VERSION ""

NS_ :

BS_:

BU_: PowertrainControlModule AtmosphericSensor SafetyRestraintSystem2 Aftertreatment_2_GasOutlet Aftertreatment_2_GasIntake DieselParticulateFilterControl Turbocharger SafetyRestraintSystem1 CabDisplay2 Aftertreatment_1_GasOutlet Aftertreatment_1_GasIntake OnBoardDataLogger OffBoardDiagnosticTool2 OffBoardDiagnosticTool1 FileServer ParkingBrakeController SeatController2 FanDriveController SteeringColumnUnit CommunicationUnitRadio CommunicationUnitSatellite CommunicationUnitCellular PropulsionBatteryCharger ChassisController2 ChassisController1 EngineValveControl AuxiliaryHeater2 AuxiliaryHeater1 ClutchUnit RampControl InformationSystem1 SuspensionSystemController2 OilSensor VehicleDynamicStability ExhaustEmissionController TransmissionDisplay2 TransmissionDisplay1 ClimateControl2 WaterPumpController RearAxleSteeringController LightingOperatorControl SeatController1 IgnitionController2 IgnitionController1 TirePressureController CabController2 CabController1 PneumaticSystemController SuspensionSystemController1 HydraulicPumpController EnduranceBrakingSystem RetarderExhaustEngine2 OnBoardDiagnosticUnit HeadwayController RetarderExhaustEngine1 CabDisplay1 ManagementComputer VirtualTerminal OffVehicleGateway PowerTakeOffFront HitchControl AuxiliaryValveControl BodyController TractorTrailerBridge1 StarterSystem ElectricalSystem VehicleSecurity VehicleNavigation AerodynamicControl ElectricalChargingSystem ClimateControl1 TripRecorder InstrumentCluster SuspensionDriveAxle2 SuspensionDriveAxle1 SuspensionSteerAxle SteeringController FuelSystem CruiseControl RetarderDriveline RetarderEngine BrakesDriveAxle2 BrakesDriveAxle1 BrakesSystemController BrakesSteerAxle AxleDrive2 AxleDrive1 AxleSteering PowerTakeOff ShiftConsoleSecondary ShiftConsolePrimary Transmission2 Transmission1 Engine2 Engine1

BO_ 2566847230 B: 8 Vector__XXX
 SG_ ParkingBrakeRedWarningSignal : 26|2@1+ (1,0) [0|3] "" Vector__XXX
 SG_ ParkBrakeReleaseInhibitStatus : 28|2@1+ (1,0) [0|3] "" Vector__XXX
 SG_ ParkingBrakeActuator : 24|2@1+ (1,0) [0|3] "" Vector__XXX
 SG_ BrakeSecondPress : 16|8@1+ (4,0) [0|1000] "kPa" Vector__XXX
 SG_ BrakePrimaryPress : 8|8@1+ (4,0) [0|1000] "kPa" Vector__XXX
 SG_ BrakeAppPress : 0|8@1+ (4,0) [0|1000] "kPa" Vector__XXX

BO_ 2566848254 AWPP: 8 Vector__XXX
 SG_ AuxPumpPress : 0|8@1+ (16,0) [0|4000] "kPa" Vector__XXX

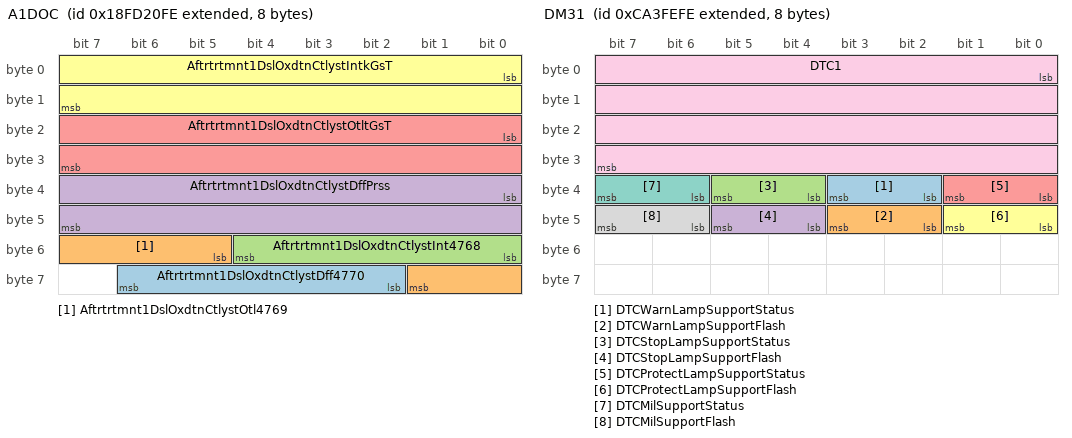
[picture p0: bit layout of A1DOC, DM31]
BO_ 2566725886 A1DOC: 8 Vector__XXX
 SG_ Aftrtrtmnt1DslOxdtnCtlystDff4770 : 58|5@1+ (1,0) [0|31] "" Vector__XXX
 SG_ Aftrtrtmnt1DslOxdtnCtlystOtl4769 : 53|5@1+ (1,0) [0|31] "" Vector__XXX
 SG_ Aftrtrtmnt1DslOxdtnCtlystInt4768 : 48|5@1+ (1,0) [0|31] "" Vector__XXX
 SG_ Aftrtrtmnt1DslOxdtnCtlystDffPrss : 32|16@1+ (0.1,0) [0|6425.5] "kPa" Vector__XXX
 SG_ Aftrtrtmnt1DslOxdtnCtlystOtltGsT : 16|16@1+ (0.03125,-273) [-273|1734.96875] "°C" Vector__XXX
 SG_ Aftrtrtmnt1DslOxdtnCtlystIntkGsT : 0|16@1+ (0.03125,-273) [-273|1734.96875] "°C" Vector__XXX

BO_ 2359557886 DM31: 8 Vector__XXX
 SG_ DTCWarnLampSupportStatus : 34|2@1+ (1,0) [0|3] "" Vector__XXX
 SG_ DTCWarnLampSupportFlash : 42|2@1+ (1,0) [0|3] "" Vector__XXX
 SG_ DTCStopLampSupportStatus : 36|2@1+ (1,0) [0|3] "" Vector__XXX
 SG_ DTCStopLampSupportFlash : 44|2@1+ (1,0) [0|3] "" Vector__XXX
 SG_ DTCProtectLampSupportStatus : 32|2@1+ (1,0) [0|3] "" Vector__XXX
 SG_ DTCProtectLampSupportFlash : 40|2@1+ (1,0) [0|3] "" Vector__XXX
 SG_ DTCMilSupportStatus : 38|2@1+ (1,0) [0|3] "" Vector__XXX
 SG_ DTCMilSupportFlash : 46|2@1+ (1,0) [0|3] "" Vector__XXX
 SG_ DTC1 : 0|32@1+ (1,0) [0|4294967295] "" Vector__XXX

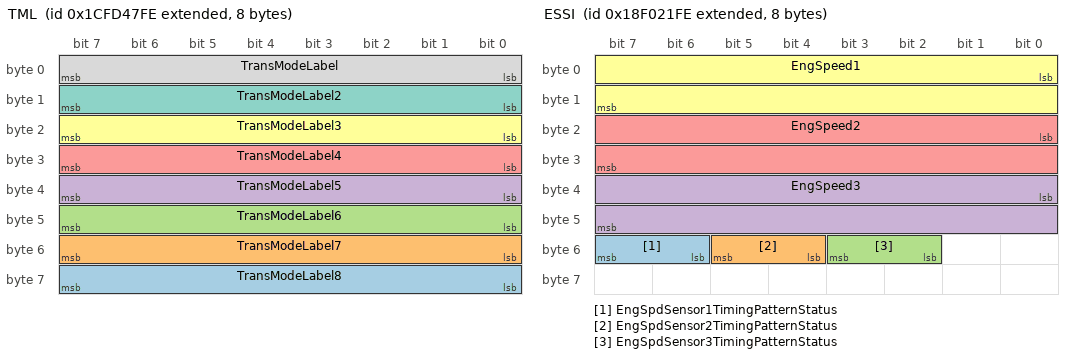
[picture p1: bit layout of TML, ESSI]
BO_ 2633844734 TML: 8 Vector__XXX
 SG_ TransModeLabel8 : 56|8@1+ (1,0) [0|255] "per byte" Vector__XXX
 SG_ TransModeLabel7 : 48|8@1+ (1,0) [0|255] "per byte" Vector__XXX
 SG_ TransModeLabel6 : 40|8@1+ (1,0) [0|255] "per byte" Vector__XXX
 SG_ TransModeLabel5 : 32|8@1+ (1,0) [0|255] "per byte" Vector__XXX
 SG_ TransModeLabel4 : 24|8@1+ (1,0) [0|255] "per byte" Vector__XXX
 SG_ TransModeLabel3 : 16|8@1+ (1,0) [0|255] "per byte" Vector__XXX
 SG_ TransModeLabel2 : 8|8@1+ (1,0) [0|255] "per byte" Vector__XXX
 SG_ TransModeLabel : 0|8@1+ (1,0) [0|255] "" Vector__XXX

BO_ 2560360190 PMI: 8 Vector__XXX
 SG_ DataDictionaryMethod : 11|21@1+ (1,0) [0|2097151] "" Vector__XXX
 SG_ DataDictionaryManufacturerCode : 0|11@1+ (1,0) [0|2047] "" Vector__XXX

BO_ 2566736126 O2FT2: 8 Vector__XXX
 SG_ EngExhstGsOxygnSnsrClsdLpOprtnBn : 32|4@1+ (1,0) [0|15] "" Vector__XXX
 SG_ ShorttermFuelTrimBank2 : 16|16@1+ (0.1,-100) [-100|100] "%" Vector__XXX
 SG_ LongtermFuelTrimBank2 : 0|16@1+ (0.1,-100) [-100|100] "%" Vector__XXX

BO_ 2566736382 O2FT1: 8 Vector__XXX
 SG_ EngExhstGsOxygnSnsrClsdLpOprtnBn : 32|4@1+ (1,0) [0|15] "" Vector__XXX
 SG_ ShorttermFuelTrimBank1 : 16|16@1+ (0.1,-100) [-100|100] "%" Vector__XXX
 SG_ LongtermFuelTrimBank1 : 0|16@1+ (0.1,-100) [-100|100] "%" Vector__XXX

BO_ 2565874174 ESSI: 8 Vector__XXX
 SG_ EngSpdSensor1TimingPatternStatus : 54|2@1+ (1,0) [0|3] "" Vector__XXX
 SG_ EngSpdSensor2TimingPatternStatus : 52|2@1+ (1,0) [0|3] "" Vector__XXX
 SG_ EngSpdSensor3TimingPatternStatus : 50|2@1+ (1,0) [0|3] "" Vector__XXX
 SG_ EngSpeed3 : 32|16@1+ (0.5,0) [0|32127.5] "rpm" Vector__XXX
 SG_ EngSpeed2 : 16|16@1+ (0.5,0) [0|32127.5] "rpm" Vector__XXX
 SG_ EngSpeed1 : 0|16@1+ (0.5,0) [0|32127.5] "rpm" Vector__XXX

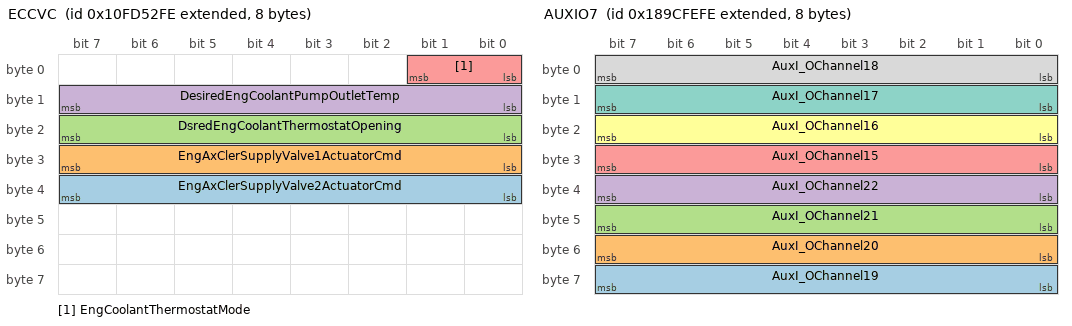
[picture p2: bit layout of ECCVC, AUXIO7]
BO_ 2432520958 ECCVC: 8 Vector__XXX
 SG_ EngAxClerSupplyValve2ActuatorCmd : 32|8@1+ (0.4,0) [0|100] "%" Vector__XXX
 SG_ EngAxClerSupplyValve1ActuatorCmd : 24|8@1+ (0.4,0) [0|100] "%" Vector__XXX
 SG_ DsredEngCoolantThermostatOpening : 16|8@1+ (0.4,0) [0|100] "%" Vector__XXX
 SG_ DesiredEngCoolantPumpOutletTemp : 8|8@1+ (1,-40) [-40|210] "°C" Vector__XXX
 SG_ EngCoolantThermostatMode : 0|2@1+ (1,0) [0|3] "" Vector__XXX

BO_ 2560425726 AUXIO7: 8 Vector__XXX
 SG_ AuxI_OChannel19 : 56|8@1+ (1,0) [0|250] "" Vector__XXX
 SG_ AuxI_OChannel20 : 48|8@1+ (1,0) [0|250] "" Vector__XXX
 SG_ AuxI_OChannel21 : 40|8@1+ (1,0) [0|250] "" Vector__XXX
 SG_ AuxI_OChannel22 : 32|8@1+ (1,0) [0|250] "" Vector__XXX
 SG_ AuxI_OChannel15 : 24|8@1+ (1,0) [0|250] "" Vector__XXX
 SG_ AuxI_OChannel16 : 16|8@1+ (1,0) [0|250] "" Vector__XXX
 SG_ AuxI_OChannel17 : 8|8@1+ (1,0) [0|250] "" Vector__XXX
 SG_ AuxI_OChannel18 : 0|8@1+ (1,0) [0|250] "" Vector__XXX

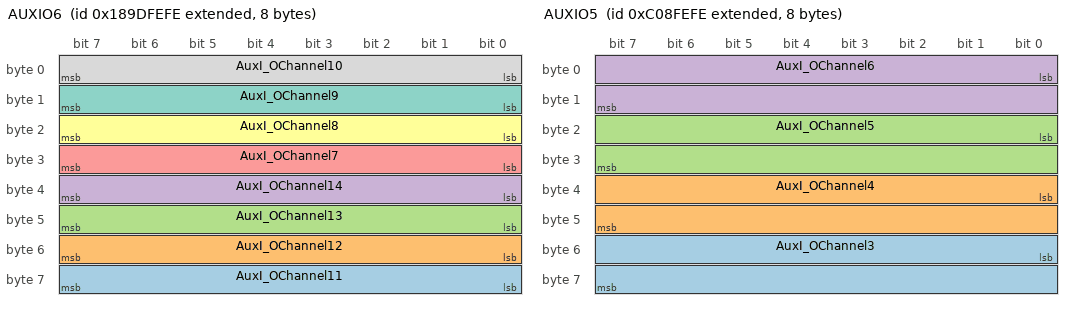
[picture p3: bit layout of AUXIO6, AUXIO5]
BO_ 2560491262 AUXIO6: 8 Vector__XXX
 SG_ AuxI_OChannel11 : 56|8@1+ (1,0) [0|250] "" Vector__XXX
 SG_ AuxI_OChannel12 : 48|8@1+ (1,0) [0|250] "" Vector__XXX
 SG_ AuxI_OChannel13 : 40|8@1+ (1,0) [0|250] "" Vector__XXX
 SG_ AuxI_OChannel14 : 32|8@1+ (1,0) [0|250] "" Vector__XXX
 SG_ AuxI_OChannel7 : 24|8@1+ (1,0) [0|250] "" Vector__XXX
 SG_ AuxI_OChannel8 : 16|8@1+ (1,0) [0|250] "" Vector__XXX
 SG_ AuxI_OChannel9 : 8|8@1+ (1,0) [0|250] "" Vector__XXX
 SG_ AuxI_OChannel10 : 0|8@1+ (1,0) [0|250] "" Vector__XXX

BO_ 2349399806 AUXIO5: 8 Vector__XXX
 SG_ AuxI_OChannel3 : 48|16@1+ (1,0) [0|64255] "" Vector__XXX
 SG_ AuxI_OChannel4 : 32|16@1+ (1,0) [0|64255] "" Vector__XXX
 SG_ AuxI_OChannel5 : 16|16@1+ (1,0) [0|64255] "" Vector__XXX
 SG_ AuxI_OChannel6 : 0|16@1+ (1,0) [0|64255] "" Vector__XXX

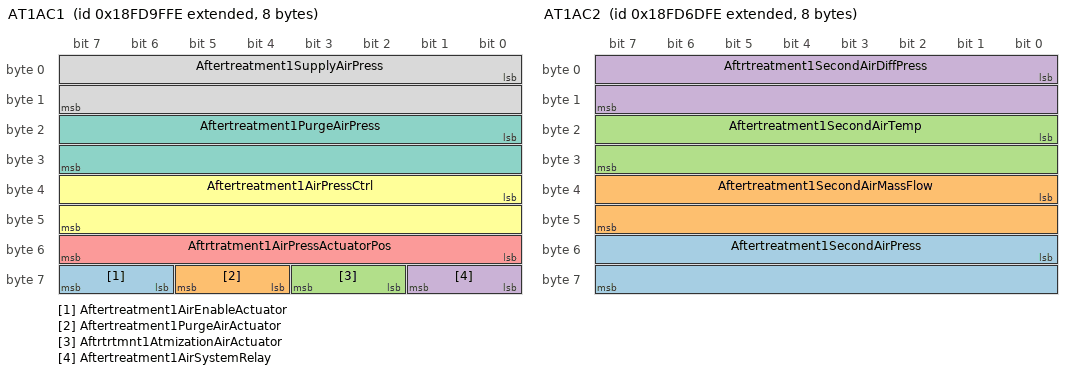
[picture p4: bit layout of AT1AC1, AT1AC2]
BO_ 2566758398 AT1AC1: 8 Vector__XXX
 SG_ Aftertreatment1AirEnableActuator : 62|2@1+ (1,0) [0|3] "" Vector__XXX
 SG_ Aftertreatment1PurgeAirActuator : 60|2@1+ (1,0) [0|3] "" Vector__XXX
 SG_ Aftrtrtmnt1AtmizationAirActuator : 58|2@1+ (1,0) [0|3] "" Vector__XXX
 SG_ Aftertreatment1AirSystemRelay : 56|2@1+ (1,0) [0|3] "" Vector__XXX
 SG_ Aftrtratment1AirPressActuatorPos : 48|8@1+ (0.4,0) [0|100] "%" Vector__XXX
 SG_ Aftertreatment1AirPressCtrl : 32|16@1+ (0.0025,0) [0|160.6375] "%" Vector__XXX
 SG_ Aftertreatment1PurgeAirPress : 16|16@1+ (0.1,0) [0|6425.5] "kPa" Vector__XXX
 SG_ Aftertreatment1SupplyAirPress : 0|16@1+ (0.1,0) [0|6425.5] "kPa" Vector__XXX

BO_ 2566745598 AT1AC2: 8 Vector__XXX
 SG_ Aftertreatment1SecondAirPress : 48|16@1+ (0.1,0) [0|6425.5] "kPa" Vector__XXX
 SG_ Aftertreatment1SecondAirMassFlow : 32|16@1+ (0.2,0) [0|12851] "kg/h" Vector__XXX
 SG_ Aftertreatment1SecondAirTemp : 16|16@1+ (0.03125,-273) [-273|1734.96875] "°C" Vector__XXX
 SG_ Aftrtreatment1SecondAirDiffPress : 0|16@1+ (0.0078125,-250) [-250|251.99] "kPa" Vector__XXX

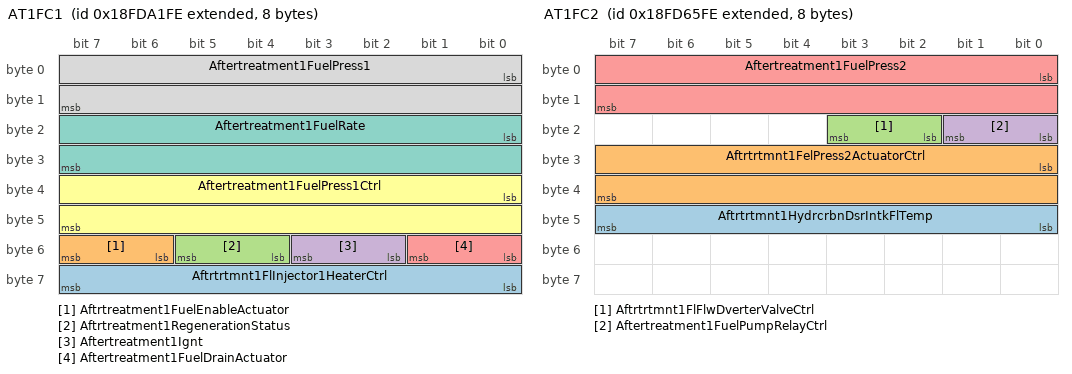
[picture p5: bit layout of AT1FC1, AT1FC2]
BO_ 2566758910 AT1FC1: 8 Vector__XXX
 SG_ Aftrtrtmnt1FlInjector1HeaterCtrl : 56|8@1+ (0.4,0) [0|100] "%" Vector__XXX
 SG_ Aftrtreatment1FuelEnableActuator : 54|2@1+ (1,0) [0|3] "" Vector__XXX
 SG_ Aftrtreatment1RegenerationStatus : 52|2@1+ (1,0) [0|3] "" Vector__XXX
 SG_ Aftertreatment1Ignt : 50|2@1+ (1,0) [0|3] "" Vector__XXX
 SG_ Aftertreatment1FuelDrainActuator : 48|2@1+ (1,0) [0|3] "" Vector__XXX
 SG_ Aftertreatment1FuelPress1Ctrl : 32|16@1+ (0.0025,0) [0|160.6375] "%" Vector__XXX
 SG_ Aftertreatment1FuelRate : 16|16@1+ (0.05,0) [0|3212.75] "L/h" Vector__XXX
 SG_ Aftertreatment1FuelPress1 : 0|16@1+ (0.1,0) [0|6425.5] "kPa" Vector__XXX

BO_ 2566743550 AT1FC2: 8 Vector__XXX
 SG_ Aftrtrtmnt1HydrcrbnDsrIntkFlTemp : 40|8@1+ (1,-40) [-40|210] "°C" Vector__XXX
 SG_ Aftrtrtmnt1FelPress2ActuatorCtrl : 24|16@1+ (0.0025,0) [0|160.6375] "%" Vector__XXX
 SG_ Aftrtrtmnt1FlFlwDverterValveCtrl : 18|2@1+ (1,0) [0|3] "" Vector__XXX
 SG_ Aftertreatment1FuelPumpRelayCtrl : 16|2@1+ (1,0) [0|3] "" Vector__XXX
 SG_ Aftertreatment1FuelPress2 : 0|16@1+ (0.1,0) [0|6425.5] "kPa" Vector__XXX

BO_ 2566753534 AT1GP: 8 Vector__XXX
 SG_ DslParticulateFilterOutletPress1 : 16|16@1+ (0.1,0) [0|6425.5] "kPa" Vector__XXX
 SG_ DslParticulateFilterIntakePress1 : 0|16@1+ (0.1,0) [0|6425.5] "kPa" Vector__XXX

BO_ 2566756606 AT1HI: 8 Vector__XXX
 SG_ Aftrtrtmnt1AvrgDstncBtwnActvDPFR : 288|32@1+ (0.125,0) [0|526385151.875] "km" Vector__XXX
 SG_ Aftrtrtmnt1AvrgTmBtwnActvRgnrtns : 256|32@1+ (1,0) [0|4211081215] "s" Vector__XXX
 SG_ Aftrtrtmnt1DslPrtcltFltrTtlN3728 : 224|32@1+ (1,0) [0|4211081215] "" Vector__XXX
 SG_ Aftrtrtmnt1DslPrtcltFltrTtlN3727 : 192|32@1+ (1,0) [0|4211081215] "" Vector__XXX
 SG_ Aftrtrtmnt1DslPrtcltFltrTtlNmbrO : 160|32@1+ (1,0) [0|4211081215] "" Vector__XXX
 SG_ Aftrtrtmnt1DslPrtcltFltrTtlPssvR : 128|32@1+ (1,0) [0|4211081215] "s" Vector__XXX
 SG_ Aftrtrtmnt1TtlNmbrOfActvRgnrtons : 96|32@1+ (1,0) [0|4211081215] "" Vector__XXX
 SG_ Aftertreatment1TotalDisabledTime : 64|32@1+ (1,0) [0|4211081215] "s" Vector__XXX
 SG_ Aftrtrtmnt1TotalRegenerationTime : 32|32@1+ (1,0) [0|4211081215] "s" Vector__XXX
 SG_ Aftertreatment1TotalFuelUsed : 0|32@1+ (0.5,0) [0|2105540607.5] "L" Vector__XXX

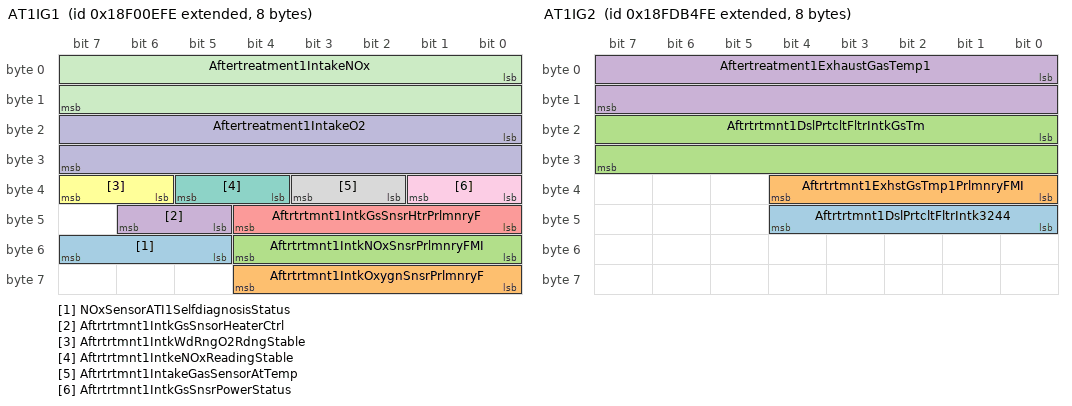
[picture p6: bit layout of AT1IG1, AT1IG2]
BO_ 2565869310 AT1IG1: 8 Vector__XXX
 SG_ NOxSensorATI1SelfdiagnosisStatus : 53|3@1+ (1,0) [0|7] "" Vector__XXX
 SG_ Aftrtrtmnt1IntkOxygnSnsrPrlmnryF : 56|5@1+ (1,0) [0|31] "" Vector__XXX
 SG_ Aftrtrtmnt1IntkNOxSnsrPrlmnryFMI : 48|5@1+ (1,0) [0|31] "" Vector__XXX
 SG_ Aftrtrtmnt1IntkGsSnsorHeaterCtrl : 45|2@1+ (1,0) [0|3] "" Vector__XXX
 SG_ Aftrtrtmnt1IntkGsSnsrHtrPrlmnryF : 40|5@1+ (1,0) [0|31] "" Vector__XXX
 SG_ Aftrtrtmnt1IntkWdRngO2RdngStable : 38|2@1+ (1,0) [0|3] "" Vector__XXX
 SG_ Aftrtrtmnt1IntkeNOxReadingStable : 36|2@1+ (1,0) [0|3] "" Vector__XXX
 SG_ Aftrtrtmnt1IntakeGasSensorAtTemp : 34|2@1+ (1,0) [0|3] "" Vector__XXX
 SG_ Aftrtrtmnt1IntkGsSnsrPowerStatus : 32|2@1+ (1,0) [0|3] "" Vector__XXX
 SG_ Aftertreatment1IntakeO2 : 16|16@1+ (0.000514,-12) [-12|21.02707] "%" Vector__XXX
 SG_ Aftertreatment1IntakeNOx : 0|16@1+ (0.05,-200) [-200|3012.75] "ppm" Vector__XXX

BO_ 2566763774 AT1IG2: 8 Vector__XXX
 SG_ Aftrtrtmnt1DslPrtcltFltrIntk3244 : 40|5@1+ (1,0) [0|31] "" Vector__XXX
 SG_ Aftrtrtmnt1ExhstGsTmp1PrlmnryFMI : 32|5@1+ (1,0) [0|31] "" Vector__XXX
 SG_ Aftrtrtmnt1DslPrtcltFltrIntkGsTm : 16|16@1+ (0.03125,-273) [-273|1734.96875] "°C" Vector__XXX
 SG_ Aftertreatment1ExhaustGasTemp1 : 0|16@1+ (0.03125,-273) [-273|1734.96875] "°C" Vector__XXX

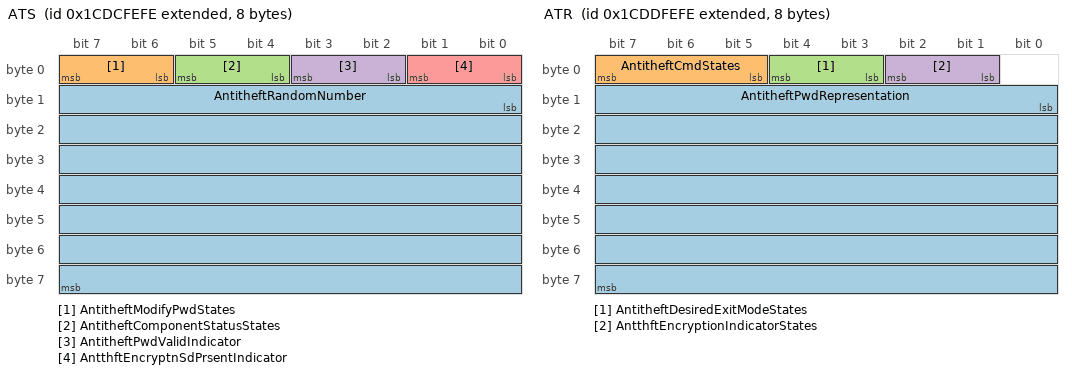
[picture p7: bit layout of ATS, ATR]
BO_ 2631728894 ATS: 8 Vector__XXX
 SG_ AntitheftRandomNumber : 8|56@1+ (1,0) [0|255] "" Vector__XXX
 SG_ AntitheftModifyPwdStates : 6|2@1+ (1,0) [0|3] "" Vector__XXX
 SG_ AntitheftComponentStatusStates : 4|2@1+ (1,0) [0|3] "" Vector__XXX
 SG_ AntitheftPwdValidIndicator : 2|2@1+ (1,0) [0|3] "" Vector__XXX
 SG_ AntthftEncryptnSdPrsentIndicator : 0|2@1+ (1,0) [0|3] "" Vector__XXX

BO_ 2631794430 ATR: 8 Vector__XXX
 SG_ AntitheftPwdRepresentation : 8|56@1+ (1,0) [0|255] "" Vector__XXX
 SG_ AntitheftCmdStates : 5|3@1+ (1,0) [0|7] "" Vector__XXX
 SG_ AntitheftDesiredExitModeStates : 3|2@1+ (1,0) [0|3] "" Vector__XXX
 SG_ AntthftEncryptionIndicatorStates : 1|2@1+ (1,0) [0|3] "" Vector__XXX

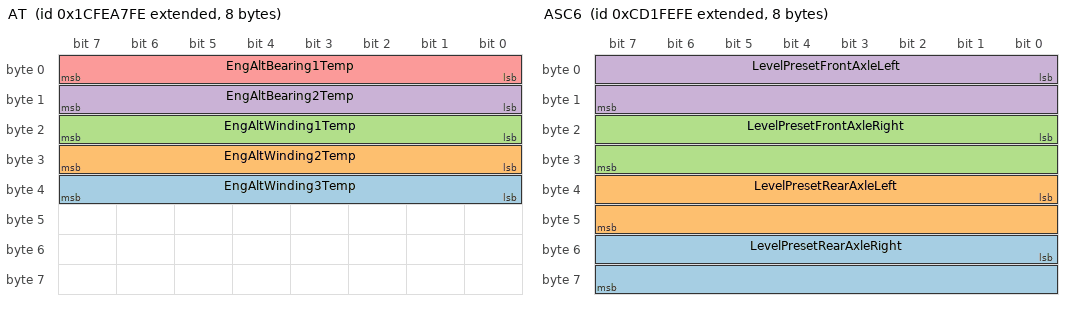
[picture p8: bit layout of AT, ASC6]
BO_ 2633934846 AT: 8 Vector__XXX
 SG_ EngAltWinding3Temp : 32|8@1+ (1,-40) [-40|210] "°C" Vector__XXX
 SG_ EngAltWinding2Temp : 24|8@1+ (1,-40) [-40|210] "°C" Vector__XXX
 SG_ EngAltWinding1Temp : 16|8@1+ (1,-40) [-40|210] "°C" Vector__XXX
 SG_ EngAltBearing2Temp : 8|8@1+ (1,-40) [-40|210] "°C" Vector__XXX
 SG_ EngAltBearing1Temp : 0|8@1+ (1,-40) [-40|210] "°C" Vector__XXX

BO_ 2362572542 ASC6: 8 Vector__XXX
 SG_ LevelPresetRearAxleRight : 48|16@1+ (0.1,-3200) [-3200|3225.5] "mm" Vector__XXX
 SG_ LevelPresetRearAxleLeft : 32|16@1+ (0.1,-3200) [-3200|3225.5] "mm" Vector__XXX
 SG_ LevelPresetFrontAxleRight : 16|16@1+ (0.1,-3200) [-3200|3225.5] "mm" Vector__XXX
 SG_ LevelPresetFrontAxleLeft : 0|16@1+ (0.1,-3200) [-3200|3225.5] "mm" Vector__XXX

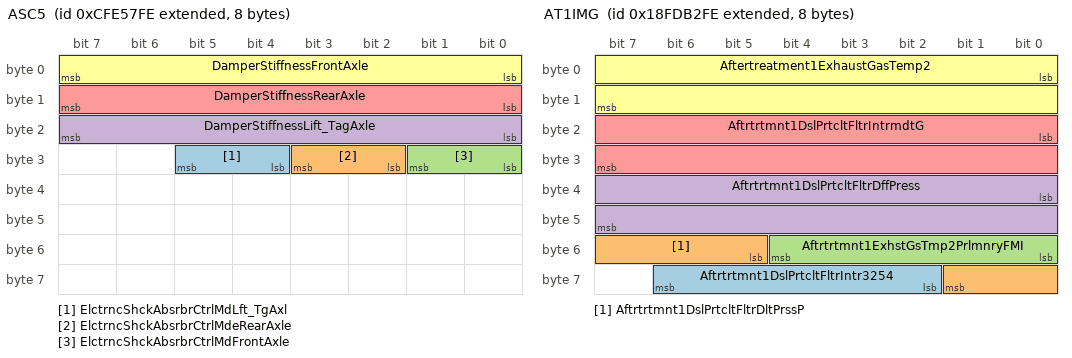
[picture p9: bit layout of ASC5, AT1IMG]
BO_ 2365478910 ASC5: 8 Vector__XXX
 SG_ ElctrncShckAbsrbrCtrlMdLft_TgAxl : 28|2@1+ (1,0) [0|3] "" Vector__XXX
 SG_ ElctrncShckAbsrbrCtrlMdeRearAxle : 26|2@1+ (1,0) [0|3] "" Vector__XXX
 SG_ ElctrncShckAbsrbrCtrlMdFrontAxle : 24|2@1+ (1,0) [0|3] "" Vector__XXX
 SG_ DamperStiffnessLift_TagAxle : 16|8@1+ (0.4,0) [0|100] "%" Vector__XXX
 SG_ DamperStiffnessRearAxle : 8|8@1+ (0.4,0) [0|100] "%" Vector__XXX
 SG_ DamperStiffnessFrontAxle : 0|8@1+ (0.4,0) [0|100] "%" Vector__XXX

BO_ 2560950014 DM30: 12 Vector__XXX
 SG_ SPN1 : 8|16@1+ (1,0) [0|65536] "" Vector__XXX
 SG_ TestLimitMinimum : 80|16@1+ (1,0) [0|64255] "" Vector__XXX
 SG_ FailureModeIdentifier1 : 24|5@1+ (1,0) [0|0] "" Vector__XXX
 SG_ TestLimitMaximum : 64|16@1+ (1,0) [0|64255] "" Vector__XXX
 SG_ TestValue : 48|16@1+ (1,0) [0|64255] "" Vector__XXX
 SG_ SlotId : 32|16@1+ (1,0) [0|64255] "" Vector__XXX
 SG_ TestIdentifier : 0|8@1+ (1,0) [0|255] "" Vector__XXX
 SG_ SPN1High : 29|3@1+ (1,0) [0|7] "" Vector__XXX

BO_ 2566763262 AT1IMG: 8 Vector__XXX
 SG_ Aftrtrtmnt1DslPrtcltFltrIntr3254 : 58|5@1+ (1,0) [0|31] "" Vector__XXX
 SG_ Aftrtrtmnt1DslPrtcltFltrDltPrssP : 53|5@1+ (1,0) [0|31] "" Vector__XXX
 SG_ Aftrtrtmnt1ExhstGsTmp2PrlmnryFMI : 48|5@1+ (1,0) [0|31] "" Vector__XXX
 SG_ Aftrtrtmnt1DslPrtcltFltrDffPress : 32|16@1+ (0.1,0) [0|6425.5] "kPa" Vector__XXX
 SG_ Aftrtrtmnt1DslPrtcltFltrIntrmdtG : 16|16@1+ (0.03125,-273) [-273|1734.96875] "°C" Vector__XXX
 SG_ Aftertreatment1ExhaustGasTemp2 : 0|16@1+ (0.03125,-273) [-273|1734.96875] "°C" Vector__XXX

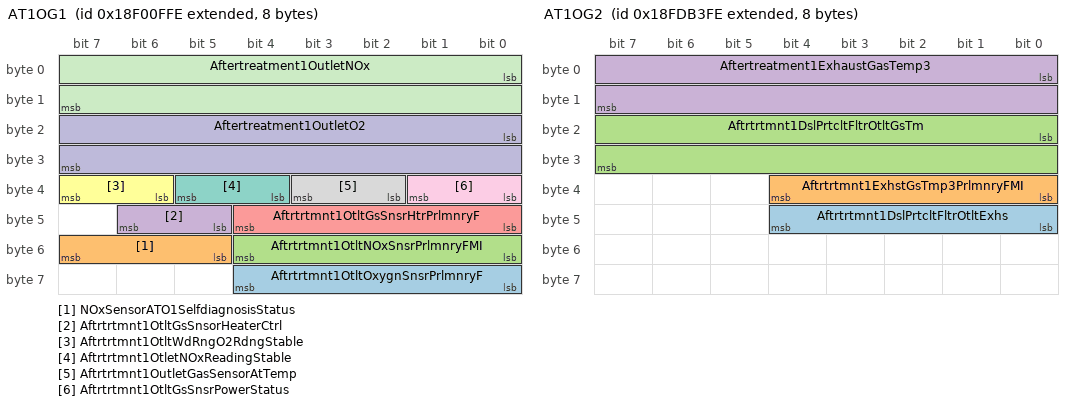
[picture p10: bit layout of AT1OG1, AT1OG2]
BO_ 2565869566 AT1OG1: 8 Vector__XXX
 SG_ Aftrtrtmnt1OtltOxygnSnsrPrlmnryF : 56|5@1+ (1,0) [0|31] "" Vector__XXX
 SG_ NOxSensorATO1SelfdiagnosisStatus : 53|3@1+ (1,0) [0|7] "" Vector__XXX
 SG_ Aftrtrtmnt1OtltNOxSnsrPrlmnryFMI : 48|5@1+ (1,0) [0|31] "" Vector__XXX
 SG_ Aftrtrtmnt1OtltGsSnsorHeaterCtrl : 45|2@1+ (1,0) [0|3] "" Vector__XXX
 SG_ Aftrtrtmnt1OtltGsSnsrHtrPrlmnryF : 40|5@1+ (1,0) [0|31] "" Vector__XXX
 SG_ Aftrtrtmnt1OtltWdRngO2RdngStable : 38|2@1+ (1,0) [0|3] "" Vector__XXX
 SG_ Aftrtrtmnt1OtletNOxReadingStable : 36|2@1+ (1,0) [0|3] "" Vector__XXX
 SG_ Aftrtrtmnt1OutletGasSensorAtTemp : 34|2@1+ (1,0) [0|3] "" Vector__XXX
 SG_ Aftrtrtmnt1OtltGsSnsrPowerStatus : 32|2@1+ (1,0) [0|3] "" Vector__XXX
 SG_ Aftertreatment1OutletO2 : 16|16@1+ (0.000514,-12) [-12|21.02707] "%" Vector__XXX
 SG_ Aftertreatment1OutletNOx : 0|16@1+ (0.05,-200) [-200|3012.75] "ppm" Vector__XXX

BO_ 2566763518 AT1OG2: 8 Vector__XXX
 SG_ Aftrtrtmnt1DslPrtcltFltrOtltExhs : 40|5@1+ (1,0) [0|31] "" Vector__XXX
 SG_ Aftrtrtmnt1ExhstGsTmp3PrlmnryFMI : 32|5@1+ (1,0) [0|31] "" Vector__XXX
 SG_ Aftrtrtmnt1DslPrtcltFltrOtltGsTm : 16|16@1+ (0.03125,-273) [-273|1734.96875] "°C" Vector__XXX
 SG_ Aftertreatment1ExhaustGasTemp3 : 0|16@1+ (0.03125,-273) [-273|1734.96875] "°C" Vector__XXX

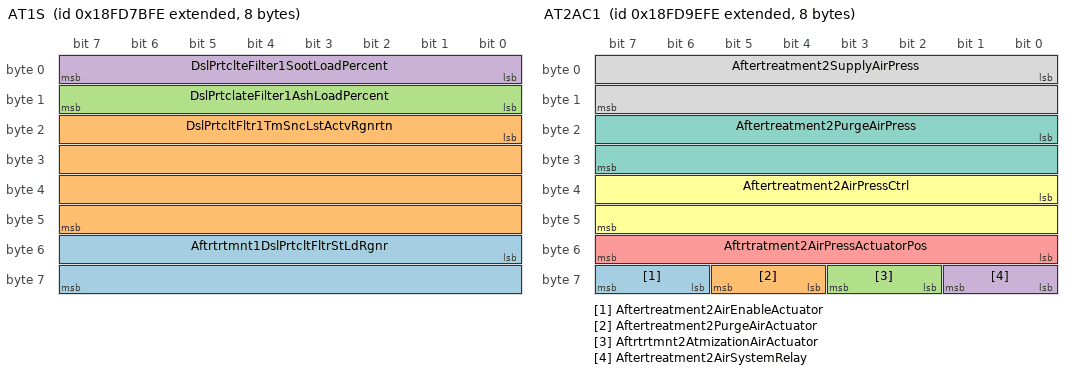
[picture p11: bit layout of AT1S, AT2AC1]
BO_ 2566749182 AT1S: 8 Vector__XXX
 SG_ Aftrtrtmnt1DslPrtcltFltrStLdRgnr : 48|16@1+ (0.0025,0) [0|160.6375] "%" Vector__XXX
 SG_ DslPrtcltFltr1TmSncLstActvRgnrtn : 16|32@1+ (1,0) [0|4211081215] "s" Vector__XXX
 SG_ DslPrtclateFilter1AshLoadPercent : 8|8@1+ (1,0) [0|250] "%" Vector__XXX
 SG_ DslPrtclteFilter1SootLoadPercent : 0|8@1+ (1,0) [0|250] "%" Vector__XXX

BO_ 2566748670 AT1TI: 32 Vector__XXX
 SG_ Aftrtrtmnt1DslPrtcltFltrTrpN3740 : 224|32@1+ (1,0) [0|4211081215] "" Vector__XXX
 SG_ Aftrtrtmnt1DslPrtcltFltrTrpN3739 : 192|32@1+ (1,0) [0|4211081215] "" Vector__XXX
 SG_ Aftrtrtmnt1DslPrtcltFltrTrpN3738 : 160|32@1+ (1,0) [0|4211081215] "" Vector__XXX
 SG_ Aftrtrtmnt1DslPrtcltFltrTrpPssvR : 128|32@1+ (1,0) [0|4211081215] "s" Vector__XXX
 SG_ Aftrtrtmnt1DslPrtcltFltrTrpNmbrO : 96|32@1+ (1,0) [0|4211081215] "" Vector__XXX
 SG_ Aftrtrtmnt1DslPrtcltFltrTrpDsbld : 64|32@1+ (1,0) [0|4211081215] "s" Vector__XXX
 SG_ Aftrtrtmnt1DslPrtcltFltrTrpActvR : 32|32@1+ (1,0) [0|4211081215] "s" Vector__XXX
 SG_ Aftrtrtmnt1DslPrtcltFltrTrpFlUsd : 0|32@1+ (0.5,0) [0|2105540607.5] "L" Vector__XXX

BO_ 2566758142 AT2AC1: 8 Vector__XXX
 SG_ Aftertreatment2AirEnableActuator : 62|2@1+ (1,0) [0|3] "" Vector__XXX
 SG_ Aftertreatment2PurgeAirActuator : 60|2@1+ (1,0) [0|3] "" Vector__XXX
 SG_ Aftrtrtmnt2AtmizationAirActuator : 58|2@1+ (1,0) [0|3] "" Vector__XXX
 SG_ Aftertreatment2AirSystemRelay : 56|2@1+ (1,0) [0|3] "" Vector__XXX
 SG_ Aftrtratment2AirPressActuatorPos : 48|8@1+ (0.4,0) [0|100] "%" Vector__XXX
 SG_ Aftertreatment2AirPressCtrl : 32|16@1+ (0.0025,0) [0|160.6375] "%" Vector__XXX
 SG_ Aftertreatment2PurgeAirPress : 16|16@1+ (0.1,0) [0|6425.5] "kPa" Vector__XXX
 SG_ Aftertreatment2SupplyAirPress : 0|16@1+ (0.1,0) [0|6425.5] "kPa" Vector__XXX

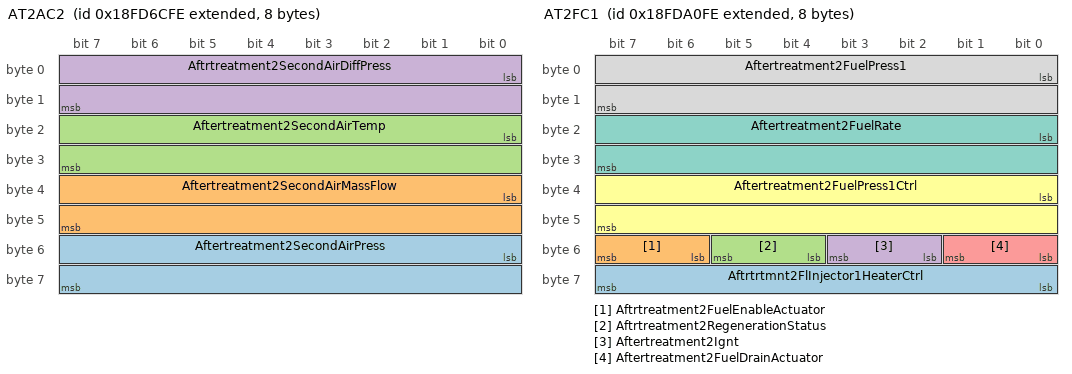
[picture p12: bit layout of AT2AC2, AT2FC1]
BO_ 2566745342 AT2AC2: 8 Vector__XXX
 SG_ Aftertreatment2SecondAirPress : 48|16@1+ (0.1,0) [0|6425.5] "kPa" Vector__XXX
 SG_ Aftertreatment2SecondAirMassFlow : 32|16@1+ (0.2,0) [0|12851] "kg/h" Vector__XXX
 SG_ Aftertreatment2SecondAirTemp : 16|16@1+ (0.03125,-273) [-273|1734.96875] "°C" Vector__XXX
 SG_ Aftrtreatment2SecondAirDiffPress : 0|16@1+ (0.0078125,-250) [-250|251.99] "kPa" Vector__XXX

BO_ 2566758654 AT2FC1: 8 Vector__XXX
 SG_ Aftrtrtmnt2FlInjector1HeaterCtrl : 56|8@1+ (0.4,0) [0|100] "%" Vector__XXX
 SG_ Aftrtreatment2FuelEnableActuator : 54|2@1+ (1,0) [0|3] "" Vector__XXX
 SG_ Aftrtreatment2RegenerationStatus : 52|2@1+ (1,0) [0|3] "" Vector__XXX
 SG_ Aftertreatment2Ignt : 50|2@1+ (1,0) [0|3] "" Vector__XXX
 SG_ Aftertreatment2FuelDrainActuator : 48|2@1+ (1,0) [0|3] "" Vector__XXX
 SG_ Aftertreatment2FuelPress1Ctrl : 32|16@1+ (0.0025,0) [0|160.6375] "%" Vector__XXX
 SG_ Aftertreatment2FuelRate : 16|16@1+ (0.05,0) [0|3212.75] "L/h" Vector__XXX
 SG_ Aftertreatment2FuelPress1 : 0|16@1+ (0.1,0) [0|6425.5] "kPa" Vector__XXX

BO_ 2566753278 AT2GP: 8 Vector__XXX
 SG_ DslParticulateFilterOutletPress2 : 16|16@1+ (0.1,0) [0|6425.5] "kPa" Vector__XXX
 SG_ DslParticulateFilterIntakePress2 : 0|16@1+ (0.1,0) [0|6425.5] "kPa" Vector__XXX

BO_ 2566756862 AT2HI: 8 Vector__XXX
 SG_ Aftrtrtmnt2AvrgDstncBtwnActvDPFR : 288|32@1+ (0.125,0) [0|526385151.875] "km" Vector__XXX
 SG_ Aftrtrtmnt2AvrgTmBtwnActvRgnrtns : 256|32@1+ (1,0) [0|4211081215] "s" Vector__XXX
 SG_ Aftrtrtmnt2DslPrtcltFltrTtlN3732 : 224|32@1+ (1,0) [0|4211081215] "" Vector__XXX
 SG_ Aftrtrtmnt2DslPrtcltFltrTtlN3731 : 192|32@1+ (1,0) [0|4211081215] "" Vector__XXX
 SG_ Aftrtrtmnt2DslPrtcltFltrTtlNmbrO : 160|32@1+ (1,0) [0|4211081215] "" Vector__XXX
 SG_ Aftrtrtmnt2DslPrtcltFltrTtlPssvR : 128|32@1+ (1,0) [0|4211081215] "s" Vector__XXX
 SG_ Aftrtrtmnt2TtlNmbrOfActvRgnrtons : 96|32@1+ (1,0) [0|4211081215] "" Vector__XXX
 SG_ Aftertreatment2TotalDisabledTime : 64|32@1+ (1,0) [0|4211081215] "s" Vector__XXX
 SG_ Aftrtrtmnt2TotalRegenerationTime : 32|32@1+ (1,0) [0|4211081215] "s" Vector__XXX
 SG_ Aftertreatment2TotalFuelUsed : 0|32@1+ (0.5,0) [0|2105540607.5] "L" Vector__XXX

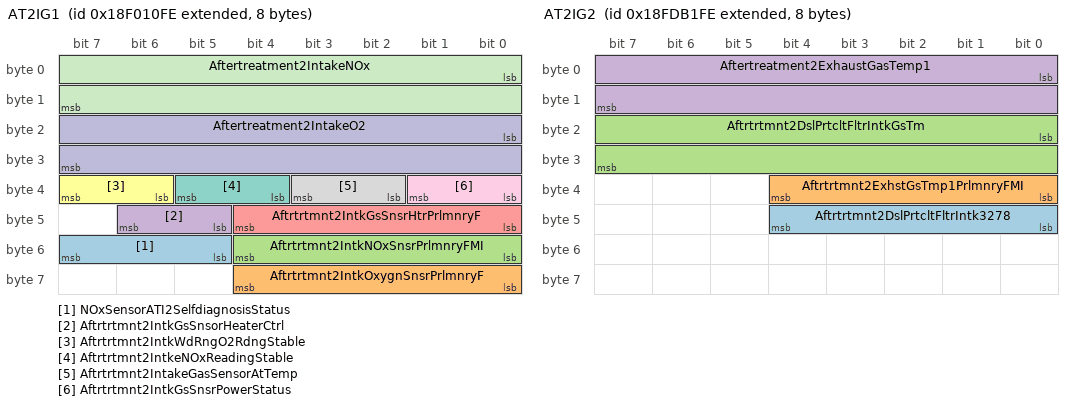
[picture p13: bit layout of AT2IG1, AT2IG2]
BO_ 2565869822 AT2IG1: 8 Vector__XXX
 SG_ NOxSensorATI2SelfdiagnosisStatus : 53|3@1+ (1,0) [0|7] "" Vector__XXX
 SG_ Aftrtrtmnt2IntkOxygnSnsrPrlmnryF : 56|5@1+ (1,0) [0|31] "" Vector__XXX
 SG_ Aftrtrtmnt2IntkNOxSnsrPrlmnryFMI : 48|5@1+ (1,0) [0|31] "" Vector__XXX
 SG_ Aftrtrtmnt2IntkGsSnsorHeaterCtrl : 45|2@1+ (1,0) [0|3] "" Vector__XXX
 SG_ Aftrtrtmnt2IntkGsSnsrHtrPrlmnryF : 40|5@1+ (1,0) [0|31] "" Vector__XXX
 SG_ Aftrtrtmnt2IntkWdRngO2RdngStable : 38|2@1+ (1,0) [0|3] "" Vector__XXX
 SG_ Aftrtrtmnt2IntkeNOxReadingStable : 36|2@1+ (1,0) [0|3] "" Vector__XXX
 SG_ Aftrtrtmnt2IntakeGasSensorAtTemp : 34|2@1+ (1,0) [0|3] "" Vector__XXX
 SG_ Aftrtrtmnt2IntkGsSnsrPowerStatus : 32|2@1+ (1,0) [0|3] "" Vector__XXX
 SG_ Aftertreatment2IntakeO2 : 16|16@1+ (0.000514,-12) [-12|21.02707] "%" Vector__XXX
 SG_ Aftertreatment2IntakeNOx : 0|16@1+ (0.05,-200) [-200|3012.75] "ppm" Vector__XXX

BO_ 2566763006 AT2IG2: 8 Vector__XXX
 SG_ Aftrtrtmnt2DslPrtcltFltrIntk3278 : 40|5@1+ (1,0) [0|31] "" Vector__XXX
 SG_ Aftrtrtmnt2ExhstGsTmp1PrlmnryFMI : 32|5@1+ (1,0) [0|31] "" Vector__XXX
 SG_ Aftrtrtmnt2DslPrtcltFltrIntkGsTm : 16|16@1+ (0.03125,-273) [-273|1734.96875] "°C" Vector__XXX
 SG_ Aftertreatment2ExhaustGasTemp1 : 0|16@1+ (0.03125,-273) [-273|1734.96875] "°C" Vector__XXX

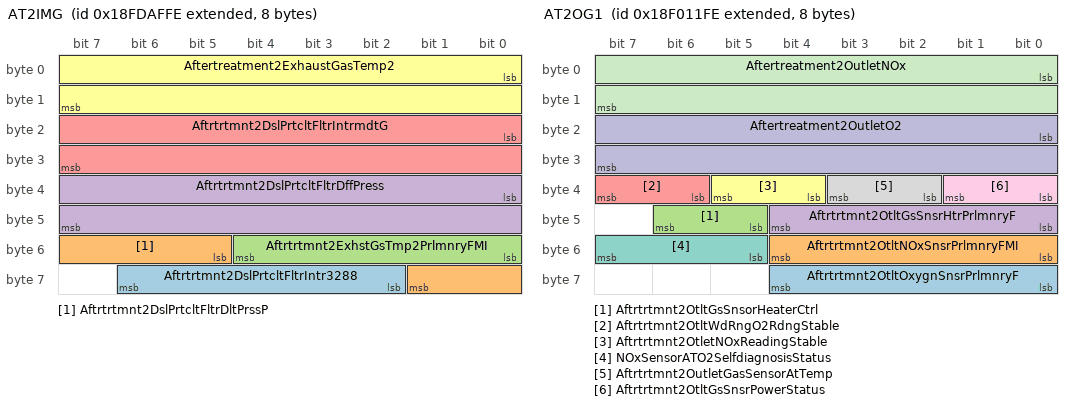
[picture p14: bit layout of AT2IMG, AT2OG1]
BO_ 2566762494 AT2IMG: 8 Vector__XXX
 SG_ Aftrtrtmnt2DslPrtcltFltrIntr3288 : 58|5@1+ (1,0) [0|31] "" Vector__XXX
 SG_ Aftrtrtmnt2DslPrtcltFltrDltPrssP : 53|5@1+ (1,0) [0|31] "" Vector__XXX
 SG_ Aftrtrtmnt2ExhstGsTmp2PrlmnryFMI : 48|5@1+ (1,0) [0|31] "" Vector__XXX
 SG_ Aftrtrtmnt2DslPrtcltFltrDffPress : 32|16@1+ (0.1,0) [0|6425.5] "kPa" Vector__XXX
 SG_ Aftrtrtmnt2DslPrtcltFltrIntrmdtG : 16|16@1+ (0.03125,-273) [-273|1734.96875] "°C" Vector__XXX
 SG_ Aftertreatment2ExhaustGasTemp2 : 0|16@1+ (0.03125,-273) [-273|1734.96875] "°C" Vector__XXX

BO_ 2565870078 AT2OG1: 8 Vector__XXX
 SG_ Aftrtrtmnt2OtltOxygnSnsrPrlmnryF : 56|5@1+ (1,0) [0|31] "" Vector__XXX
 SG_ Aftrtrtmnt2OtltNOxSnsrPrlmnryFMI : 48|5@1+ (1,0) [0|31] "" Vector__XXX
 SG_ Aftrtrtmnt2OtltGsSnsorHeaterCtrl : 45|2@1+ (1,0) [0|3] "" Vector__XXX
 SG_ Aftrtrtmnt2OtltGsSnsrHtrPrlmnryF : 40|5@1+ (1,0) [0|31] "" Vector__XXX
 SG_ Aftrtrtmnt2OtltWdRngO2RdngStable : 38|2@1+ (1,0) [0|3] "" Vector__XXX
 SG_ Aftrtrtmnt2OtletNOxReadingStable : 36|2@1+ (1,0) [0|3] "" Vector__XXX
 SG_ NOxSensorATO2SelfdiagnosisStatus : 53|3@1+ (1,0) [0|7] "" Vector__XXX
 SG_ Aftrtrtmnt2OutletGasSensorAtTemp : 34|2@1+ (1,0) [0|3] "" Vector__XXX
 SG_ Aftrtrtmnt2OtltGsSnsrPowerStatus : 32|2@1+ (1,0) [0|3] "" Vector__XXX
 SG_ Aftertreatment2OutletO2 : 16|16@1+ (0.000514,-12) [-12|21.02707] "%" Vector__XXX
 SG_ Aftertreatment2OutletNOx : 0|16@1+ (0.05,-200) [-200|3012.75] "ppm" Vector__XXX

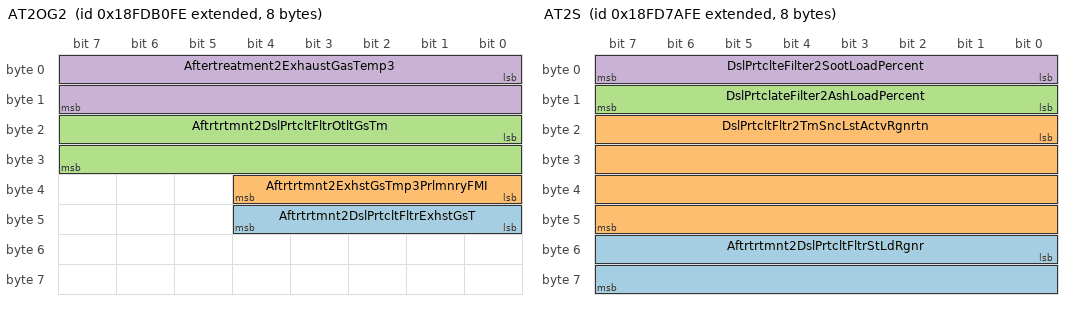
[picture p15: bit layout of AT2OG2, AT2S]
BO_ 2566762750 AT2OG2: 8 Vector__XXX
 SG_ Aftrtrtmnt2DslPrtcltFltrExhstGsT : 40|5@1+ (1,0) [0|31] "" Vector__XXX
 SG_ Aftrtrtmnt2ExhstGsTmp3PrlmnryFMI : 32|5@1+ (1,0) [0|31] "" Vector__XXX
 SG_ Aftrtrtmnt2DslPrtcltFltrOtltGsTm : 16|16@1+ (0.03125,-273) [-273|1734.96875] "°C" Vector__XXX
 SG_ Aftertreatment2ExhaustGasTemp3 : 0|16@1+ (0.03125,-273) [-273|1734.96875] "°C" Vector__XXX

BO_ 2566748926 AT2S: 8 Vector__XXX
 SG_ Aftrtrtmnt2DslPrtcltFltrStLdRgnr : 48|16@1+ (0.0025,0) [0|160.6375] "%" Vector__XXX
 SG_ DslPrtcltFltr2TmSncLstActvRgnrtn : 16|32@1+ (1,0) [0|4211081215] "s" Vector__XXX
 SG_ DslPrtclateFilter2AshLoadPercent : 8|8@1+ (1,0) [0|250] "%" Vector__XXX
 SG_ DslPrtclteFilter2SootLoadPercent : 0|8@1+ (1,0) [0|250] "%" Vector__XXX

BO_ 2566748414 AT2TI: 32 Vector__XXX
 SG_ Aftrtrtmnt2DslPrtcltFltrTrpN3748 : 224|32@1+ (1,0) [0|4211081215] "" Vector__XXX
 SG_ Aftrtrtmnt2DslPrtcltFltrTrpN3747 : 192|32@1+ (1,0) [0|4211081215] "" Vector__XXX
 SG_ Aftrtrtmnt2DslPrtcltFltrTrpN3746 : 160|32@1+ (1,0) [0|4211081215] "" Vector__XXX
 SG_ Aftrtrtmnt2DslPrtcltFltrTrpPssvR : 128|32@1+ (1,0) [0|4211081215] "s" Vector__XXX
 SG_ Aftrtrtmnt2DslPrtcltFltrTrpNmbrO : 96|32@1+ (1,0) [0|4211081215] "" Vector__XXX
 SG_ Aftrtrtmnt2DslPrtcltFltrTrpDsbld : 64|32@1+ (1,0) [0|4211081215] "s" Vector__XXX
 SG_ Aftrtrtmnt2DslPrtcltFltrTrpActvR : 32|32@1+ (1,0) [0|4211081215] "s" Vector__XXX
 SG_ Aftrtrtmnt2DslPrtcltFltrTrpFlUsd : 0|32@1+ (0.5,0) [0|2105540607.5] "L" Vector__XXX

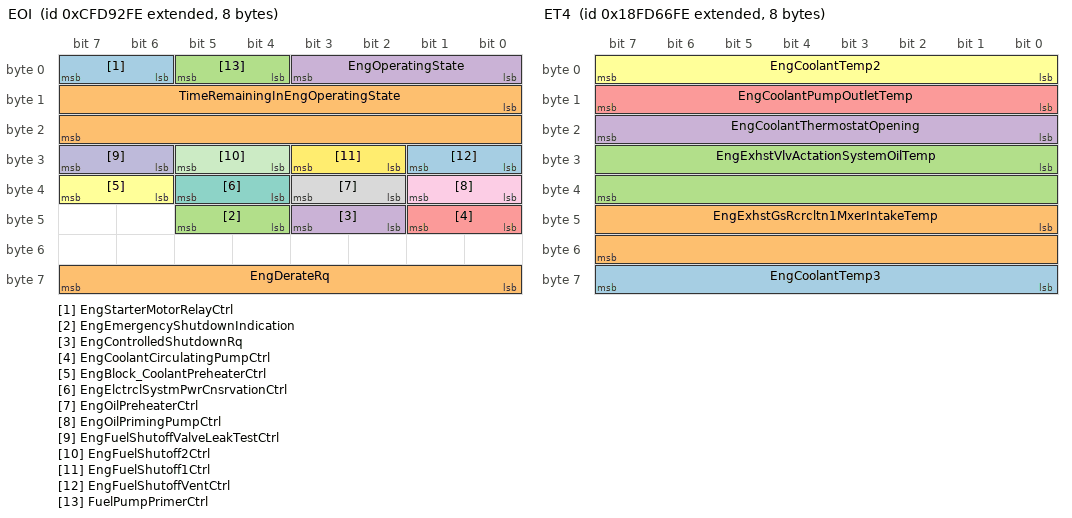
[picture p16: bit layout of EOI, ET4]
BO_ 2365428478 EOI: 8 Vector__XXX
 SG_ EngStarterMotorRelayCtrl : 6|2@1+ (1,0) [0|3] "" Vector__XXX
 SG_ EngDerateRq : 56|8@1+ (0.4,0) [0|100] "%" Vector__XXX
 SG_ EngEmergencyShutdownIndication : 44|2@1+ (1,0) [0|3] "" Vector__XXX
 SG_ EngControlledShutdownRq : 42|2@1+ (1,0) [0|3] "" Vector__XXX
 SG_ EngCoolantCirculatingPumpCtrl : 40|2@1+ (1,0) [0|3] "" Vector__XXX
 SG_ EngBlock_CoolantPreheaterCtrl : 38|2@1+ (1,0) [0|3] "" Vector__XXX
 SG_ EngElctrclSystmPwrCnsrvationCtrl : 36|2@1+ (1,0) [0|3] "" Vector__XXX
 SG_ EngOilPreheaterCtrl : 34|2@1+ (1,0) [0|3] "" Vector__XXX
 SG_ EngOilPrimingPumpCtrl : 32|2@1+ (1,0) [0|3] "" Vector__XXX
 SG_ EngFuelShutoffValveLeakTestCtrl : 30|2@1+ (1,0) [0|3] "" Vector__XXX
 SG_ EngFuelShutoff2Ctrl : 28|2@1+ (1,0) [0|3] "" Vector__XXX
 SG_ EngFuelShutoff1Ctrl : 26|2@1+ (1,0) [0|3] "" Vector__XXX
 SG_ EngFuelShutoffVentCtrl : 24|2@1+ (1,0) [0|3] "" Vector__XXX
 SG_ TimeRemainingInEngOperatingState : 8|16@1+ (1,0) [0|64255] "s" Vector__XXX
 SG_ FuelPumpPrimerCtrl : 4|2@1+ (1,0) [0|3] "" Vector__XXX
 SG_ EngOperatingState : 0|4@1+ (1,0) [0|15] "" Vector__XXX

BO_ 2566743806 ET4: 8 Vector__XXX
 SG_ EngCoolantTemp3 : 56|8@1+ (1,-40) [-40|210] "°C" Vector__XXX
 SG_ EngExhstGsRcrcltn1MxerIntakeTemp : 40|16@1+ (0.03125,-273) [-273|1734.96875] "°C" Vector__XXX
 SG_ EngExhstVlvActationSystemOilTemp : 24|16@1+ (0.03125,-273) [-273|1734.96875] "°C" Vector__XXX
 SG_ EngCoolantThermostatOpening : 16|8@1+ (0.4,0) [0|100] "%" Vector__XXX
 SG_ EngCoolantPumpOutletTemp : 8|8@1+ (1,-40) [-40|210] "°C" Vector__XXX
 SG_ EngCoolantTemp2 : 0|8@1+ (1,-40) [-40|210] "°C" Vector__XXX

BO_ 2499635454 GCVW: 8 Vector__XXX
 SG_ NetVehicleWeightChange : 24|24@1+ (2,-16449535) [-16449535|16449535] "kg" Vector__XXX
 SG_ GrossCombinationWeight : 0|24@1+ (2,0) [0|32899070] "kg" Vector__XXX

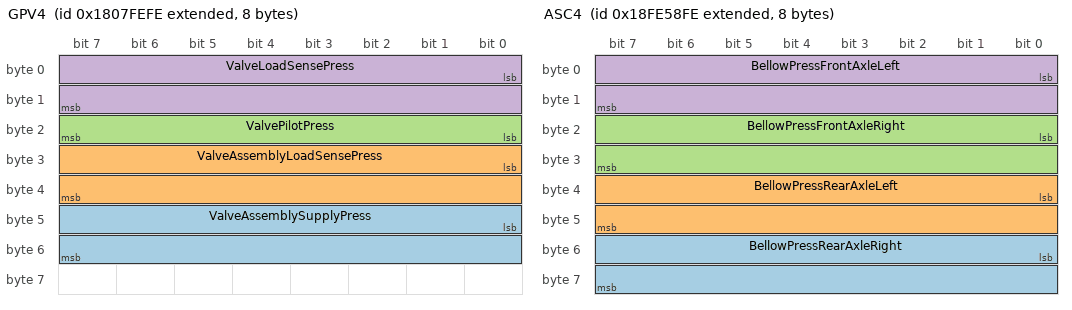
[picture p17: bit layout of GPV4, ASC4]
BO_ 2550660862 GPV4: 8 Vector__XXX
 SG_ ValveAssemblySupplyPress : 40|16@1+ (5,0) [0|321275] "kPa" Vector__XXX
 SG_ ValveAssemblyLoadSensePress : 24|16@1+ (5,0) [0|321275] "kPa" Vector__XXX
 SG_ ValvePilotPress : 16|8@1+ (16,0) [0|4000] "kPa" Vector__XXX
 SG_ ValveLoadSensePress : 0|16@1+ (5,0) [0|321275] "kPa" Vector__XXX

BO_ 2566805758 ASC4: 8 Vector__XXX
 SG_ BellowPressRearAxleRight : 48|16@1+ (0.1,0) [0|6425.5] "kPa" Vector__XXX
 SG_ BellowPressRearAxleLeft : 32|16@1+ (0.1,0) [0|6425.5] "kPa" Vector__XXX
 SG_ BellowPressFrontAxleRight : 16|16@1+ (0.1,0) [0|6425.5] "kPa" Vector__XXX
 SG_ BellowPressFrontAxleLeft : 0|16@1+ (0.1,0) [0|6425.5] "kPa" Vector__XXX

BO_ 2566806014 ASC3: 8 Vector__XXX
 SG_ RelativeLevelRearAxleRight : 48|16@1+ (0.1,-3200) [-3200|3225.5] "mm" Vector__XXX
 SG_ RelativeLevelRearAxleLeft : 32|16@1+ (0.1,-3200) [-3200|3225.5] "mm" Vector__XXX
 SG_ RelativeLevelFrontAxleRight : 16|16@1+ (0.1,-3200) [-3200|3225.5] "mm" Vector__XXX
 SG_ RelativeLevelFrontAxleLeft : 0|16@1+ (0.1,-3200) [-3200|3225.5] "mm" Vector__XXX

BO_ 2362638078 ASC2: 8 Vector__XXX
 SG_ MemoryLevelRq : 60|4@1+ (1,0) [0|15] "" Vector__XXX
 SG_ PrhbitAutomaticAirSuspensionCtrl : 58|2@1+ (1,0) [0|3] "" Vector__XXX
 SG_ SpeedDependentLevelCtrlRq : 56|2@1+ (1,0) [0|3] "" Vector__XXX
 SG_ AllowLevelCtrlDuringBrakingCmd : 54|2@1+ (1,0) [0|3] "" Vector__XXX
 SG_ ProhibitAirSuspensionCtrl : 52|2@1+ (1,0) [0|3] "" Vector__XXX
 SG_ KneelingCmdRearAxle : 50|2@1+ (1,0) [0|3] "" Vector__XXX
 SG_ KneelingCmdFrontAxle : 48|2@1+ (1,0) [0|3] "" Vector__XXX
 SG_ DamperStiffnessRqLift_TagAxle : 40|8@1+ (0.4,0) [0|100] "%" Vector__XXX
 SG_ DamperStiffnessRqRearAxle : 32|8@1+ (0.4,0) [0|100] "%" Vector__XXX
 SG_ DamperStiffnessRqFrontAxle : 24|8@1+ (0.4,0) [0|100] "%" Vector__XXX
 SG_ LiftAxle2PosCmd : 22|2@1+ (1,0) [0|3] "" Vector__XXX
 SG_ LiftAxle1PosCmd : 20|2@1+ (1,0) [0|3] "" Vector__XXX
 SG_ LevelCtrlModeRq : 16|4@1+ (1,0) [0|15] "" Vector__XXX
 SG_ NominalLevelRqRearAxle : 12|4@1+ (1,0) [0|15] "" Vector__XXX
 SG_ NominalLevelRqFrontAxle : 8|4@1+ (1,0) [0|15] "" Vector__XXX
 SG_ KneelingCtrlModeRq : 6|2@1+ (1,0) [0|3] "" Vector__XXX
 SG_ KneelingRqRightSide : 4|2@1+ (1,0) [0|3] "" Vector__XXX
 SG_ KneelingRqLeftSide : 2|2@1+ (1,0) [0|3] "" Vector__XXX
 SG_ AutomaticTractionHelp : 0|2@1+ (1,0) [0|3] "" Vector__XXX

BO_ 2365479678 ASC1: 8 Vector__XXX
 SG_ MemoryLevel : 60|4@1+ (1,0) [0|15] "" Vector__XXX
 SG_ SuspensionCtrlRefusalInformation : 56|4@1+ (1,0) [0|15] "" Vector__XXX
 SG_ SpeedDependantLevelCtrlStatus : 54|2@1+ (1,0) [0|3] "" Vector__XXX
 SG_ AllwLevelCtrlDuringBrakingStatus : 52|2@1+ (1,0) [0|3] "" Vector__XXX
 SG_ SuspensionRemoteCtrl2 : 50|2@1+ (1,0) [0|3] "" Vector__XXX
 SG_ SuspensionRemoteCtrl1 : 48|2@1+ (1,0) [0|3] "" Vector__XXX
 SG_ LiftAxle2Pos : 46|2@1+ (1,0) [0|3] "" Vector__XXX
 SG_ RearAxleInBumperRange : 42|2@1+ (1,0) [0|3] "" Vector__XXX
 SG_ FrontAxleInBumperRange : 40|2@1+ (1,0) [0|3] "" Vector__XXX
 SG_ LiftAxle1Pos : 38|2@1+ (1,0) [0|3] "" Vector__XXX
 SG_ DoorRelease : 36|2@1+ (1,0) [0|3] "" Vector__XXX
 SG_ VehicleMotionInhibit : 34|2@1+ (1,0) [0|3] "" Vector__XXX
 SG_ SecurityDevice : 32|2@1+ (1,0) [0|3] "" Vector__XXX
 SG_ LevelCtrlMode : 28|4@1+ (1,0) [0|15] "" Vector__XXX
 SG_ KneelingInformation : 24|4@1+ (1,0) [0|15] "" Vector__XXX
 SG_ LiftingCtrlModeRearAxle : 22|2@1+ (1,0) [0|3] "" Vector__XXX
 SG_ LiftingCtrlModeFrontAxle : 20|2@1+ (1,0) [0|3] "" Vector__XXX
 SG_ LoweringCtrlModeRearAxle : 18|2@1+ (1,0) [0|3] "" Vector__XXX
 SG_ LoweringCtrlModeFrontAxle : 16|2@1+ (1,0) [0|3] "" Vector__XXX
 SG_ AboveNominalLevelRearAxle : 14|2@1+ (1,0) [0|3] "" Vector__XXX
 SG_ AboveNominalLevelFrontAxle : 12|2@1+ (1,0) [0|3] "" Vector__XXX
 SG_ BelowNominalLevelRearAxle : 10|2@1+ (1,0) [0|3] "" Vector__XXX
 SG_ BelowNominalLevelFrontAxle : 8|2@1+ (1,0) [0|3] "" Vector__XXX
 SG_ NominalLevelRearAxle : 4|4@1+ (1,0) [0|15] "" Vector__XXX
 SG_ NominalLevelFrontAxle : 0|4@1+ (1,0) [0|15] "" Vector__XXX

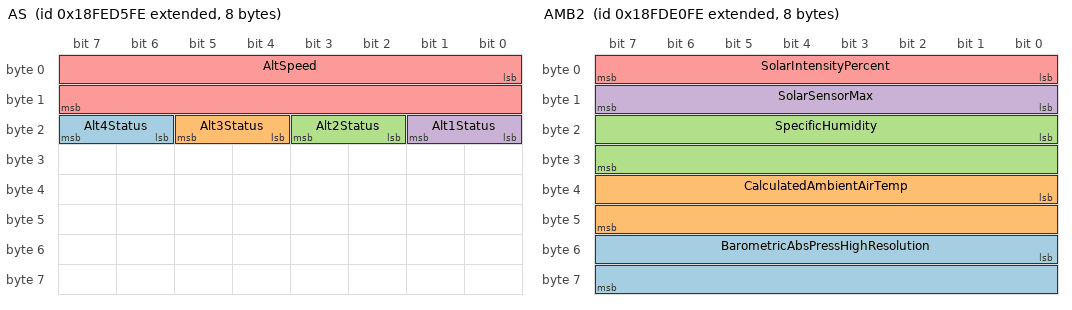
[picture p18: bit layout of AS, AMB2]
BO_ 2566837758 AS: 8 Vector__XXX
 SG_ Alt4Status : 22|2@1+ (1,0) [0|3] "" Vector__XXX
 SG_ Alt3Status : 20|2@1+ (1,0) [0|3] "" Vector__XXX
 SG_ Alt2Status : 18|2@1+ (1,0) [0|3] "" Vector__XXX
 SG_ Alt1Status : 16|2@1+ (1,0) [0|3] "" Vector__XXX
 SG_ AltSpeed : 0|16@1+ (0.5,0) [0|32127.5] "rpm" Vector__XXX

BO_ 2633922558 AP: 8 Vector__XXX
 SG_ AuxAbsPressReading : 32|16@1+ (0.5,0) [0|32127.5] "kPa" Vector__XXX
 SG_ AuxGagePressReading1 : 16|16@1+ (0.5,0) [0|32127.5] "kPa" Vector__XXX
 SG_ AuxVacuumPressReading : 0|16@1+ (0.5,0) [0|32127.5] "kPa" Vector__XXX

BO_ 2566775038 AMB2: 8 Vector__XXX
 SG_ BarometricAbsPressHighResolution : 48|16@1+ (0.1,0) [0|6425.5] "kPa" Vector__XXX
 SG_ CalculatedAmbientAirTemp : 32|16@1+ (0.03125,-273) [-273|1734.96875] "°C" Vector__XXX
 SG_ SpecificHumidity : 16|16@1+ (0.01,0) [0|642.55] "g/kg" Vector__XXX
 SG_ SolarSensorMax : 8|8@1+ (0.4,0) [0|100] "mW/cm^2" Vector__XXX
 SG_ SolarIntensityPercent : 0|8@1+ (0.4,0) [0|100] "%" Vector__XXX

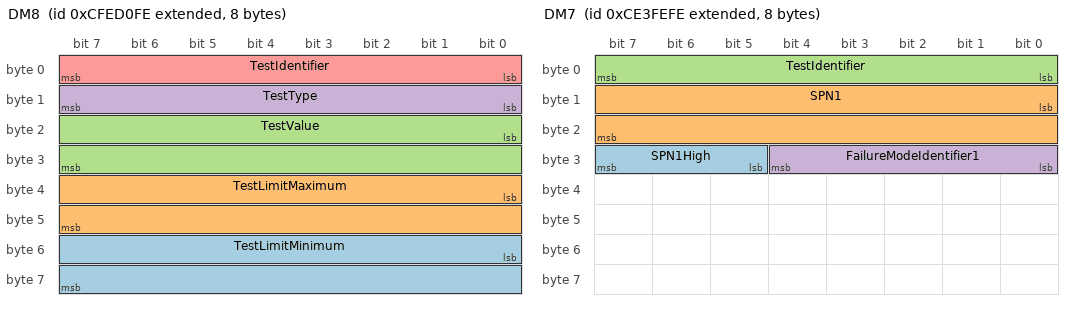
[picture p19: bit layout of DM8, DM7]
BO_ 2365509886 DM8: 8 Vector__XXX
 SG_ TestLimitMinimum : 48|16@1+ (1,0) [0|0] "" Vector__XXX
 SG_ TestLimitMaximum : 32|16@1+ (1,0) [0|0] "" Vector__XXX
 SG_ TestValue : 16|16@1+ (1,0) [0|0] "" Vector__XXX
 SG_ TestType : 8|8@1+ (1,0) [1|64] "" Vector__XXX
 SG_ TestIdentifier : 0|8@1+ (1,0) [0|255] "" Vector__XXX

BO_ 2363752190 DM7: 8 Vector__XXX
 SG_ SPN1High : 29|3@1+ (1,0) [0|7] "" Vector__XXX
 SG_ SPN1 : 8|16@1+ (1,0) [0|524287] "" Vector__XXX
 SG_ TestIdentifier : 0|8@1+ (1,0) [0|255] "" Vector__XXX
 SG_ FailureModeIdentifier1 : 24|5@1+ (1,0) [0|31] "" Vector__XXX

BO_ 2566836222 DM6: 22 Vector__XXX
 SG_ FlashRedStopLamp : 12|2@1+ (1,0) [0|3] "" Vector__XXX
 SG_ FlashProtectLamp : 8|2@1+ (1,0) [0|3] "" Vector__XXX
 SG_ FlashMalfuncIndicatorLamp : 14|2@1+ (1,0) [0|3] "" Vector__XXX
 SG_ FlashAmberWarningLamp : 10|2@1+ (1,0) [0|3] "" Vector__XXX
 SG_ MalfunctionIndicatorLampStatus : 6|2@1+ (1,0) [0|3] "" Vector__XXX
 SG_ RedStopLampState : 4|2@1+ (1,0) [0|3] "" Vector__XXX
 SG_ AmberWarningLampStatus : 2|2@1+ (1,0) [0|3] "" Vector__XXX
 SG_ ProtectLampStatus : 0|2@1+ (1,0) [0|3] "" Vector__XXX
 SG_ DTC5 : 144|32@1+ (1,0) [0|4294967295] "" Vector__XXX
 SG_ DTC4 : 112|32@1+ (1,0) [0|4294967295] "" Vector__XXX
 SG_ DTC3 : 80|32@1+ (1,0) [0|4294967295] "" Vector__XXX
 SG_ DTC2 : 48|32@1+ (1,0) [0|4294967295] "" Vector__XXX
 SG_ DTC1 : 16|32@1+ (1,0) [0|4294967295] "" Vector__XXX

BO_ 2365509374 DM5: 8 Vector__XXX
 SG_ BoostPressureControlSystemStatus : 57|1@1- (1,0) [0|0] "" Vector__XXX
 SG_ DieselParticulateFilterStatus : 58|1@1- (1,0) [0|0] "" Vector__XXX
 SG_ NOxConvertingCatalystAdsorberSta : 59|1@1- (1,0) [0|0] "" Vector__XXX
 SG_ NMHCConvertingCatalystStatus : 60|1@1- (1,0) [0|0] "" Vector__XXX
 SG_ BoostPressureControlSystemSuppor : 41|1@1- (1,0) [0|0] "" Vector__XXX
 SG_ DieselParticulateFilterSupport : 42|1@1- (1,0) [0|0] "" Vector__XXX
 SG_ NOxConvertingCatalystAdsorberSup : 43|1@1- (1,0) [0|0] "" Vector__XXX
 SG_ NMHCConvertingCatalystSupport : 44|1@1- (1,0) [0|0] "" Vector__XXX
 SG_ MisfireMonitoringSupport : 24|1@1+ (1,0) [0|0] "" Vector__XXX
 SG_ OBDCompliance : 16|8@1+ (1,0) [0|250] "" Vector__XXX
 SG_ PreviouslyActiveTroubleCodes : 8|8@1+ (1,0) [0|250] "" Vector__XXX
 SG_ ActiveTroubleCodes : 0|8@1+ (1,0) [0|250] "" Vector__XXX
 SG_ SecondAirSystemMonStatus : 51|1@1+ (1,0) [0|1] "" Vector__XXX
 SG_ EvaporativeSystemMonStatus : 50|1@1+ (1,0) [0|1] "" Vector__XXX
 SG_ ACSystemRefrigerantMonStatus : 52|1@1+ (1,0) [0|1] "" Vector__XXX
 SG_ OxygenSensorHeaterMonStatus : 54|1@1+ (1,0) [0|1] "" Vector__XXX
 SG_ OxygenSensorMonStatus : 53|1@1+ (1,0) [0|1] "" Vector__XXX
 SG_ EGRSystemMonitoringStatus : 55|1@1+ (1,0) [0|1] "" Vector__XXX
 SG_ CatalystMonStatus : 48|1@1+ (1,0) [0|1] "" Vector__XXX
 SG_ ColdStartAidSystemMonStatus : 56|1@1+ (1,0) [0|1] "" Vector__XXX
 SG_ HeatedCatalystMonStatus : 49|1@1+ (1,0) [0|0] "" Vector__XXX
 SG_ CatalystMonSupp : 32|1@1+ (1,0) [0|1] "" Vector__XXX
 SG_ ColdStartAidSystemMonSupp : 40|1@1+ (1,0) [0|1] "" Vector__XXX
 SG_ HeatedCatalystMonSupp : 33|1@1+ (1,0) [0|0] "" Vector__XXX
 SG_ EvaporativeSystemMonSupp : 34|1@1+ (1,0) [0|1] "" Vector__XXX
 SG_ SecondAirSystemMonSupp : 35|1@1+ (1,0) [0|1] "" Vector__XXX
 SG_ ACSystemRefrigerantMonSupp : 36|1@1+ (1,0) [0|1] "" Vector__XXX
 SG_ OxygenSensorMonSupp : 37|1@1+ (1,0) [0|1] "" Vector__XXX
 SG_ OxygenSensorHeaterMonSupp : 38|1@1+ (1,0) [0|1] "" Vector__XXX
 SG_ EGRSystemMonitoringSupp : 39|1@1+ (1,0) [0|1] "" Vector__XXX
 SG_ MisfireMonitoringStatus : 28|1@1+ (1,0) [0|0] "" Vector__XXX
 SG_ ComprehensiveCompMonStatus : 30|1@1+ (1,0) [0|1] "" Vector__XXX
 SG_ FuelSystemMonitoringStatus : 29|1@1+ (1,0) [0|1] "" Vector__XXX
 SG_ ComprehensiveComponentMonSupp : 26|1@1+ (1,0) [0|0] "" Vector__XXX
 SG_ FuelSystemMonitoringSupport : 25|1@1+ (1,0) [0|1] "" Vector__XXX

CM_ SG_ 2566847230 ParkingBrakeRedWarningSignal "This parameter commands the Parking Brake red optical warning signal.

00 – off
01 – on
10 – Reserved 
11 – Take no action";
CM_ SG_ 2566847230 ParkBrakeReleaseInhibitStatus "This parameter provides reports on the status of the Park Brake Release Inhibit function.
00 - Park Brake release is not inhibited
01 - Park Brake release is inhibited
10 - Error (for example: Park Brake release is not inhibited, but is requested ...";
CM_ SG_ 2566847230 ParkingBrakeActuator "Signal which indicates the current state of the actuator(s) that control the parking brake (see also SPN 70 and 5275).

00 - Parking brake actuator inactive
01 - Parking brake actuator active
10 - Error
11 - Not available";
CM_ SG_ 2566847230 BrakeSecondPress "Gage pressure of air in the secondary, or service side, of the air brake system.";
CM_ SG_ 2566847230 BrakePrimaryPress "Gage pressure of air in the primary, or supply side, of the air brake system.";
CM_ SG_ 2566847230 BrakeAppPress "Gage pressure of compressed air or fluid in vehicle braking system measured at the brake chamber when brake shoe (or pad) is placed against brake drum (or disc).";
CM_ SG_ 2566848254 AuxPumpPress "Gage pressure of auxiliary water pump driven as a PTO device.";
CM_ BO_ 2566725886 "The purpose of this PGN is to group the aftertreatment diesel oxidation catalyst data for bank 1. These values include the intake temperature, outlet temperature and differential pressure as well as the associated preliminary FMIs.  The diesel ...";
CM_ SG_ 2566725886 Aftrtrtmnt1DslOxdtnCtlystDff4770 "Used to identify the applicable J1939-73 FMI detected in the diesel oxidation catalyst differential pressure sensor by the manufacturer’s sensor control software in exhaust bank 1. When there is no failure FMI 31 is sent. In the case of multiple ...";
CM_ SG_ 2566725886 Aftrtrtmnt1DslOxdtnCtlystOtl4769 "Used to identify the applicable J1939-73 FMI detected in the diesel oxidation catalyst outlet gas temperature sensor by the manufacturer’s sensor control software in exhaust bank 1. When there is no failure FMI 31 is sent. In the case of multiple ...";
CM_ SG_ 2566725886 Aftrtrtmnt1DslOxdtnCtlystInt4768 "Used to identify the applicable J1939-73 FMI detected in the diesel oxidation catalyst intake temperature sensor by the manufacturer’s sensor control software in exhaust bank 1. When there is no failure FMI 31 is sent. In the case of multiple ...";
CM_ SG_ 2566725886 Aftrtrtmnt1DslOxdtnCtlystDffPrss "Exhaust differential pressure measured between the intake and exhaust of a diesel oxidation catalyst in exhaust bank 1.  This parameter should be used with engines fueled by diesel fuel (not gaseous fuel like natural gas or propane).  A separate ...";
CM_ SG_ 2566725886 Aftrtrtmnt1DslOxdtnCtlystOtltGsT "Temperature of engine combustion byproducts leaving the diesel oxidation catalyst exhaust in exhaust bank 1.  This parameter should be used with engines fueled by diesel fuel (not gaseous fuel like natural gas or propane).  A separate parameter has ...";
CM_ SG_ 2566725886 Aftrtrtmnt1DslOxdtnCtlystIntkGsT "Temperature of engine combustion byproducts entering the diesel oxidation catalyst in exhaust bank 1.  This parameter should be used with engines fueled by diesel fuel (not gaseous fuel like natural gas or propane).  A separate parameter has been ...";
CM_ BO_ 2359557886 "This message shall provide the applicable lamp(s) for each individual DTC";
CM_ SG_ 2359557886 DTCWarnLampSupportStatus "Lamp support status";
CM_ SG_ 2359557886 DTCWarnLampSupportFlash "Lamp support status";
CM_ SG_ 2359557886 DTCStopLampSupportStatus "Lamp support status";
CM_ SG_ 2359557886 DTCStopLampSupportFlash "Lamp support status";
CM_ SG_ 2359557886 DTCProtectLampSupportStatus "Lamp support status";
CM_ SG_ 2359557886 DTCProtectLampSupportFlash "Lamp support status";
CM_ SG_ 2359557886 DTCMilSupportStatus "Lamp support status";
CM_ SG_ 2359557886 DTCMilSupportFlash "Lamp support status";
CM_ SG_ 2359557886 DTC1 "Diagnostic Trouble Code";
CM_ BO_ 2633844734 "ASCII text string describing a manufacturer-specific Transmission Mode.  This PGN may contain up to 8 instances of the Transmission Mode Label field (for Transmission Mode 1 through Transmission Mode 8) with each separated by the asterisk (*) ...";
CM_ SG_ 2633844734 TransModeLabel8 "Conveys ASCII ‘labels’ for each of the manufacturer-specified TC1 Transmission Mode ’x’ / ETC7 Transmission Mode ...";
CM_ SG_ 2633844734 TransModeLabel7 "Conveys ASCII ‘labels’ for each of the manufacturer-specified TC1 Transmission Mode ’x’ / ETC7 Transmission Mode ...";
CM_ SG_ 2633844734 TransModeLabel6 "Conveys ASCII ‘labels’ for each of the manufacturer-specified TC1 Transmission Mode ’x’ / ETC7 Transmission Mode ...";
CM_ SG_ 2633844734 TransModeLabel5 "Conveys ASCII ‘labels’ for each of the manufacturer-specified TC1 Transmission Mode ’x’ / ETC7 Transmission Mode ...";
CM_ SG_ 2633844734 TransModeLabel4 "Conveys ASCII ‘labels’ for each of the manufacturer-specified TC1 Transmission Mode ’x’ / ETC7 Transmission Mode ...";
CM_ SG_ 2633844734 TransModeLabel3 "Conveys ASCII ‘labels’ for each of the manufacturer-specified TC1 Transmission Mode ’x’ / ETC7 Transmission Mode ...";
CM_ SG_ 2633844734 TransModeLabel2 "Conveys ASCII ‘labels’ for each of the manufacturer-specified TC1 Transmission Mode ’x’ / ETC7 Transmission Mode ...";
CM_ SG_ 2633844734 TransModeLabel "Conveys ASCII ‘labels’ for each of the manufacturer-specified TC1 Transmission Mode ’x’ / ETC7 Transmission Mode Indicator ‘x’ pairs.  Intended for use with on-board or service tool displays.
NOTE – Non-printable or non-graphic ASCII characters are ...";
CM_ BO_ 2560360190 "This is a standardized mechanism for an ECU to report a listing of the manufacturer specific (i.e. proprietary) methods and formats it supports when using the PropA, PropA2, and PropB PGNs (see J1939-21).  The ability to support multiple ...";
CM_ SG_ 2560360190 DataDictionaryMethod "A manufacturer defined code to define the proprietary communications method.  The structure and interpretation of the code is manufacturer specific.  This allows manufacturers to establish their own methods for reporting proprietary support for ...";
CM_ SG_ 2560360190 DataDictionaryManufacturerCode "The J1939 Manufacturer Code (see J1939 Table B10) associated with the manufacturer who defined the proprietary communications method.  0x7FF reserved for \"Not Available\"";
CM_ BO_ 2566736126 "Provides bank 2 short-term and long-term fuel trim values";
CM_ SG_ 2566736126 EngExhstGsOxygnSnsrClsdLpOprtnBn "This parameter indicates the status of the bank 2 O2 sensor feedback closed loop operation
0000 = Open loop - has not yet satisfied conditions to go closed loop
0001 = Closed loop - using oxygen sensor(s) as feedback for fuel control
0010 = Open ...";
CM_ SG_ 2566736126 ShorttermFuelTrimBank2 "This parameter is the short-term percent change in fueling based on the O2 sensor feedback for cylinder bank 2, based on the operating point in the nominal fuel map.";
CM_ SG_ 2566736126 LongtermFuelTrimBank2 "This parameter is the long-term percent change in fueling based on the O2 sensor feedback for cylinder bank 2, based on the operating point in the nominal fuel map.";
CM_ BO_ 2566736382 "Provides bank 1 short-term and long-term fuel trim values";
CM_ SG_ 2566736382 EngExhstGsOxygnSnsrClsdLpOprtnBn "This parameter indicates the status of the bank 1 O2 sensor feedback closed loop operation
0000 = Open loop - has not yet satisfied conditions to go closed loop
0001 = Closed loop - using oxygen sensor(s) as feedback for fuel control
0010 = Open ...";
CM_ SG_ 2566736382 ShorttermFuelTrimBank1 "This parameter is the short-term percent change in fueling based on the O2 sensor feedback for cylinder bank 1, based on the operating point in the nominal fuel map.

Note:  This is similar to SPN 1695, but with higher resolution.";
CM_ SG_ 2566736382 LongtermFuelTrimBank1 "This parameter is the long-term percent change in fueling based on the O2 sensor feedback for cylinder bank 1, based on the operating point in the nominal fuel map.";
CM_ BO_ 2565874174 "This PGN contains the speed information and status signal of each engine speed sensor. This message is used for service to troubleshoot no-start or hard start problems.  This message is not needed except for servicing.";
CM_ SG_ 2565874174 EngSpdSensor1TimingPatternStatus "This is the timing pattern status of the engine speed sensor signal for sensor 1.   The sensor may be sending a speed signal but the pattern may not be valid.  Since the speed is considered valid, the error indicator will not be used in the engine ...";
CM_ SG_ 2565874174 EngSpdSensor2TimingPatternStatus "This is the timing pattern status of the engine speed sensor signal for sensor 2.  The sensor may be sending a speed signal but the pattern may not be valid.  Since the speed is considered valid, the error indicator will not be used in the engine ...";
CM_ SG_ 2565874174 EngSpdSensor3TimingPatternStatus "This is the timing pattern status of the engine speed sensor signal for sensor 3.  The sensor may be sending a speed signal but the pattern may not be valid.  Since the speed is considered valid, the error indicator will not be used in the engine ...";
CM_ SG_ 2565874174 EngSpeed3 "The engine speed as measured by speed sensor 3.
Note:  This is for the engine speed from the 3rd engine speed sensor.  This may be different than SPN 190 when used in multiple engine speed sensor configurations.   In an application with multiple ...";
CM_ SG_ 2565874174 EngSpeed2 "The engine speed as measured by speed sensor 2
Note:  This is for the engine speed from the 2nd engine speed sensor.  This may be different than SPN 190 when used in multiple engine speed sensor configurations.   In an application with multiple ...";
CM_ SG_ 2565874174 EngSpeed1 "The engine speed as measured by speed sensor 1.
Note:  This is for the engine speed from the 1st engine speed sensor.  This may be different than SPN 190 when used in multiple engine speed sensor configurations.   In an application with only one ...";
CM_ BO_ 2432520958 "Transmit status information from the Master ECU to an electronic thermostat";
CM_ SG_ 2432520958 EngAxClerSupplyValve2ActuatorCmd "The control command applied to the engine auxiliary cooler supply valve 2 actuator, where 0% represents closed and 100% represents open.";
CM_ SG_ 2432520958 EngAxClerSupplyValve1ActuatorCmd "The control command applied to the engine auxiliary cooler supply valve 1 actuator, where 0% represents closed and 100% represents open.

See SPN 4197 for primary engine thermostat valve.";
CM_ SG_ 2432520958 DsredEngCoolantThermostatOpening "Indicates the desired position of the engine coolant control valve.   0% represents the thermostat allows flow to completely bypass the radiator and 100% represents the flow is fully through the radiator.  If the electronic thermostat is operating ...";
CM_ SG_ 2432520958 DesiredEngCoolantPumpOutletTemp "Desired engine coolant temperature of the engine to an electronic thermostat.  If the electronic thermostat valve is operating in position control mode (see SPN 4195)  then transmit 0xFF.";
CM_ SG_ 2432520958 EngCoolantThermostatMode "Specifies if the engine coolant thermostat valve will operate in temperature control mode or position control mode.

00 = temperature control mode
01 = position control mode (used for service only)
10 = reserved
11 = don't care/reserved";
CM_ BO_ 2560425726 "Notes:
Implementers are encouraged to use specific functional SPNs whenever possible.
AUXIO PGNs are intended for two categories of use in which fixed mapping to functions is not possible:
1)  Generic I/O devices
2)  Applications lacking defined ...";
CM_ SG_ 2560425726 AuxI_OChannel19 "Identifies the current value of auxiliary input/output channels that are configured uniquely per application.";
CM_ SG_ 2560425726 AuxI_OChannel20 "Identifies the current value of auxiliary input/output channels that are configured uniquely per application.";
CM_ SG_ 2560425726 AuxI_OChannel21 "Identifies the current value of auxiliary input/output channels that are configured uniquely per application.";
CM_ SG_ 2560425726 AuxI_OChannel22 "Identifies the current value of auxiliary input/output channels that are configured uniquely per application.";
CM_ SG_ 2560425726 AuxI_OChannel15 "Identifies the current value of auxiliary input/output channels that are configured uniquely per application.";
CM_ SG_ 2560425726 AuxI_OChannel16 "Identifies the current value of auxiliary input/output channels that are configured uniquely per application.";
CM_ SG_ 2560425726 AuxI_OChannel17 "Identifies the current value of auxiliary input/output channels that are configured uniquely per application.";
CM_ SG_ 2560425726 AuxI_OChannel18 "Identifies the current value of auxiliary input/output channels that are configured uniquely per application.";
CM_ BO_ 2560491262 "Notes:
Implementers are encouraged to use specific functional SPNs whenever possible.
AUXIO PGNs are intended for two categories of use in which fixed mapping to functions is not possible:
1)  Generic I/O devices
2)  Applications lacking defined ...";
CM_ SG_ 2560491262 AuxI_OChannel11 "Identifies the current value of auxiliary input/output channels that are configured uniquely per application.";
CM_ SG_ 2560491262 AuxI_OChannel12 "Identifies the current value of auxiliary input/output channels that are configured uniquely per application.";
CM_ SG_ 2560491262 AuxI_OChannel13 "Identifies the current value of auxiliary input/output channels that are configured uniquely per application.";
CM_ SG_ 2560491262 AuxI_OChannel14 "Identifies the current value of auxiliary input/output channels that are configured uniquely per application.";
CM_ SG_ 2560491262 AuxI_OChannel7 "Identifies the current value of auxiliary input/output channels that are configured uniquely per application.";
CM_ SG_ 2560491262 AuxI_OChannel8 "Identifies the current value of auxiliary input/output channels that are configured uniquely per application.";
CM_ SG_ 2560491262 AuxI_OChannel9 "Identifies the current value of auxiliary input/output channels that are configured uniquely per application.";
CM_ SG_ 2560491262 AuxI_OChannel10 "Identifies the current value of auxiliary input/output channels that are configured uniquely per application.";
CM_ BO_ 2349399806 "Notes:
Implementers are encouraged to use specific functional SPNs whenever possible.
AUXIO PGNs are intended for two categories of use in which fixed mapping to functions is not possible:
1)  Generic I/O devices
2)  Applications lacking defined ...";
CM_ SG_ 2349399806 AuxI_OChannel3 "Identifies the current value of auxiliary input/output channels that are configured uniquely per application.";
CM_ SG_ 2349399806 AuxI_OChannel4 "Identifies the current value of auxiliary input/output channels that are configured uniquely per application.";
CM_ SG_ 2349399806 AuxI_OChannel5 "Identifies the current value of auxiliary input/output channels that are configured uniquely per application.";
CM_ SG_ 2349399806 AuxI_OChannel6 "Identifies the current value of auxiliary input/output channels that are configured uniquely per application.";
CM_ BO_ 2566758398 "Contains information about the aftertreatment 1 air system";
CM_ SG_ 2566758398 Aftertreatment1AirEnableActuator "Indicates whether aftertreatment 1 air enable actuator is on or off

00   not active
01   active
10   reserved for SAE assignment
11   not available";
CM_ SG_ 2566758398 Aftertreatment1PurgeAirActuator "Indicates whether aftertreatment 1 purge air actuator is on or off

00   not active
01   active
10   reserved for SAE assignment
11   not available";
CM_ SG_ 2566758398 Aftrtrtmnt1AtmizationAirActuator "Indicates whether aftertreatment 1 atomization air actuator is on or off

00   not active
01   active
10   reserved for SAE assignment
11   not available";
CM_ SG_ 2566758398 Aftertreatment1AirSystemRelay "Indicates whether aftertreatment 1 air system relay is on or off

00   not active
01   active
10   reserved for SAE assignment
11   not available";
CM_ SG_ 2566758398 Aftrtratment1AirPressActuatorPos "Position of the aftertreatment 1 air pressure actuator as measured by a position feedback sensor.";
CM_ SG_ 2566758398 Aftertreatment1AirPressCtrl "Position that the controller is commanding the aftertreatment 1 air pressure control to maintain.  0% = fully closed, 100% = fully open";
CM_ SG_ 2566758398 Aftertreatment1PurgeAirPress "Pressure of the purge air supply for aftertreatment 1";
CM_ SG_ 2566758398 Aftertreatment1SupplyAirPress "Pressure of the supply air for aftertreatment 1.  Supply air is the air supplied from a pneumatic line for an air-assisted or pneumatic actuator.  One example is an air assisted fuel injector (the supply air assists in the atomization of fuel).";
CM_ BO_ 2566745598 "This PGN contains information about the Aftertreatment 1 Air Control.  

NOTE: This message will be transmitted by the engine or aftertreatment controller.  Other aftertreatment air control information could be added in the future.";
CM_ SG_ 2566745598 Aftertreatment1SecondAirPress "Pressure of the secondary air for aftertreatment 1.  Secondary air is air provided to the exhaust system (per SAE J2403).

For absolute pressure, see SPN 5589.";
CM_ SG_ 2566745598 Aftertreatment1SecondAirMassFlow "Indicates the secondary air mass flow for aftertreatment 1.  Secondary air is the air provided to the exhaust system (per SAE J2403).";
CM_ SG_ 2566745598 Aftertreatment1SecondAirTemp "Indicates the secondary air temperature for aftertreatment 1.  Secondary air is air provided to the exhaust system (per SAE J2403).";
CM_ SG_ 2566745598 Aftrtreatment1SecondAirDiffPress "Indicates the secondary air differential pressure for aftertreatment 1.  Secondary air is air provided to the exhaust system (per SAE J2403).";
CM_ BO_ 2566758910 "Contains information about the aftertreatment 1 fuel system";
CM_ SG_ 2566758910 Aftrtrtmnt1FlInjector1HeaterCtrl "Heating level that the controller is commanding the aftertreatment 1 fuel injector 1 heater control to maintain. 0% = off, 100% = maximum.";
CM_ SG_ 2566758910 Aftrtreatment1FuelEnableActuator "Indicates whether aftertreatment 1 fuel enable actuator is on or off

00   not active
01   active
10   reserved for SAE assignment
11   not available";
CM_ SG_ 2566758910 Aftrtreatment1RegenerationStatus "Indicates whether regeneration is active or inactive in aftertreatment 1.  

00   not active
01   active
10   reserved for SAE assignment
11   not available";
CM_ SG_ 2566758910 Aftertreatment1Ignt "Indicates whether aftertreatment 1 ignition circuit is energized by the ECM.

00   not active
01   active
10   reserved for SAE assignment
11   not available";
CM_ SG_ 2566758910 Aftertreatment1FuelDrainActuator "Indicates whether aftertreatment 1 fuel drain actuator is on or off

00   not active
01   active
10   reserved for SAE assignment
11   not available";
CM_ SG_ 2566758910 Aftertreatment1FuelPress1Ctrl "Position that the controller is commanding the aftertreatment 1 fuel pressure control to maintain.  0% = fully closed, 100% = fully open.";
CM_ SG_ 2566758910 Aftertreatment1FuelRate "Rate of fuel being delivered to aftertreatment 1 for regeneration";
CM_ SG_ 2566758910 Aftertreatment1FuelPress1 "First fuel pressure measurement for the aftertreatment 1 system";
CM_ BO_ 2566743550 "Contains information about the aftertreatment 1 fuel system.  See also PGN 64929.";
CM_ SG_ 2566743550 Aftrtrtmnt1HydrcrbnDsrIntkFlTemp "Measured temperature of the intake fuel to the hydrocarbon dosing device";
CM_ SG_ 2566743550 Aftrtrtmnt1FelPress2ActuatorCtrl "Indicates how the device is controlling the aftertreatment 1 fuel pressure 2 regulating control valve.   0% = fully closed, 100%=fully open.";
CM_ SG_ 2566743550 Aftrtrtmnt1FlFlwDverterValveCtrl "Indicates how the device is controlling the aftertreatment 1 fuel flow diverter valve. When this valve is on it diverts fuel flow from the Aftertreatment 1 Regeneration Device.

00 off
01 on
10 reserved for SAE assignment
11 not available";
CM_ SG_ 2566743550 Aftertreatment1FuelPumpRelayCtrl "Indicates how the device is controlling the aftertreatment 1 fuel pump relay.

00 off
01 on
10 reserved for SAE assignment
11 not available";
CM_ SG_ 2566743550 Aftertreatment1FuelPress2 "Second fuel pressure measurement for the aftertreatment 1 system";
CM_ BO_ 2566753534 "Diesel particulate filter gas parameters for system or bank 1";
CM_ SG_ 2566753534 DslParticulateFilterOutletPress1 "This parameter indicates the diesel particulate filter outlet gage pressure 1 (bank 1).";
CM_ SG_ 2566753534 DslParticulateFilterIntakePress1 "This parameter indicates the diesel particulate filter intake gage pressure 1 (bank 1).";
CM_ BO_ 2566756606 "Contains information about the history of the aftertreatment 1 system";
CM_ SG_ 2566756606 Aftrtrtmnt1AvrgDstncBtwnActvDPFR "Indicates the average distance since last reset between active regenerations, that have not been forced to occur by manual request, for Aftertreatment device 1.
If the manufacturer allows this parameter to be reset, this distance is the average ...";
CM_ SG_ 2566756606 Aftrtrtmnt1AvrgTmBtwnActvRgnrtns "Indicates the average time since last reset between active regenerations, that have not been forced to occur by manual request, for Aftertreatment device 1.
If the manufacturer allows this parameter to be reset, this time is the average since last ...";
CM_ SG_ 2566756606 Aftrtrtmnt1DslPrtcltFltrTtlN3728 "Total number of aftertreatment device 1 active regeneration manual requests by the operator over the lifetime of the device.";
CM_ SG_ 2566756606 Aftrtrtmnt1DslPrtcltFltrTtlN3727 "Total number of aftertreatment device 1 active regeneration inhibit requests by the operator over the lifetime of the device.";
CM_ SG_ 2566756606 Aftrtrtmnt1DslPrtcltFltrTtlNmbrO "Total number of passive regenerations by aftertreatment device 1 over the lifetime of the device.";
CM_ SG_ 2566756606 Aftrtrtmnt1DslPrtcltFltrTtlPssvR "Total amount of time that aftertreatment 1 diesel particulate filter has been in passive regeneration over the lifetime of the device.";
CM_ SG_ 2566756606 Aftrtrtmnt1TtlNmbrOfActvRgnrtons "Total number of active regenerations by aftertreatment device 1 over the lifetime of the device.";
CM_ SG_ 2566756606 Aftertreatment1TotalDisabledTime "Total amount of time that aftertreatment 1 regeneration has been manually disabled.";
CM_ SG_ 2566756606 Aftrtrtmnt1TotalRegenerationTime "Total amount of time that aftertreatment device 1 has been regenerating over the lifetime of the device.";
CM_ SG_ 2566756606 Aftertreatment1TotalFuelUsed "Total amount of fuel used by aftertreatment device 1 over the lifetime of the device.";
CM_ BO_ 2565869310 "The purpose of this PGN is to group the aftertreatment intake sensor data for bank 1.  These values include the NOx, %O2 , Status's of the sensors with respect to the power being supplied and the heating element, errors and stability of the ...";
CM_ SG_ 2565869310 NOxSensorATI1SelfdiagnosisStatus "Self-diagnosis result status for NOx sensor ATI1 (Aftertreatment Intake Bank 1)
000 Diagnosis not active
001 NOx Sensor ATI1 Self Diagnosis active flag
010 NOx Sensor ATI1 Self Diagnosis Result Complete
011 NOx Sensor ATI1 Self Diagnosis aborted
 ...";
CM_ SG_ 2565869310 Aftrtrtmnt1IntkOxygnSnsrPrlmnryF "Used to identify the applicable J1939-73 FMI detected in the aftertreatment intake oxygen sensor by the manufacturer’s sensor control software in exhaust bank 1.  When there is no failure FMI 31 is sent.  In the case of multiple failures the most ...";
CM_ SG_ 2565869310 Aftrtrtmnt1IntkNOxSnsrPrlmnryFMI "Used to identify the applicable J1939-73 FMI detected in the aftertreatment intake NOx sensor by the manufacturer’s sensor control software in exhaust bank 1.  When there is no failure FMI 31 is sent.  In the case of multiple failures the most ...";
CM_ SG_ 2565869310 Aftrtrtmnt1IntkGsSnsorHeaterCtrl "Indicates the heater status in the warm-up process.  Upon receiving a power-up command, the gas sensor ramps up according to a manufacturer defined profile.  The Preheat 1, Preheat 2, and Automatic messages are regions within this profile in exhaust ...";
CM_ SG_ 2565869310 Aftrtrtmnt1IntkGsSnsrHtrPrlmnryF "Used to identify the applicable J1939-73 FMI detected in the heater of the intake exhaust gas sensor, either NOx or O2, by the manufacturer’s sensor control software in exhaust bank 1.  When there is no failure FMI 31 is sent.  In the case of ...";
CM_ SG_ 2565869310 Aftrtrtmnt1IntkWdRngO2RdngStable "Indicates that the %O2 reading of the aftertreatment intake gas sensor, either NOx or O2, is stable as determined by the manufacturer's control software in exhaust bank 1.

00 - Not stable
01 - Stable
10 - Error
11 - Not available";
CM_ SG_ 2565869310 Aftrtrtmnt1IntkeNOxReadingStable "Indicates that the NOx reading of the aftertreatment intake NOx sensor is stable as determined by the manufacturer’s control software in exhaust bank 1.

00 - Not stable
01 - Stable
10 - Error
11 - Not available";
CM_ SG_ 2565869310 Aftrtrtmnt1IntakeGasSensorAtTemp "Indicates that the heater element of the aftertreatment intake gas sensor, either NOx or O2, is within the manufacturer’s specified range for accurate measurements in exhaust bank 1.
00 - Not in range
01 - In range
10 - Error
11 - Not available
 ...";
CM_ SG_ 2565869310 Aftrtrtmnt1IntkGsSnsrPowerStatus "Indicates that the power supplied to the aftertreatment intake gas sensor, either NOx or O2, is within the manufacturer’s specification in exhaust bank 1.  This parameter reports the status as reported by the sensor.
00 - Not in range
01 - In ...";
CM_ SG_ 2565869310 Aftertreatment1IntakeO2 "The actual oxidation factor (%O2) of the gas within the exhaust stream.  For positive values, the parameter represents the percent oxygen in excess of the amount required for stoichiometric combustion.  For negative values, the parameter is ...";
CM_ SG_ 2565869310 Aftertreatment1IntakeNOx "The amount of combined NO and NO2 in the exhaust entering the aftertreatment system measured by a NOx sensor at the aftertreatment intake, represented in NOx molecule parts per million non-NOx molecules in exhaust bank 1.";
CM_ BO_ 2566763774 "The purpose of this PGN is to group the aftertreatment intake gas temperature messages for bank 1.";
CM_ SG_ 2566763774 Aftrtrtmnt1DslPrtcltFltrIntk3244 "Used to identify the applicable J1939-73 FMI detected in the diesel particulate filter intake temperature sensor by the manufacturer’s sensor control software in exhaust bank 1.  When there is no failure FMI 31 is sent.  In the case of multiple ...";
CM_ SG_ 2566763774 Aftrtrtmnt1ExhstGsTmp1PrlmnryFMI "Used to identify the applicable J1939-73 FMI detected in the exhaust temperature 1 sensor by the manufacturer’s sensor control software in exhaust bank 1.  When there is no failure FMI 31 is sent.  In the case of multiple failures the most severe is ...";
CM_ SG_ 2566763774 Aftrtrtmnt1DslPrtcltFltrIntkGsTm "Temperature of engine combustion byproducts entering the diesel particulate filter in exhaust bank 1.";
CM_ SG_ 2566763774 Aftertreatment1ExhaustGasTemp1 "The reading from the exhaust temperature sensor located farthest upstream in the aftertreatment system in exhaust bank 1.";
CM_ BO_ 2631728894 "NOTE–See Figures PGN56320_A to PGN56320_F for examples of Anti-theft message transfers.  Bit 1 is the right most bit in each byte.";
CM_ SG_ 2631728894 AntitheftRandomNumber "A seven byte random numeric code provided by the component in response to an anti-theft request.  This parameter is sent as a numeric value utilizing the full range of 0 to 0xFFFFFFFFFFFFFF.  The most significant byte is sent first, not following ...";
CM_ SG_ 2631728894 AntitheftModifyPwdStates "This parameter is used to indicate whether a password request was successfully performed, or if the request could not be perform due to system constraints or if the request was not a valid request.
00 Ok
01 Full_of_Passwords
10 Empty_of_Passwords
 ...";
CM_ SG_ 2631728894 AntitheftComponentStatusStates "Indicates whether or not the component can be started.
00 Unlocked
01 Locked
10 Blocked
11 Not defined
00b -  Unlocked = This state indicates that the component can be started without the end user being required to enter a password.
01b - ...";
CM_ SG_ 2631728894 AntitheftPwdValidIndicator "Indicates the presence of a validated password.

00 - Password is not a validated password
01 - Password is a validated password
10 - Error
11 - Not available";
CM_ SG_ 2631728894 AntthftEncryptnSdPrsentIndicator "Indicates the presence of the encryption seed random number.

00 - Random number is not present
01 - Random number is present
10 - Error
11 - Not available";
CM_ BO_ 2631794430 "NOTE–See Figures PGN56320_A thru PGN56320_F for examples of Anti-theft message transfers.  Bit 1 is the right most bit in each byte.";
CM_ SG_ 2631794430 AntitheftPwdRepresentation "This parameter is the seven byte numeric code (i.e., ‘encrypted password’ or ‘key’) that is generated based on the encryption algorithm, the password supplied by the end user, and the random number seed given by the component.  This parameter is ...";
CM_ SG_ 2631794430 AntitheftCmdStates "This parameter is used to identify the specific requests being sent to the component.
000 Add_Password
001 Delete_Password
010 Change_Password
011 Lock_or_Unlock
100 Check_Status
101 Login
110-111 Not defined
000b - Add_Password—This state ...";
CM_ SG_ 2631794430 AntitheftDesiredExitModeStates "This parameter is used to specify the desired triggers that are to be used by the component in deciding when to transition to the Locked state.
00 Lock_Upon_Operator_Request
01 Lock_When_Key_Off
10 Not defined
11 Not_Available
00b - ...";
CM_ SG_ 2631794430 AntthftEncryptionIndicatorStates "This parameter is used to indicate if a random number seed is being requested, or if an encrypted password is being provided to the component.
00 Encryption_Seed_Request
01 Encrypted_Code_Present
10 Not defined
11 Not_Available
00b - ...";
CM_ SG_ 2633934846 EngAltWinding3Temp "Temperature of the windings inside the alternator.";
CM_ SG_ 2633934846 EngAltWinding2Temp "Temperature of the windings inside the alternator.";
CM_ SG_ 2633934846 EngAltWinding1Temp "Temperature of the windings inside the alternator.";
CM_ SG_ 2633934846 EngAltBearing2Temp "Temperature of the bearing inside the alternator.  Bearing 2 is the right or front bearing.";
CM_ SG_ 2633934846 EngAltBearing1Temp "Temperature of the bearing inside the alternator.  Bearing 1 is the left or rear bearing.";
CM_ BO_ 2362572542 "Used for suspension control";
CM_ SG_ 2362572542 LevelPresetRearAxleRight "Set value for nominal level 'preset level' at the right side of the rear axle. This value is referred to 'Normal level 1'.  For explanations of normal level 1 see SPN 1734 - Nominal Level Front Axle.";
CM_ SG_ 2362572542 LevelPresetRearAxleLeft "Set value for nominal level 'preset level' at the left side of the rear axle. This value is referred to 'Normal level 1'.  For explanations of normal level 1 see SPN 1734 - Nominal Level Front Axle.";
CM_ SG_ 2362572542 LevelPresetFrontAxleRight "Set value for nominal level 'preset level' at the right side of the front axle. This value is referred to 'Normal level 1'.  For explanations of normal level 1 see SPN 1734 - Nominal Level Front Axle.";
CM_ SG_ 2362572542 LevelPresetFrontAxleLeft "Set value for nominal level 'preset level' at the left side of the front axle. This value is referred to 'Normal level 1'.  For explanations of normal level 1 see parameter SPN 1734 - Nominal Level Front Axle.";
CM_ BO_ 2365478910 "Used for damper stiffness information";
CM_ SG_ 2365478910 ElctrncShckAbsrbrCtrlMdLft_TgAxl "Signal which indicates the current mode of operation of the electronic shock absorber control at the lift/tag axle.

00 Normal operation dampers passive
01 Normal operation dampers active
10 Error
11 Not available";
CM_ SG_ 2365478910 ElctrncShckAbsrbrCtrlMdeRearAxle "Signal which indicates the current mode of operation of the electronic shock absorber control at the rear axle.

00 Normal operation dampers passive
01 Normal operation dampers active
10 Error
11 Not available";
CM_ SG_ 2365478910 ElctrncShckAbsrbrCtrlMdFrontAxle "Signal which indicates the current mode of operation of the electronic shock absorber control at the front axle.

00 Normal operation dampers passive
01 Normal operation dampers active
10 Error
11 Not available";
CM_ SG_ 2365478910 DamperStiffnessLift_TagAxle "Damper stiffness information of the shock absorber control at the lift of tag axle";
CM_ SG_ 2365478910 DamperStiffnessRearAxle "Damper stiffness information of the shock absorber control at the rear axle";
CM_ SG_ 2365478910 DamperStiffnessFrontAxle "Damper stiffness information of the shock absorber control at the front axle";
CM_ BO_ 2560950014 "This message conveys the scaled test results for the applicable test requested in DM7. The SPN and FMI convey the specific DTC for which the results are being reported.";
CM_ SG_ 2560950014 SPN1 "This 19-bit number is used to identify the item for which diagnostics are being reported.";
CM_ SG_ 2560950014 TestLimitMinimum "The test value must be greater than or equal to Test Limit Minimum in order for the test to pass";
CM_ SG_ 2560950014 FailureModeIdentifier1 "The FMI defines the type of failure detected in the subsystem identified by an SPN.";
CM_ SG_ 2560950014 TestLimitMaximum "The test value must be less than or equal to Test Limit Maximum in order for the test to pass.";
CM_ SG_ 2560950014 TestValue "The test value collected during the test.";
CM_ SG_ 2560950014 SlotId "The SLOT Identifer is used to determine the multiplier and offset to be used to scale the test value.";
CM_ SG_ 2560950014 TestIdentifier "Test Identifier";
CM_ SG_ 2560950014 SPN1High "SPN #1 (Conversion Version 4)";
CM_ BO_ 2566763262 "The purpose of this PGN is to group the aftertreatment intermediate gas temperature and pressure messages.
Note: The 5 bits of SPN 3253 are positioned into the data field in the following manner.  The 2 most significant bits are placed in bits 2-1 ...";
CM_ SG_ 2566763262 Aftrtrtmnt1DslPrtcltFltrIntr3254 "Used to identify the applicable J1939-73 FMI detected in the diesel particulate filter intermediate temperature sensor by the manufacturer’s sensor control software in exhaust bank 1.  When there is no failure FMI 31 is sent.  In the case of ...";
CM_ SG_ 2566763262 Aftrtrtmnt1DslPrtcltFltrDltPrssP "Used to identify the applicable J1939-73 FMI detected in the diesel particulate filter differential pressure sensor by the manufacturer’s sensor control software in exhaust bank 1.  When there is no failure FMI 31 is sent.  In the case of multiple ...";
CM_ SG_ 2566763262 Aftrtrtmnt1ExhstGsTmp2PrlmnryFMI "Used to identify the applicable J1939-73 FMI detected in the exhaust temperature 2 sensor by the manufacturer’s sensor control software in exhaust bank 1.  When there is no failure FMI 31 is sent.  In the case of multiple failures the most severe is ...";
CM_ SG_ 2566763262 Aftrtrtmnt1DslPrtcltFltrDffPress "Exhaust differential pressure measured between the intake and exhaust of a diesel particulate filter in exhaust bank 1.";
CM_ SG_ 2566763262 Aftrtrtmnt1DslPrtcltFltrIntrmdtG "Temperature of engine combustion byproducts at a mid-point in the diesel particulate filter in exhaust bank 1.";
CM_ SG_ 2566763262 Aftertreatment1ExhaustGasTemp2 "The reading from the exhaust temperature sensor located midstream of the other two temperature sensors in the aftertreatment system in exhaust bank 1.";
CM_ BO_ 2565869566 "The purpose of this PGN is to group the aftertreatment outlet sensor data for bank 1.  These values include the NOx, %O2 , Status's of the sensors with respect to the power being supplied and the heating element, errors and stability of the ...";
CM_ SG_ 2565869566 Aftrtrtmnt1OtltOxygnSnsrPrlmnryF "Used to identify the applicable J1939-73 FMI detected in the aftertreatment outlet oxygen sensor by the manufacturer’s sensor control software in exhaust bank 1.  When there is no failure FMI 31 is sent.  In the case of multiple failures the most ...";
CM_ SG_ 2565869566 NOxSensorATO1SelfdiagnosisStatus "Self-diagnosis result status for NOx sensor ATO1 (Aftertreatment Outlet Bank 1)
000 Diagnosis not active
001 NOx Sensor ATO1 Self Diagnosis active flag
010 NOx Sensor ATO1 Self Diagnosis Result Complete
011 NOx Sensor ATO1 Self Diagnosis aborted
 ...";
CM_ SG_ 2565869566 Aftrtrtmnt1OtltNOxSnsrPrlmnryFMI "Used to identify the applicable J1939-73 FMI detected in the aftertreatment outlet NOx sensor by the manufacturer’s sensor control software in exhaust bank 1.  When there is no failure FMI 31 is sent.  In the case of multiple failures the most ...";
CM_ SG_ 2565869566 Aftrtrtmnt1OtltGsSnsorHeaterCtrl "Indicates the heater status in the warm-up process.  Upon receiving a power-up command, the gas sensor ramps up according to a manufacturer defined profile.  The Preheat 1, Preheat 2, and Automatic messages are regions within this profile in exhaust ...";
CM_ SG_ 2565869566 Aftrtrtmnt1OtltGsSnsrHtrPrlmnryF "Used to identify the applicable J1939-73 FMI detected in the heater of the outlet exhaust gas sensor, either NOx or O2, by the manufacturer’s sensor control software in exhaust bank 1.  When there is no failure FMI 31 is sent.  In the case of ...";
CM_ SG_ 2565869566 Aftrtrtmnt1OtltWdRngO2RdngStable "Indicates that the %O2 reading of the aftertreatment outlet gas sensor, either NOx or O2, is stable as determined by the manufacturer's control software in exhaust bank 1.

00 - Not stable
01 - Stable
10 - Error
11 - Not available";
CM_ SG_ 2565869566 Aftrtrtmnt1OtletNOxReadingStable "Indicates that the NOx reading of the aftertreatment outlet NOx sensor is stable as determined by the manufacturer’s control software in exhaust bank 1.

00 - Not stable
01 - Stable
10 - Error
11 - Not available";
CM_ SG_ 2565869566 Aftrtrtmnt1OutletGasSensorAtTemp "Indicates that the heater element of the aftertreatment outlet gas sensor, either NOx or O2, is within the manufacturer’s specified range for accurate measurements in exhaust bank 1.
00 - Not in range
01 - In range
10 - Error
11 - Not available
 ...";
CM_ SG_ 2565869566 Aftrtrtmnt1OtltGsSnsrPowerStatus "Indicates that the power supplied to the aftertreatment outlet gas sensor, either NOx or O2, is within the manufacturer’s specification in exhaust bank 1. This parameter reports the status as reported by the sensor.
00 - Not in range
01 - In range
 ...";
CM_ SG_ 2565869566 Aftertreatment1OutletO2 "The actual oxidation factor (%O2) of the gas within the exhaust stream.  For positive values, the parameter represents the percent oxygen in excess of the amount required for stoichiometric combustion.  For negative values, the parameter is ...";
CM_ SG_ 2565869566 Aftertreatment1OutletNOx "The amount of combined NO and NO2 in the exhaust exiting the aftertreatment system measured by a NOx sensor at the aftertreatment outlet, represented in NOx molecule parts per million non-NOx molecules in exhaust bank 1.";
CM_ BO_ 2566763518 "The purpose of this PGN is to group the aftertreatment outlet gas temperature messages.";
CM_ SG_ 2566763518 Aftrtrtmnt1DslPrtcltFltrOtltExhs "Used to identify the applicable J1939-73 FMI detected in the diesel particulate filter outlet temperature sensor by the manufacturer’s sensor control software in exhaust bank 1.  When there is no failure FMI 31 is sent.  In the case of multiple ...";
CM_ SG_ 2566763518 Aftrtrtmnt1ExhstGsTmp3PrlmnryFMI "Used to identify the applicable J1939-73 FMI detected in the exhaust temperature 3 sensor by the manufacturer’s sensor control software in exhaust bank 1.  When there is no failure FMI 31 is sent.  In the case of multiple failures the most severe is ...";
CM_ SG_ 2566763518 Aftrtrtmnt1DslPrtcltFltrOtltGsTm "Temperature of engine combustion byproducts leaving the diesel particulate filter exhaust in exhaust bank 1.";
CM_ SG_ 2566763518 Aftertreatment1ExhaustGasTemp3 "The reading from the exhaust temperature sensor located farthest downstream in the aftertreatment system in exhaust bank 1.";
CM_ BO_ 2566749182 "This PGN contains information about the aftertreatment 1 (diesel particulate filter 1 soot and ash load).";
CM_ SG_ 2566749182 Aftrtrtmnt1DslPrtcltFltrStLdRgnr "This parameter indicates the value that will first cause DPF regeneration in aftertreatment 1. There may be multiple parameters that cause DPF regeneration (e.g. Percent Soot Load, DPF delta pressure converted to normalized percentage, etc.).  If ...";
CM_ SG_ 2566749182 DslPrtcltFltr1TmSncLstActvRgnrtn "Indicates the time since the last active regeneration event of diesel particulate filter 1.";
CM_ SG_ 2566749182 DslPrtclateFilter1AshLoadPercent "Indicates the ash load percent of diesel particulate filter 1.  100% is the level at which diesel particulate filter ash service should be performed.
100% level is the target ash service interval (and if ash service is not immediately performed, ...";
CM_ SG_ 2566749182 DslPrtclteFilter1SootLoadPercent "Indicates the soot load percent of diesel particulate filter 1.  100% is the level at which active diesel particulate filter regeneration should be triggered.
100% level is the active regeneration trigger level (and if conditions are not favorable ...";
CM_ BO_ 2566748670 "This PGN contains trip total information about the aftertreatment 1.  

NOTE: The SPNs in this PGN need to be reset by the reset PGN 56832.";
CM_ SG_ 2566748670 Aftrtrtmnt1DslPrtcltFltrTrpN3740 "Total number of aftertreatment 1 diesel particulate filter active regeneration manual requests by the operator during the current trip period.

NOTE: This SPN needs to be reset by the reset PGN 56832.";
CM_ SG_ 2566748670 Aftrtrtmnt1DslPrtcltFltrTrpN3739 "Total number of aftertreatment 1 diesel particulate filter active regeneration inhibit requests by the operator during the current trip period.

NOTE: This SPN needs to be reset by the reset PGN 56832.";
CM_ SG_ 2566748670 Aftrtrtmnt1DslPrtcltFltrTrpN3738 "Total number of passive regenerations of the aftertreatment 1 diesel particulate filter during the current trip period.

NOTE: This SPN needs to be reset by the reset PGN 56832.";
CM_ SG_ 2566748670 Aftrtrtmnt1DslPrtcltFltrTrpPssvR "Total amount of time that the aftertreatment 1 diesel particulate filter has been in passive regeneration during the current trip period.

NOTE: This SPN needs to be reset by the reset PGN 56832.";
CM_ SG_ 2566748670 Aftrtrtmnt1DslPrtcltFltrTrpNmbrO "Total number of active regenerations of the aftertreatment 1 diesel particulate filter during the current trip period.

NOTE: This SPN needs to be reset by the reset PGN 56832.";
CM_ SG_ 2566748670 Aftrtrtmnt1DslPrtcltFltrTrpDsbld "Total amount of time that aftertreatment 1 diesel particulate filter regeneration has been manually disabled during the current trip period.

NOTE: This SPN needs to be reset by the reset PGN 56832.";
CM_ SG_ 2566748670 Aftrtrtmnt1DslPrtcltFltrTrpActvR "Total amount of time that the aftertreatment 1 diesel particulate filter has been in active regeneration during the current trip period.

NOTE: This SPN needs to be reset by the reset PGN 56832.";
CM_ SG_ 2566748670 Aftrtrtmnt1DslPrtcltFltrTrpFlUsd "Total amount of fuel used by the aftertreatment 1 diesel particulate filter during the current trip period.

NOTE: This SPN needs to be reset by the reset PGN 56832.";
CM_ BO_ 2566758142 "Contains information about the aftertreatment 2 air system";
CM_ SG_ 2566758142 Aftertreatment2AirEnableActuator "Indicates whether aftertreatment 2 air enable actuator is on or off

00   not active
01   active
10   reserved for SAE assignment
11   not available";
CM_ SG_ 2566758142 Aftertreatment2PurgeAirActuator "Indicates whether aftertreatment 2 purge air actuator is on or off

00   not active
01   active
10   reserved for SAE assignment
11   not available";
CM_ SG_ 2566758142 Aftrtrtmnt2AtmizationAirActuator "Indicates whether aftertreatment 2 atomization air actuator is on or off

00   not active
01   active
10   reserved for SAE assignment
11   not available";
CM_ SG_ 2566758142 Aftertreatment2AirSystemRelay "Indicates whether aftertreatment 2 air system relay is on or off

00   not active
01   active
10   reserved for SAE assignment
11   not available";
CM_ SG_ 2566758142 Aftrtratment2AirPressActuatorPos "Position of the aftertreatment 2 air pressure actuator as measured by a position feedback sensor.";
CM_ SG_ 2566758142 Aftertreatment2AirPressCtrl "Position that the controller is commanding the aftertreatment 2 air pressure control to maintain.  0% = fully closed, 100% = fully open";
CM_ SG_ 2566758142 Aftertreatment2PurgeAirPress "Pressure of the purge air supply for aftertreatment 2";
CM_ SG_ 2566758142 Aftertreatment2SupplyAirPress "Pressure of the supply air for aftertreatment 2.  Supply air is the air supplied from a pneumatic line for an air-assisted or pneumatic actuator.  One example is an air assisted fuel injector (the supply air assists in the atomization of fuel).";
CM_ BO_ 2566745342 "This PGN contains information about the Aftertreatment 2 Air Control.  

NOTE: This message will be transmitted by the engine or aftertreatment controller.  Other aftertreatment air control information could be added in the future.";
CM_ SG_ 2566745342 Aftertreatment2SecondAirPress "Pressure of the secondary air for aftertreatment 2.  Secondary air is air provided to the exhaust system (per SAE J2403).

For absolute pressure, see SPN 5590.";
CM_ SG_ 2566745342 Aftertreatment2SecondAirMassFlow "Indicates the secondary air mass flow for aftertreatment 2.  Secondary air is the air provided to the exhaust system (per SAE J2403).";
CM_ SG_ 2566745342 Aftertreatment2SecondAirTemp "Indicates the secondary air temperature for aftertreatment 2.  Secondary air is air provided to the exhaust system (per SAE J2403).";
CM_ SG_ 2566745342 Aftrtreatment2SecondAirDiffPress "Indicates the secondary air differential pressure for aftertreatment 2.  Secondary air is air provided to the exhaust system (per SAE J2403).";
CM_ BO_ 2566758654 "Contains information about the aftertreatment 2 fuel system";
CM_ SG_ 2566758654 Aftrtrtmnt2FlInjector1HeaterCtrl "Heating level that the controller is commanding the aftertreatment 2 fuel injector 1 heater control to maintain. 0% = off, 100% = maximum.";
CM_ SG_ 2566758654 Aftrtreatment2FuelEnableActuator "Indicates whether aftertreatment 2 fuel enable actuator is on or off

00   not active
01   active
10   reserved for SAE assignment
11   not available";
CM_ SG_ 2566758654 Aftrtreatment2RegenerationStatus "Indicates whether regeneration is active or inactive in aftertreatment 2.  

00   not active
01   active
10   reserved for SAE assignment
11   not available";
CM_ SG_ 2566758654 Aftertreatment2Ignt "Indicates whether aftertreatment 2 ignition circuit is energized by the ECM.

00   not active
01   active
10   reserved for SAE assignment
11   not available";
CM_ SG_ 2566758654 Aftertreatment2FuelDrainActuator "Indicates whether aftertreatment 2 fuel drain actuator is on or off

00   not active
01   active
10   reserved for SAE assignment
11   not available";
CM_ SG_ 2566758654 Aftertreatment2FuelPress1Ctrl "Position that the controller is commanding the aftertreatment 2 fuel pressure control to maintain.  0% = fully closed, 100% = fully open.";
CM_ SG_ 2566758654 Aftertreatment2FuelRate "Rate of fuel being delivered to aftertreatment 2 for regeneration";
CM_ SG_ 2566758654 Aftertreatment2FuelPress1 "Pressure of the fuel for Aftertreatment 2.";
CM_ BO_ 2566753278 "Diesel particulate filter gas parameters for system or bank 2";
CM_ SG_ 2566753278 DslParticulateFilterOutletPress2 "This parameter indicates the diesel particulate filter outlet gage pressure 2 (bank 2).";
CM_ SG_ 2566753278 DslParticulateFilterIntakePress2 "This parameter indicates the diesel particulate filter intake gage pressure 2 (bank 2).";
CM_ BO_ 2566756862 "Contains information about the history of the aftertreatment 2 system";
CM_ SG_ 2566756862 Aftrtrtmnt2AvrgDstncBtwnActvDPFR "Indicates the average distance since last reset between active regenerations, that have not been forced to occur by manual request, for Aftertreatment device 2.
If the manufacturer allows this parameter to be reset, this distance is the average ...";
CM_ SG_ 2566756862 Aftrtrtmnt2AvrgTmBtwnActvRgnrtns "Indicates the average time since last reset between active regenerations, that have not been forced to occur by manual request, for Aftertreatment device 2.";
CM_ SG_ 2566756862 Aftrtrtmnt2DslPrtcltFltrTtlN3732 "Total number of Aftertreatment device 2 active regeneration manual requests by the operator over the lifetime of the device.";
CM_ SG_ 2566756862 Aftrtrtmnt2DslPrtcltFltrTtlN3731 "Total number of Aftertreatment device 2 active regeneration inhibit requests by the operator over the lifetime of the device.";
CM_ SG_ 2566756862 Aftrtrtmnt2DslPrtcltFltrTtlNmbrO "Total number of passive regenerations by Aftertreatment device 2 over the lifetime of the device.";
CM_ SG_ 2566756862 Aftrtrtmnt2DslPrtcltFltrTtlPssvR "Total amount of time that Aftertreatment device 2 has been in passive regeneration over the lifetime of the device.";
CM_ SG_ 2566756862 Aftrtrtmnt2TtlNmbrOfActvRgnrtons "Total number of active regenerations by aftertreatment device 2 over the lifetime of the device.";
CM_ SG_ 2566756862 Aftertreatment2TotalDisabledTime "Total amount of time that aftertreatment 2 regeneration has been manually disabled.";
CM_ SG_ 2566756862 Aftrtrtmnt2TotalRegenerationTime "Total amount of time that aftertreatment device 2 has been regenerating over the lifetime of the device.";
CM_ SG_ 2566756862 Aftertreatment2TotalFuelUsed "Total amount of fuel used by aftertreatment device 2 over the lifetime of the device.";
CM_ BO_ 2565869822 "The purpose of this PGN is to group the aftertreatment intake sensor data for bank 2.  These values include the NOx, %O2, status of the sensors with respect to the power being supplied and the heating element, errors and stability of the readings.";
CM_ SG_ 2565869822 NOxSensorATI2SelfdiagnosisStatus "Self-diagnosis result status for NOx sensor ATI2 (Aftertreatment Intake Bank 2)
000 Diagnosis not active
001 NOx Sensor ATI2 Self Diagnosis active flag
010 NOx Sensor ATI2 Self Diagnosis Result Complete
011 NOx Sensor ATI2 Self Diagnosis aborted
 ...";
CM_ SG_ 2565869822 Aftrtrtmnt2IntkOxygnSnsrPrlmnryF "Used to identify the applicable J1939-73 FMI detected in the aftertreatment intake oxygen sensor by the manufacturer’s sensor control software in exhaust bank 2.  When there is no failure FMI 31 is sent.  In the case of multiple failures the most ...";
CM_ SG_ 2565869822 Aftrtrtmnt2IntkNOxSnsrPrlmnryFMI "Used to identify the applicable J1939-73 FMI detected in the aftertreatment intake NOx sensor by the manufacturer’s sensor control software in exhaust bank 2.  When there is no failure FMI 31 is sent.  In the case of multiple failures the most ...";
CM_ SG_ 2565869822 Aftrtrtmnt2IntkGsSnsorHeaterCtrl "Indicates the heater status in the warm-up process.  Upon receiving a power-up command, the gas sensor ramps up according to a manufacturer defined profile.  The Preheat 1, Preheat 2, and Automatic messages are regions within this profile in exhaust ...";
CM_ SG_ 2565869822 Aftrtrtmnt2IntkGsSnsrHtrPrlmnryF "Used to identify the applicable J1939-73 FMI detected in the heater of the intake exhaust gas sensor, either NOx or O2, by the manufacturer’s sensor control software in exhaust bank 2.  When there is no failure FMI 31 is sent.  In the case of ...";
CM_ SG_ 2565869822 Aftrtrtmnt2IntkWdRngO2RdngStable "Indicates that the %O2 reading of the aftertreatment intake gas sensor, either NOx or O2, is stable as determined by the manufacturer's control software in exhaust bank 2. (For a single exhaust bank system, refer to parameters in PGNs 61454, 61455, ...";
CM_ SG_ 2565869822 Aftrtrtmnt2IntkeNOxReadingStable "Indicates that the NOx reading of the aftertreatment intake NOx sensor is stable as determined by the manufacturer’s control software in exhaust bank 2. (For a single exhaust bank system, refer to parameters in PGNs 61454, 61455,  64946, 64947, ...";
CM_ SG_ 2565869822 Aftrtrtmnt2IntakeGasSensorAtTemp "Indicates that the heater element of the aftertreatment intake gas sensor, either NOx or O2, is within the manufacturer’s specified range for accurate measurements in exhaust bank 2.    (For a single exhaust bank system, refer to parameters in PGNs ...";
CM_ SG_ 2565869822 Aftrtrtmnt2IntkGsSnsrPowerStatus "Indicates that the power supplied to the aftertreatment intake gas sensor, either NOx or O2, is within the manufacturer’s specification in exhaust bank 2.  (For a single exhaust bank system, refer to parameters in PGNs 61454, 61455,  64946, 64947, ...";
CM_ SG_ 2565869822 Aftertreatment2IntakeO2 "The actual oxidation factor (%O2) of the gas within the exhaust stream.  For positive values, the parameter represents the percent oxygen in excess of the amount required for stoichiometric combustion.  For negative values, the parameter is ...";
CM_ SG_ 2565869822 Aftertreatment2IntakeNOx "The amount of combined NO and NO2 in the exhaust entering the aftertreatment system measured by a NOx sensor at the aftertreatment intake, represented in NOx molecule parts per million non-NOx molecules in exhaust bank 2.  (For a single exhaust bank ...";
CM_ BO_ 2566763006 "The purpose of this PGN is to group the aftertreatment intake gas temperature messages for bank 2.";
CM_ SG_ 2566763006 Aftrtrtmnt2DslPrtcltFltrIntk3278 "Used to identify the applicable J1939-73 FMI detected in the diesel particulate filter intake temperature sensor by the manufacturer’s sensor control software in exhaust bank 2.  When there is no failure FMI 31 is sent.  In the case of multiple ...";
CM_ SG_ 2566763006 Aftrtrtmnt2ExhstGsTmp1PrlmnryFMI "Used to identify the applicable J1939-73 FMI detected in the exhaust temperature 1 sensor by the manufacturer’s sensor control software in exhaust bank 2.  When there is no failure FMI 31 is sent.  In the case of multiple failures the most severe is ...";
CM_ SG_ 2566763006 Aftrtrtmnt2DslPrtcltFltrIntkGsTm "Temperature of engine combustion byproducts entering the diesel particulate filter in exhaust bank 2.  (For a single exhaust bank system, refer to parameters in PGNs 61454, 61455,  64946, 64947, 64948, and 65247)";
CM_ SG_ 2566763006 Aftertreatment2ExhaustGasTemp1 "The reading from the exhaust temperature sensor located farthest upstream in the aftertreatment system in exhaust bank 2.  (For a single exhaust bank system, refer to parameters in PGNs 61454, 61455,  64946, 64947, 64948, and 65247)";
CM_ BO_ 2566762494 "The purpose of this PGN is to group the aftertreatment intermediate gas temperature and pressure messages for bank 2.";
CM_ SG_ 2566762494 Aftrtrtmnt2DslPrtcltFltrIntr3288 "Used to identify the applicable J1939-73 FMI detected in the diesel particulate filter intermediate temperature sensor by the manufacturer’s sensor control software in exhaust bank 2.  When there is no failure FMI 31 is sent.  In the case of ...";
CM_ SG_ 2566762494 Aftrtrtmnt2DslPrtcltFltrDltPrssP "Used to identify the applicable J1939-73 FMI detected in the diesel particulate filter differential pressure sensor by the manufacturer’s sensor control software in exhaust bank 2.  When there is no failure FMI 31 is sent.  In the case of multiple ...";
CM_ SG_ 2566762494 Aftrtrtmnt2ExhstGsTmp2PrlmnryFMI "Used to identify the applicable J1939-73 FMI detected in the exhaust temperature 2 sensor by the manufacturer’s sensor control software in exhaust bank 2.  When there is no failure FMI 31 is sent.  In the case of multiple failures the most severe is ...";
CM_ SG_ 2566762494 Aftrtrtmnt2DslPrtcltFltrDffPress "Exhaust differential pressure measured between the intake and exhaust of a diesel particulate filter in exhaust bank 2.  (For a single exhaust bank system, refer to parameters in PGNs 61454, 61455,  64946, 64947, 64948, and 65247)";
CM_ SG_ 2566762494 Aftrtrtmnt2DslPrtcltFltrIntrmdtG "Temperature of engine combustion byproducts at a mid-point in the diesel particulate filter in exhaust bank 2.  (For a single exhaust bank system, refer to parameters in PGNs 61454, 61455,  64946, 64947, 64948, and 65247)";
CM_ SG_ 2566762494 Aftertreatment2ExhaustGasTemp2 "The reading from the exhaust temperature sensor located midstream of the other two temperature sensors in the aftertreatment system in exhaust bank 2.  (For a single exhaust bank system, refer to parameters in PGNs 61454, 61455,  64946, 64947, ...";
CM_ BO_ 2565870078 "The purpose of this PGN is to group the aftertreatment outlet sensor data for bank 2.  These values include the NOx, %O2, status of the sensors with respect to the power being supplied and the heating element, errors and stability of the readings.";
CM_ SG_ 2565870078 Aftrtrtmnt2OtltOxygnSnsrPrlmnryF "Used to identify the applicable J1939-73 FMI detected in the aftertreatment outlet oxygen sensor by the manufacturer’s sensor control software in exhaust bank 2.  When there is no failure FMI 31 is sent.  In the case of multiple failures the most ...";
CM_ SG_ 2565870078 Aftrtrtmnt2OtltNOxSnsrPrlmnryFMI "Used to identify the applicable J1939-73 FMI detected in the aftertreatment outlet NOx sensor by the manufacturer’s sensor control software in exhaust bank 2.  When there is no failure FMI 31 is sent.  In the case of multiple failures the most ...";
CM_ SG_ 2565870078 Aftrtrtmnt2OtltGsSnsorHeaterCtrl "Indicates the heater status in the warm-up process.  Upon receiving a power-up command, the gas sensor ramps up according to a manufacturer defined profile.  The Preheat 1, Preheat 2, and Automatic messages are regions within this profile in exhaust ...";
CM_ SG_ 2565870078 Aftrtrtmnt2OtltGsSnsrHtrPrlmnryF "Used to identify the applicable J1939-73 FMI detected in the heater of the outlet exhaust gas sensor, either NOx or O2, by the manufacturer’s sensor control software in exhaust bank 2.  When there is no failure FMI 31 is sent.  In the case of ...";
CM_ SG_ 2565870078 Aftrtrtmnt2OtltWdRngO2RdngStable "Indicates that the %O2 reading of the aftertreatment outlet gas sensor, either NOx or O2, is stable as determined by the manufacturer's control software in exhaust bank 2.  (For a single exhaust bank system, refer to parameters in PGNs 61454, 61455, ...";
CM_ SG_ 2565870078 Aftrtrtmnt2OtletNOxReadingStable "Indicates that the NOx reading of the aftertreatment outlet NOx sensor is stable as determined by the manufacturer’s control software in exhaust bank 2.  (For a single exhaust bank system, refer to parameters in PGNs 61454, 61455,  64946, 64947, ...";
CM_ SG_ 2565870078 NOxSensorATO2SelfdiagnosisStatus "Self-diagnosis result status for NOx sensor ATO2 (Aftertreatment Outlet Bank 2)
000 Diagnosis not active
001 NOx Sensor ATO2 Self Diagnosis active flag
010 NOx Sensor ATO2 Self Diagnosis Result Complete
011 NOx Sensor ATO2 Self Diagnosis aborted
 ...";
CM_ SG_ 2565870078 Aftrtrtmnt2OutletGasSensorAtTemp "Indicates that the heater element of the aftertreatment outlet gas sensor, either NOx or O2, is within the manufacturer’s specified range for accurate measurements in exhaust bank 2.  (For a single exhaust bank system, refer to parameters in PGNs ...";
CM_ SG_ 2565870078 Aftrtrtmnt2OtltGsSnsrPowerStatus "Indicates that the power supplied to the aftertreatment outlet gas sensor, either NOx or O2, is within the manufacturer’s specification in exhaust bank 2.  (For a single exhaust bank system, refer to parameters in PGNs 61454, 61455,  64946, 64947, ...";
CM_ SG_ 2565870078 Aftertreatment2OutletO2 "The actual oxidation factor (%O2) of the gas within the exhaust stream.  For positive values, the parameter represents the percent oxygen in excess of the amount required for stoichiometric combustion.  For negative values, the parameter is ...";
CM_ SG_ 2565870078 Aftertreatment2OutletNOx "The amount of combined NO and NO2 in the exhaust entering the aftertreatment system measured by a NOx sensor at the aftertreatment outlet, represented in NOx molecule parts per million non-NOx molecules in exhaust bank 2. (For a single exhaust bank ...";
CM_ BO_ 2566762750 "The purpose of this PGN is to group the aftertreatment outlet gas temperature messages for bank 2.";
CM_ SG_ 2566762750 Aftrtrtmnt2DslPrtcltFltrExhstGsT "Used to identify the applicable J1939-73 FMI detected in the diesel particulate filter outlet temperature sensor by the manufacturer’s sensor control software in exhaust bank 2.  When there is no failure FMI 31 is sent.  In the case of multiple ...";
CM_ SG_ 2566762750 Aftrtrtmnt2ExhstGsTmp3PrlmnryFMI "Used to identify the applicable J1939-73 FMI detected in the exhaust temperature 3 sensor by the manufacturer’s sensor control software in exhaust bank 2.  When there is no failure FMI 31 is sent.  In the case of multiple failures the most severe is ...";
CM_ SG_ 2566762750 Aftrtrtmnt2DslPrtcltFltrOtltGsTm "Temperature of engine combustion byproducts leaving the diesel particulate filter exhaust in exhaust bank 2.  (For a single exhaust bank system, refer to parameters in PGNs 61454, 61455,  64946, 64947, 64948, and 65247)";
CM_ SG_ 2566762750 Aftertreatment2ExhaustGasTemp3 "The reading from the exhaust temperature sensor located farthest downstream in the aftertreatment system in exhaust bank 2.  (For a single exhaust bank system, refer to parameters in PGNs 61454, 61455,  64946, 64947, 64948, and 65247)";
CM_ BO_ 2566748926 "This PGN contains information about the aftertreatment 2 (diesel particulate filter 2 soot and ash load).";
CM_ SG_ 2566748926 Aftrtrtmnt2DslPrtcltFltrStLdRgnr "This parameter indicates the value that will first cause DPF regeneration in aftertreatment 2. There may be multiple parameters that cause DPF regeneration (e.g. Percent Soot Load, DPF delta pressure converted to normalized percentage, etc.).  If ...";
CM_ SG_ 2566748926 DslPrtcltFltr2TmSncLstActvRgnrtn "Indicates the time since the last active regeneration event of diesel particulate filter 2.";
CM_ SG_ 2566748926 DslPrtclateFilter2AshLoadPercent "Indicates the ash load percent of diesel particulate filter 2.  100% is the level at which diesel particulate filter ash service should be performed.
100% level is the target ash service interval (and if ash service is not immediately performed, ...";
CM_ SG_ 2566748926 DslPrtclteFilter2SootLoadPercent "Indicates the soot load percent of diesel particulate filter 2.  100% is the level at which active diesel particulate filter regeneration should be triggered.
100% level is the active regeneration trigger level (and if conditions are not favorable ...";
CM_ BO_ 2566748414 "This PGN contains trip total information about the aftertreatment 2.  

NOTE: The SPNs in this PGN need to be reset by the reset PGN 56832.";
CM_ SG_ 2566748414 Aftrtrtmnt2DslPrtcltFltrTrpN3748 "Total number of aftertreatment 2 diesel particulate filter active regeneration manual requests by the operator during the current trip period.

NOTE: This SPN needs to be reset by the reset PGN 56832.";
CM_ SG_ 2566748414 Aftrtrtmnt2DslPrtcltFltrTrpN3747 "Total number of aftertreatment 2 diesel particulate filter active regeneration inhibit requests by the operator during the current trip period.

NOTE: This SPN needs to be reset by the reset PGN 56832.";
CM_ SG_ 2566748414 Aftrtrtmnt2DslPrtcltFltrTrpN3746 "Total number of passive regenerations of the aftertreatment 2 diesel particulate filter during the current trip period.

NOTE: This SPN needs to be reset by the reset PGN 56832.";
CM_ SG_ 2566748414 Aftrtrtmnt2DslPrtcltFltrTrpPssvR "Total amount of time that the aftertreatment 2 diesel particulate filter has been in passive regeneration during the current trip period.

NOTE: This SPN needs to be reset by the reset PGN 56832.";
CM_ SG_ 2566748414 Aftrtrtmnt2DslPrtcltFltrTrpNmbrO "Total number of active regenerations of the aftertreatment 2 diesel particulate filter during the current trip period.

NOTE: This SPN needs to be reset by the reset PGN 56832.";
CM_ SG_ 2566748414 Aftrtrtmnt2DslPrtcltFltrTrpDsbld "Total amount of time that aftertreatment 2 diesel particulate filter regeneration has been manually disabled during the current trip period.

NOTE: This SPN needs to be reset by the reset PGN 56832.";
CM_ SG_ 2566748414 Aftrtrtmnt2DslPrtcltFltrTrpActvR "Total amount of time that the aftertreatment 2 diesel particulate filter has been in active regeneration during the current trip period.

NOTE: This SPN needs to be reset by the reset PGN 56832.";
CM_ SG_ 2566748414 Aftrtrtmnt2DslPrtcltFltrTrpFlUsd "Total amount of fuel used by the aftertreatment 2 diesel particulate filter during the current trip period.

NOTE: This SPN needs to be reset by the reset PGN 56832.";
CM_ BO_ 2365428478 "Contains engine parameters related to operation.";
CM_ SG_ 2365428478 EngStarterMotorRelayCtrl "Command signal used to energize or de-energize the engine starter motor relay.

00 Off
01 On
10 Reserved for SAE assignment
11 Don't care/take no action";
CM_ SG_ 2365428478 EngDerateRq "This parameter is a derate request made from the engine control system to an external system, where the engine is requesting an external device to reduce the load being applied.  A zero value indicates that there is no derate being requested and ...";
CM_ SG_ 2365428478 EngEmergencyShutdownIndication "A signal issued by the engine control system to a user or external system indicating that it is immediately shutting the engine down.  This indication is made when engine protection diagnostics determine a condition necessitates an immediate ...";
CM_ SG_ 2365428478 EngControlledShutdownRq "A signal issued by the engine control system to a user or external system requesting for a controlled shutdown.  This request is made when engine protection diagnostics determine a condition warrants a shutdown soon, but it is not severe enough to ...";
CM_ SG_ 2365428478 EngCoolantCirculatingPumpCtrl "Control setting for an electrically actuated engine coolant circulating pump. 

00 = Off
01 = On
10 = Reserved
11 = Don't care / take no action
.";
CM_ SG_ 2365428478 EngBlock_CoolantPreheaterCtrl "Control setting for an electrically actuated engine block or coolant pre-heating device.

00 - Off 
01 - On
10 - Reserved
11 - Unavailable";
CM_ SG_ 2365428478 EngElctrclSystmPwrCnsrvationCtrl "Control setting for cutting power to various devices when the engine is not in use.  Useful if it is desired to keep the engine in standby, with main control ECM still powered on and communictaing with outside world, but actuators and certain other ...";
CM_ SG_ 2365428478 EngOilPreheaterCtrl "Control setting for an electrically actuated oil pre-heating device.
00 = Off
01 = On
10 = Reserved
11 = Don't care / take no action
In addition to communicating desired action of the electrically actuated oil pre-heater and its driver status, ...";
CM_ SG_ 2365428478 EngOilPrimingPumpCtrl "This control is used to activate a pump that lubricates the engine, particularly prior to initial engine startup.

00 = Off
01 = On
10 = Reserved
11 = unavailable";
CM_ SG_ 2365428478 EngFuelShutoffValveLeakTestCtrl "Control setting for fuel shutoff valve proving system test.  Typically, this type of system can only be used with a dual fuel shutoff system.  The test consists of a small pump to pressurize the chamber between the dual fuel shutoffs when they are ...";
CM_ SG_ 2365428478 EngFuelShutoff2Ctrl "Control setting for fuel shutoff 2.  First instance is SPN 632.  For a dual fuel shutoff system, this SPN is representative of the downstream fuel shutoff commanded position.  When fuel (gas) is desired at the engine, the fuel shutoff is opened ...";
CM_ SG_ 2365428478 EngFuelShutoff1Ctrl "Control setting for fuel shutoff 1.  The second instance is SPN 2807.  For a single fuel shutoff system, this represents its commanded position.  For a dual fuel shutoff system, this SPN is representative of the upstream fuel shutoff commanded ...";
CM_ SG_ 2365428478 EngFuelShutoffVentCtrl "Control setting for a fuel shutoff vent.  Typically, for a dual fuel shutoff system, the vent line is located between them and is plumbed to vent outside to atmosphere.  The vent control typically always actuates opposite to that of the fuel ...";
CM_ SG_ 2365428478 TimeRemainingInEngOperatingState "This parameter is used to indicate the time remaining in the current engine operating state, based on the state defined in the SPN \"Engine Operating State\" (SPN 3543). For the states in which time remaining is not applicable, use 65535 ($FFFF).";
CM_ SG_ 2365428478 FuelPumpPrimerCtrl "Parameter used to activate or deactivate a priming system on the fuel transfer system. The fuel priming system is a system that purges air in the fuel lines and may assist fuel delivery to a second pump at lower speeds.
00 = Deactivate
01 = ...";
CM_ SG_ 2365428478 EngOperatingState "This parameter is used to indicate the current state, or mode, of operation by the engine.  This is a status parameter.
Bit state 0000 = Engine Stopped
Bit state 0001 = Pre-Start
Bit state 0010 = Starting
Bit state 0011 = Warm-Up
Bit state 0100 ...";
CM_ BO_ 2566743806 "Engine temperatures";
CM_ SG_ 2566743806 EngCoolantTemp3 "Third temperature of liquid found in the engine cooling system. See also SPNs 110, 4076 and 4193.";
CM_ SG_ 2566743806 EngExhstGsRcrcltn1MxerIntakeTemp "The temperature of the EGR gas entering the intake mixer, measured after the intake throttle when provided.";
CM_ SG_ 2566743806 EngExhstVlvActationSystemOilTemp "The temperature of the oil in the hydraulic system that powers the engine exhaust valve actuation system";
CM_ SG_ 2566743806 EngCoolantThermostatOpening "The current position of the Thermostat used to regulate the temperature of the engine coolant.  0% represents the thermostat allows flow to completely bypass the radiator and 100% represents the flow is fully through the radiator.";
CM_ SG_ 2566743806 EngCoolantPumpOutletTemp "The actual value of engine coolant temperature at the coolant pump outlet.  See also SPNs 110, 4076 and 6209 for additional coolant temperature parameters.";
CM_ SG_ 2566743806 EngCoolantTemp2 "Second temperature of liquid found in the engine cooling system.   See also SPNs 110, 4193 and 6209.";
CM_ BO_ 2499635454 "Gross Combination Vehicle Weight";
CM_ SG_ 2499635454 NetVehicleWeightChange "Identifies the net vehicle weight change from the time of last vehicle net weight zeroing.";
CM_ SG_ 2499635454 GrossCombinationWeight "Total weight of the truck and all the trailers with on-board scales.";
CM_ BO_ 2550660862 "The measured load sense pressure and pilot pressure of a valve.  May also include the load sense and supply pressure for a valve assembly, when available.";
CM_ SG_ 2550660862 ValveAssemblySupplyPress "Pressure of the hydraulic supply port to a valve assembly.";
CM_ SG_ 2550660862 ValveAssemblyLoadSensePress "The maximum pressure of a valve assembly's current collective load sense pressures where a valve assembly can consist of two or more valves.";
CM_ SG_ 2550660862 ValvePilotPress "Pressure of a valve's pilot supply port.";
CM_ SG_ 2550660862 ValveLoadSensePress "The maximum of the currently measured pressures of a valve's work port A and work port B.";
CM_ BO_ 2566805758 "Used for bellow pressure information";
CM_ SG_ 2566805758 BellowPressRearAxleRight "Information of the pressure of the air suspension bellow at the right side of the rear axle";
CM_ SG_ 2566805758 BellowPressRearAxleLeft "Information of the pressure of the air suspension bellow at the left side of the rear axle";
CM_ SG_ 2566805758 BellowPressFrontAxleRight "Information of the pressure of the air suspension bellow at the right side of the front axle";
CM_ SG_ 2566805758 BellowPressFrontAxleLeft "Information of the pressure of the air suspension bellow at the left side of the front axle";
CM_ BO_ 2566806014 "Used for height information";
CM_ SG_ 2566806014 RelativeLevelRearAxleRight "Information of the height at the left side of the rear axle referred to normal level 1.  For explanations of normal level 1 see parameter SPN 1734 - Nominal Level Front Axle.";
CM_ SG_ 2566806014 RelativeLevelRearAxleLeft "Information of the height at the left side of the rear axle referred to normal level 1.  For explanations of normal level 1 see parameter SPN 1734 - Nominal Level Front Axle.";
CM_ SG_ 2566806014 RelativeLevelFrontAxleRight "Information of the height at the right side of the front axle referred to normal level 1.  For explanations of normal level 1 see SPN 1734 - Nominal Level Front Axle.";
CM_ SG_ 2566806014 RelativeLevelFrontAxleLeft "Information of the height at the left side of the front axle referred to normal level 1.  For explanations of normal level 1 see SPN 1734 - Nominal Level Front Axle.";
CM_ BO_ 2362638078 "Used for suspension control";
CM_ SG_ 2362638078 MemoryLevelRq "Signal which indicates that the air suspension control requests a memory level or a memory level shall be stored.
The storage of  the current memory level is requested by  \"Store memory level x\". The acknowledge is set in \"memory level x stored\" ...";
CM_ SG_ 2362638078 PrhbitAutomaticAirSuspensionCtrl "This parameter is an internal request to the air suspension control system to prohibit automatic air suspension control.  If the request is accepted,  response intended to be sent in  ASC1 (additional status requested in ASC1), there will be no ...";
CM_ SG_ 2362638078 SpeedDependentLevelCtrlRq "This parameter activates speed dependent level control in suspension system.

00 = Deactivate
01 = Activate
10 = Reserved
11 = Don’t care/take no action";
CM_ SG_ 2362638078 AllowLevelCtrlDuringBrakingCmd "This parameter overides the inhibit of level control during braking.

00 = Disallow level control during braking (normal operation)
01 = Allow level control during braking
10 = Reserved
11 = Don’t' care/take no action";
CM_ SG_ 2362638078 ProhibitAirSuspensionCtrl "This parameter is an external request to the air suspension control system to prohibit all air suspension control.  If the request is accepted,  response intended to be sent in  ASC1 (additional status requested in ASC1), there will be no control ...";
CM_ SG_ 2362638078 KneelingCmdRearAxle "Command signal to activate the kneeling functionality at the rear axle of the vehicle.

00 Deactivate kneeling
01 Activate kneeling
10 Reserved
11 Don't care/take no action";
CM_ SG_ 2362638078 KneelingCmdFrontAxle "Command signal to activate the kneeling functionality at the front axle of the vehicle

00 Deactivate kneeling
01 Activate kneeling
10 Reserved
11 Don't care/take no action";
CM_ SG_ 2362638078 DamperStiffnessRqLift_TagAxle "Demand value for the shock absorber control at the lift or tag axle";
CM_ SG_ 2362638078 DamperStiffnessRqRearAxle "Demand value for the shock absorber control at the rear  axle.";
CM_ SG_ 2362638078 DamperStiffnessRqFrontAxle "Demand value for the shock absorber control at the front axle.";
CM_ SG_ 2362638078 LiftAxle2PosCmd "Signal to command the position / load condition of lift / tag axle #2.  Numbering of lift/tag axles starts at front axle.
00 Lift axle position down / tag axle laden
01 Lift axle position up / tag axle unladen
10 Reserved
11 Don't care/take no ...";
CM_ SG_ 2362638078 LiftAxle1PosCmd "Signal to command the position/load condition of lift/tag axle #1.  Numbering of lift/tag axles starts at front axle.
00 Lift axle position down / tag axle laden
01 Lift axle position up / tag axle unladen
10 Reserved
11 Don't care/take no ...";
CM_ SG_ 2362638078 LevelCtrlModeRq "Command signal to activate a level control mode
0000    Normal operation; i.e. the system performs a \"pure\" control of the vehicle height
0001    Traction help (load transfer); i.e. the driven axle is loaded to a maximum value given by legislation ...";
CM_ SG_ 2362638078 NominalLevelRqRearAxle "Command signal to activate a level of the rear axle programmed and/or memorized in the ECU.  For explanations of nominal level see SPN 1734 - Nominal Level Front Axle.
0000 No level request
0001 Normal Level 1,(i.e. the level prescribed for normal ...";
CM_ SG_ 2362638078 NominalLevelRqFrontAxle "Command signal to activate a level of the front axle programmed and/or memorized in the ECU   For explanations of nominal level see SPN 1734 - Nominal Level Front Axle.
0000 No level request
0001 Normal Level 1,(i.e. the level prescribed for ...";
CM_ SG_ 2362638078 KneelingCtrlModeRq "Command signal to select the kneeling functionality

00 Automatically actuated
01 Manually actuated
10 Reserved
11 Don't care/take no action";
CM_ SG_ 2362638078 KneelingRqRightSide "Command signal to activate the kneeling functionality on the right side of the vehicle

00 No kneeling request
01 Kneeling request
10 Reserved
11 Don't care/take no action";
CM_ SG_ 2362638078 KneelingRqLeftSide "Command signal to activate the kneeling functionality on the left side of the vehicle

00 No kneeling request
01 Kneeling request
10 Reserved
11 Don't care/take no action";
CM_ SG_ 2362638078 AutomaticTractionHelp "This signal enables the traction help (load transfer) in case of an active ASR function

00   Disable automatic traction help 
01   Enable automatic traction help 
10   Reserved
11   Don't care";
CM_ BO_ 2365479678 "Used for suspension control  information";
CM_ SG_ 2365479678 MemoryLevel "Signal which indicates that the air suspension control has memory levels selected or stored.
Response to memory level request in ASC2 (byte 8.5). If the request was executed the respective status will be set. If the request was not executed ...";
CM_ SG_ 2365479678 SuspensionCtrlRefusalInformation "Signal which indicates that the air suspension control cannot perform a request due to the operating conditions. It also provides a reason for the refusal.
0000 Actual request not refused
0001 Axle load limit reached  (load transfer)
0010 Would ...";
CM_ SG_ 2365479678 SpeedDependantLevelCtrlStatus "This parameter indicates if the function Speed Dependant Level Control is active. The function is activated by SPN 5295.

00 = Inactive
01 = Active
10 = Reserved
11 = Don’t' care/take no action";
CM_ SG_ 2365479678 AllwLevelCtrlDuringBrakingStatus "This parameter indicates if the function Allow Level Control During Braking is active. Functions is activated by SPN 5293.

00 = Deactivated
01 = Activated
10 = Reserved
11 = Don’t care/take no action";
CM_ SG_ 2365479678 SuspensionRemoteCtrl2 "Signal which indicates that the suspension system is controlled by remote control #2. Remote control is an external unit to operate the suspension system.

00 Not active
01 Active
10 Error
11 Not available";
CM_ SG_ 2365479678 SuspensionRemoteCtrl1 "Signal which indicates that the suspension system is controlled by remote control #1. Remote control is an external unit to operate the suspension system.

00 Not active
01 Active
10 Error
11 Not available";
CM_ SG_ 2365479678 LiftAxle2Pos "Signal which indicates the position / load condition of lift axle / tag axle #2.   Numbering of lift/tag axles starts at front axle.
00 Lift axle position down / tag axle laden
01 Lift axle position up / tag axle unladen
10 Error
11 Not ...";
CM_ SG_ 2365479678 RearAxleInBumperRange "Signal which indicates that the vehicle height at the rear axle (SPNs 1723 and 1724) is within the bumper range.

00 Actual level out of bumper range
01 Actual level within bumper range
10 Error
11 Not available";
CM_ SG_ 2365479678 FrontAxleInBumperRange "Signal which indicates that the vehicle height at the front axle (SPNs 1721 and 1722) is within the bumper range.

00 Actual level out of bumper range
01 Actual level within bumper range
10 Error
11 Not available";
CM_ SG_ 2365479678 LiftAxle1Pos "Signal which indicates the position / load condition of lift axle / tag axle #1.   Numbering of lift/tag axles starts at front axle.
00 Lift axle position down / tag axle laden
01 Lift axle position up / tag axle unladen
10 Error
11 Not ...";
CM_ SG_ 2365479678 DoorRelease "Signal which indicates that the doors may be opened. [Please note: doors instead of door!]
In case a kneeling request is active the ASC indicates during lowering the vehicle \"doors shall not be opened\" as a security information until the kneeling ...";
CM_ SG_ 2365479678 VehicleMotionInhibit "Signal which indicates whether vehicle motion is inhibited.

00 Vehicle may be moved
01 Vehicle motion is inhibited
10 Error
11 Not available";
CM_ SG_ 2365479678 SecurityDevice "The signal which indicates the status of the security device.  An example of a security device is a curbstone feeler installed beneath the doors of a bus. If the security device becomes active during kneeling the kneeling process (lowering) is ...";
CM_ SG_ 2365479678 LevelCtrlMode "Signal which indicates the actual control mode of the air suspension system
0000    Normal operation; i.e. the system performs a \"pure\" control of the vehicle height
0001    Traction help (load transfer); i.e. the driven axle is loaded to a ...";
CM_ SG_ 2365479678 KneelingInformation "Signal which indicates the actual level change in case of kneeling function
0000 Not active,(i.e. the kneeling function is not active\")
0001Lowering active,(i.e. the vehicle is lowered due to a kneeling request)
0010 Kneeling level reached,(i.e ...";
CM_ SG_ 2365479678 LiftingCtrlModeRearAxle "Signal which indicates the actual lifting level change at the rear axle

00 Lifting not active
01 Lifting active
10 Error
11 Not available";
CM_ SG_ 2365479678 LiftingCtrlModeFrontAxle "Signal which indicates the actual lifting level change at the front axle

00 Lifting not active
01 Lifting active
10 Error
11 Not available";
CM_ SG_ 2365479678 LoweringCtrlModeRearAxle "Signal which indicates the actual lowering level change at the rear axle

00 Lowering not active
01 Lowering active
10 Error
11 Not available";
CM_ SG_ 2365479678 LoweringCtrlModeFrontAxle "Signal which indicates the actual lowering level change at the front axle

00 Lowering not active
01 Lowering active
10 Error
11 Not available";
CM_ SG_ 2365479678 AboveNominalLevelRearAxle "Signal which indicates whether the actual height of the rear axle is above the nominal (desired) level of the rear axle. For explanations of nominal level see parameter SPN 1734 - Nominal Level Front Axle.
00 Not above
01 Above
10 Error
11 Not ...";
CM_ SG_ 2365479678 AboveNominalLevelFrontAxle "Signal which indicates whether the actual height of the front axle is above the nominal (desired) level of the front axle. For explanations of nominal level see SPN 1734 - Nominal Level Front Axle.
00 Not above
01 Above
10 Error
11 Not available
 ...";
CM_ SG_ 2365479678 BelowNominalLevelRearAxle "Signal which indicates whether the actual height of the rear axle is below the nominal (desired) level for the rear axle. For explanations of nominal level see SPN 1734 - Nominal Level Front Axle.
00 Not below
01 Below
10 Error
11 Not available
 ...";
CM_ SG_ 2365479678 BelowNominalLevelFrontAxle "Signal which indicates whether the actual height of the front axle is below the nominal (desired) level for the front axle. For explanations of nominal level see parameter SPN 1734 - Nominal Level Front Axle.
00 Not below
01 Below
10 Error
11 ...";
CM_ SG_ 2365479678 NominalLevelRearAxle "Signal which indicates the nominal (desired) height of the rear axle to be controlled by the suspension system.
For further explanations see SPN 1734 - Nominal Level Front Axle.
0000 Level not specified,(i.e. the nominal level is none of the ...";
CM_ SG_ 2365479678 NominalLevelFrontAxle "Signal which indicates the nominal (desired) height of the front axle to be controlled by the suspension system.
These heights are discrete levels.  They are the upper level, lower level, normal level 1, normal level 2, normal level 3, customer ...";
CM_ SG_ 2566837758 Alt4Status "Alternator 4 operating status.

00 Alternator 4 not charging
01 Alternator 4 charging
10 error
11 not available";
CM_ SG_ 2566837758 Alt3Status "Alternator 3 operating status.

00 Alternator 3 not charging
01 Alternator 3 charging
10 error
11 not available";
CM_ SG_ 2566837758 Alt2Status "Alternator 2 operating status.

00 Alternator 2 not charging
01 Alternator 2 charging
10 error
11 not available";
CM_ SG_ 2566837758 Alt1Status "Alternator 1 operating status.

00 Alternator 1 not charging
01 Alternator 1 charging
10 error
11 not available";
CM_ SG_ 2566837758 AltSpeed "Actual rotation speed of the alternator.";
CM_ SG_ 2633922558 AuxAbsPressReading "Identifies the current absolute pressure (relative to 0 pressure) that is configured uniquely per application.  Not to be used in place of defined parameters.";
CM_ SG_ 2633922558 AuxGagePressReading1 "Identifies the current gage pressure (relative to atmosphere) that is configured uniquely per application.  Not to be used in place of defined parameters.";
CM_ SG_ 2633922558 AuxVacuumPressReading "Identifies the current vacuum pressure (relative to atmosphere) that is configured uniquely per application.  Not to be used in place of defined parameters.";
CM_ BO_ 2566775038 "This message contains measurement and configuration information about the vehicle ambient conditions.";
CM_ SG_ 2566775038 BarometricAbsPressHighResolution "Barometric Absolute Pressure (High Resolution).  See SPN 108 if high resolution is not needed.";
CM_ SG_ 2566775038 CalculatedAmbientAirTemp "Calculated temperature of air surrounding vehicle.  Use SPN 171 for actual measured ambient air temperature.";
CM_ SG_ 2566775038 SpecificHumidity "Specific humidity of the ambient intake air.";
CM_ SG_ 2566775038 SolarSensorMax "This is the maximum value which can be reported by the sensor for the solar intensity. (This is a configuration parameter)";
CM_ SG_ 2566775038 SolarIntensityPercent "This is the solar radiation (power density) falling on the vehicle in percent of the maximum sensor value (SPN 2611).  Currently this is in the infra-red spectrum.";
CM_ BO_ 2365509886 "The purpose of this response PG is to report the test results for one of the non-continuously monitored tests invoked using DM7";
CM_ SG_ 2365509886 TestLimitMinimum "The test value must be greater than or equal to Test Limit Minimum in order for the test to pass.";
CM_ SG_ 2365509886 TestLimitMaximum "The test value must be less than or equal to Test Limit Maximum in order for the test to pass.";
CM_ SG_ 2365509886 TestValue "The test value collected during the test.";
CM_ SG_ 2365509886 TestType "This parameter identifies the non-continuously monitored component identifier that was tested.";
CM_ SG_ 2365509886 TestIdentifier "The TID designates the test to be run.";
CM_ BO_ 2363752190 "The purpose of this command in the diagnostic process is to provide the ability to command On-Board Diagnostic monitoring tests of specific components/ systems that are not continuously monitored";
CM_ SG_ 2363752190 SPN1High "SPN #1 (Conversion Version 4)";
CM_ SG_ 2363752190 SPN1 "This parameter identifies the component / system that will be tested.";
CM_ SG_ 2363752190 TestIdentifier "The TID designates the test to be run.";
CM_ SG_ 2363752190 FailureModeIdentifier1 "This parameter identifies the failure mode identifier which represents the test(s) that shall be run on the component / system that will be tested.";
CM_ BO_ 2566836222 "The purpose of this DM is to enable the external test equipment to obtain “pending” diagnostic trouble codes detected during current or last completed driving cycle for emission-related components/systems.";
CM_ SG_ 2566836222 FlashRedStopLamp "This parameter provides the capability to flash the RSL";
CM_ SG_ 2566836222 FlashProtectLamp "This parameter provides the capability to flash the engine protect lamp";
CM_ SG_ 2566836222 FlashMalfuncIndicatorLamp "This parameter provides the capability to flash the MIL";
CM_ SG_ 2566836222 FlashAmberWarningLamp "This parameter provides the capability to flash the AWL";
CM_ SG_ 2566836222 MalfunctionIndicatorLampStatus "A lamp used to relay only emissions-related trouble code information. This lamp is only illuminated when there is an emission-related trouble code active.";
CM_ SG_ 2566836222 RedStopLampState "This lamp is used to relay trouble code information that is of a severe enough condition that it warrants stopping the vehicle.";
CM_ SG_ 2566836222 AmberWarningLampStatus "This lamp is used to relay trouble code information that is reporting a problem with the vehicle system but the vehicle need not be immediately stopped.";
CM_ SG_ 2566836222 ProtectLampStatus "This lamp is used to relay trouble code information that is reporting a problem with a vehicle system that is most probably not electronic subsystem related. For instance, engine coolant temperature is exceeding its prescribed temperature range.";
CM_ SG_ 2566836222 DTC5 "Diagnostic Trouble Code";
CM_ SG_ 2566836222 DTC4 "Diagnostic Trouble Code";
CM_ SG_ 2566836222 DTC3 "Diagnostic Trouble Code";
CM_ SG_ 2566836222 DTC2 "Diagnostic Trouble Code";
CM_ SG_ 2566836222 DTC1 "Diagnostic Trouble Code";
CM_ BO_ 2365509374 "Reports the diagnostics information that relates to diagnostic readiness.";
CM_ SG_ 2365509374 OBDCompliance "Identifies the OBD compliance capability of the responding controller. Identifies the requirements level to which the controller was built.";
CM_ SG_ 2365509374 PreviouslyActiveTroubleCodes "Identifies the number of previously active trouble codes that are present in a specific controller. If no DTCs have been previously active, this field should be set to zero.";
CM_ SG_ 2365509374 ActiveTroubleCodes "Identifies the number of active trouble codes that are present in a specific controller. If no DTCs are active, this field should be set to zero.";
BA_DEF_ SG_  "SigType" ENUM  "Default","Range","RangeSigned","ASCII","Discrete","Control","ReferencePGN","DTC","StringDelimiter","StringLength","StringLengthControl","MessageCounter","MessageChecksum";
BA_DEF_ SG_  "GenSigStartValue" INT 0 10000;
BA_DEF_ SG_  "GenSigSendType" ENUM  "Cyclic","OnWrite","OnWriteWithRepetition","OnChange","OnChangeWithRepetition","IfActive","IfActiveWithRepetition","NoSigSendType";
BA_DEF_ SG_  "GenSigILSupport" ENUM  "No","Yes";
BA_DEF_ SG_  "GenSigEVName" STRING ;
BA_DEF_ SG_  "SPN" INT 0 524287;
BA_DEF_ BO_  "GenMsgStartDelayTime" INT 0 100000;
BA_DEF_ BO_  "GenMsgILSupport" ENUM  "No","Yes";
BA_DEF_ BO_  "GenMsgRequestable" INT 0 1;
BA_DEF_ BO_  "GenMsgSendType" ENUM  "cyclic","NotUsed","NotUsed","NotUsed","NotUsed","NotUsed","NotUsed","IfActive","noMsgSendType";
BA_DEF_ BO_  "VFrameFormat" ENUM  "StandardCAN","ExtendedCAN","reserved","J1939PG";
BA_DEF_ BO_  "GenMsgCycleTime" INT 0 3600000;
BA_DEF_ SG_  "SystemSignalLongSymbol" STRING ;
BA_DEF_DEF_  "SigType" "Default";
BA_DEF_DEF_  "GenSigStartValue" 0;
BA_DEF_DEF_  "GenSigSendType" "NoSigSendType";
BA_DEF_DEF_  "GenSigILSupport" "Yes";
BA_DEF_DEF_  "GenSigEVName" "Env@Nodename_@Signame";
BA_DEF_DEF_  "SPN" 0;
BA_DEF_DEF_  "GenMsgStartDelayTime" 0;
BA_DEF_DEF_  "GenMsgILSupport" "Yes";
BA_DEF_DEF_  "GenMsgRequestable" 1;
BA_DEF_DEF_  "GenMsgSendType" "noMsgSendType";
BA_DEF_DEF_  "VFrameFormat" "J1939PG";
BA_DEF_DEF_  "GenMsgCycleTime" 0;
BA_DEF_DEF_  "SystemSignalLongSymbol" "";
BA_ "GenMsgSendType" BO_ 2566847230 0;
BA_ "GenMsgCycleTime" BO_ 2566847230 1000;
BA_ "GenMsgSendType" BO_ 2566848254 0;
BA_ "GenMsgCycleTime" BO_ 2566848254 1000;
BA_ "GenMsgSendType" BO_ 2566725886 0;
BA_ "GenMsgCycleTime" BO_ 2566725886 500;
BA_ "GenMsgSendType" BO_ 2432520958 0;
BA_ "GenMsgCycleTime" BO_ 2432520958 1000;
BA_ "GenMsgSendType" BO_ 2560425726 0;
BA_ "GenMsgCycleTime" BO_ 2560425726 100;
BA_ "GenMsgSendType" BO_ 2560491262 0;
BA_ "GenMsgCycleTime" BO_ 2560491262 100;
BA_ "GenMsgSendType" BO_ 2349399806 0;
BA_ "GenMsgCycleTime" BO_ 2349399806 20;
BA_ "GenMsgSendType" BO_ 2566758398 0;
BA_ "GenMsgCycleTime" BO_ 2566758398 500;
BA_ "GenMsgSendType" BO_ 2566745598 0;
BA_ "GenMsgCycleTime" BO_ 2566745598 500;
BA_ "GenMsgSendType" BO_ 2566758910 0;
BA_ "GenMsgCycleTime" BO_ 2566758910 500;
BA_ "GenMsgSendType" BO_ 2566743550 0;
BA_ "GenMsgCycleTime" BO_ 2566743550 500;
BA_ "GenMsgSendType" BO_ 2566753534 0;
BA_ "GenMsgCycleTime" BO_ 2566753534 500;
BA_ "GenMsgSendType" BO_ 2565869310 0;
BA_ "GenMsgCycleTime" BO_ 2565869310 50;
BA_ "GenMsgSendType" BO_ 2566763774 0;
BA_ "GenMsgCycleTime" BO_ 2566763774 500;
BA_ "GenMsgSendType" BO_ 2633934846 0;
BA_ "GenMsgCycleTime" BO_ 2633934846 1000;
BA_ "GenMsgSendType" BO_ 2362572542 2;
BA_ "GenMsgCycleTime" BO_ 2362572542 100;
BA_ "GenMsgSendType" BO_ 2365478910 0;
BA_ "GenMsgCycleTime" BO_ 2365478910 100;
BA_ "GenMsgSendType" BO_ 2566763262 0;
BA_ "GenMsgCycleTime" BO_ 2566763262 500;
BA_ "GenMsgSendType" BO_ 2565869566 0;
BA_ "GenMsgCycleTime" BO_ 2565869566 50;
BA_ "GenMsgSendType" BO_ 2566763518 0;
BA_ "GenMsgCycleTime" BO_ 2566763518 500;
BA_ "GenMsgSendType" BO_ 2566758142 0;
BA_ "GenMsgCycleTime" BO_ 2566758142 500;
BA_ "GenMsgSendType" BO_ 2566745342 0;
BA_ "GenMsgCycleTime" BO_ 2566745342 500;
BA_ "GenMsgSendType" BO_ 2566758654 0;
BA_ "GenMsgCycleTime" BO_ 2566758654 500;
BA_ "GenMsgSendType" BO_ 2566753278 0;
BA_ "GenMsgCycleTime" BO_ 2566753278 500;
BA_ "GenMsgSendType" BO_ 2565869822 0;
BA_ "GenMsgCycleTime" BO_ 2565869822 50;
BA_ "GenMsgSendType" BO_ 2566763006 0;
BA_ "GenMsgCycleTime" BO_ 2566763006 500;
BA_ "GenMsgSendType" BO_ 2566762494 0;
BA_ "GenMsgCycleTime" BO_ 2566762494 500;
BA_ "GenMsgSendType" BO_ 2565870078 0;
BA_ "GenMsgCycleTime" BO_ 2565870078 50;
BA_ "GenMsgSendType" BO_ 2566762750 0;
BA_ "GenMsgCycleTime" BO_ 2566762750 500;
BA_ "GenMsgSendType" BO_ 2365428478 0;
BA_ "GenMsgCycleTime" BO_ 2365428478 250;
BA_ "GenMsgSendType" BO_ 2566743806 0;
BA_ "GenMsgCycleTime" BO_ 2566743806 1000;
BA_ "GenMsgSendType" BO_ 2550660862 0;
BA_ "GenMsgCycleTime" BO_ 2550660862 100;
BA_ "GenMsgSendType" BO_ 2566805758 0;
BA_ "GenMsgCycleTime" BO_ 2566805758 100;
BA_ "GenMsgSendType" BO_ 2566806014 0;
BA_ "GenMsgCycleTime" BO_ 2566806014 100;
BA_ "GenMsgSendType" BO_ 2362638078 0;
BA_ "GenMsgCycleTime" BO_ 2362638078 100;
BA_ "GenMsgSendType" BO_ 2365479678 0;
BA_ "GenMsgCycleTime" BO_ 2365479678 100;
BA_ "GenMsgSendType" BO_ 2566837758 0;
BA_ "GenMsgCycleTime" BO_ 2566837758 1000;
BA_ "GenMsgSendType" BO_ 2566775038 0;
BA_ "GenMsgCycleTime" BO_ 2566775038 1000;
BA_ "SigType" SG_ 2566847230 ParkingBrakeRedWarningSignal 5;
BA_ "SPN" SG_ 2566847230 ParkingBrakeRedWarningSignal 3557;
BA_ "SigType" SG_ 2566847230 ParkBrakeReleaseInhibitStatus 4;
BA_ "SPN" SG_ 2566847230 ParkBrakeReleaseInhibitStatus 3808;
BA_ "SigType" SG_ 2566847230 ParkingBrakeActuator 4;
BA_ "SPN" SG_ 2566847230 ParkingBrakeActuator 619;
BA_ "SigType" SG_ 2566847230 BrakeSecondPress 1;
BA_ "SPN" SG_ 2566847230 BrakeSecondPress 118;
BA_ "SigType" SG_ 2566847230 BrakePrimaryPress 1;
BA_ "SPN" SG_ 2566847230 BrakePrimaryPress 117;
BA_ "SigType" SG_ 2566847230 BrakeAppPress 1;
BA_ "SPN" SG_ 2566847230 BrakeAppPress 116;
BA_ "SigType" SG_ 2566848254 AuxPumpPress 1;
BA_ "SPN" SG_ 2566848254 AuxPumpPress 73;
BA_ "SPN" SG_ 2566725886 Aftrtrtmnt1DslOxdtnCtlystDff4770 4770;
BA_ "SPN" SG_ 2566725886 Aftrtrtmnt1DslOxdtnCtlystOtl4769 4769;
BA_ "SPN" SG_ 2566725886 Aftrtrtmnt1DslOxdtnCtlystInt4768 4768;
BA_ "SigType" SG_ 2566725886 Aftrtrtmnt1DslOxdtnCtlystDffPrss 1;
BA_ "SPN" SG_ 2566725886 Aftrtrtmnt1DslOxdtnCtlystDffPrss 4767;
BA_ "SigType" SG_ 2566725886 Aftrtrtmnt1DslOxdtnCtlystOtltGsT 1;
BA_ "SPN" SG_ 2566725886 Aftrtrtmnt1DslOxdtnCtlystOtltGsT 4766;
BA_ "SigType" SG_ 2566725886 Aftrtrtmnt1DslOxdtnCtlystIntkGsT 1;
BA_ "SPN" SG_ 2566725886 Aftrtrtmnt1DslOxdtnCtlystIntkGsT 4765;
BA_ "SigType" SG_ 2359557886 DTCWarnLampSupportStatus 4;
BA_ "SPN" SG_ 2359557886 DTCWarnLampSupportStatus 4115;
BA_ "SigType" SG_ 2359557886 DTCWarnLampSupportFlash 4;
BA_ "SPN" SG_ 2359557886 DTCWarnLampSupportFlash 4119;
BA_ "SigType" SG_ 2359557886 DTCStopLampSupportStatus 4;
BA_ "SPN" SG_ 2359557886 DTCStopLampSupportStatus 4114;
BA_ "SigType" SG_ 2359557886 DTCStopLampSupportFlash 4;
BA_ "SPN" SG_ 2359557886 DTCStopLampSupportFlash 4118;
BA_ "SigType" SG_ 2359557886 DTCProtectLampSupportStatus 4;
BA_ "SPN" SG_ 2359557886 DTCProtectLampSupportStatus 4116;
BA_ "SigType" SG_ 2359557886 DTCProtectLampSupportFlash 4;
BA_ "SPN" SG_ 2359557886 DTCProtectLampSupportFlash 4120;
BA_ "SPN" SG_ 2359557886 DTCMilSupportStatus 4113;
BA_ "SPN" SG_ 2359557886 DTCMilSupportFlash 4117;
BA_ "SigType" SG_ 2359557886 DTC1 7;
BA_ "SigType" SG_ 2633844734 TransModeLabel8 8;
BA_ "SigType" SG_ 2633844734 TransModeLabel7 8;
BA_ "SigType" SG_ 2633844734 TransModeLabel6 8;
BA_ "SigType" SG_ 2633844734 TransModeLabel5 8;
BA_ "SigType" SG_ 2633844734 TransModeLabel4 8;
BA_ "SigType" SG_ 2633844734 TransModeLabel3 8;
BA_ "SigType" SG_ 2633844734 TransModeLabel2 8;
BA_ "SigType" SG_ 2633844734 TransModeLabel 8;
BA_ "SPN" SG_ 2633844734 TransModeLabel 4254;
BA_ "SPN" SG_ 2560360190 DataDictionaryMethod 4181;
BA_ "SPN" SG_ 2560360190 DataDictionaryManufacturerCode 4180;
BA_ "SPN" SG_ 2566736126 EngExhstGsOxygnSnsrClsdLpOprtnBn 4241;
BA_ "SigType" SG_ 2566736126 ShorttermFuelTrimBank2 1;
BA_ "SPN" SG_ 2566736126 ShorttermFuelTrimBank2 4238;
BA_ "SigType" SG_ 2566736126 LongtermFuelTrimBank2 1;
BA_ "SPN" SG_ 2566736126 LongtermFuelTrimBank2 4239;
BA_ "SPN" SG_ 2566736382 EngExhstGsOxygnSnsrClsdLpOprtnBn 4240;
BA_ "SigType" SG_ 2566736382 ShorttermFuelTrimBank1 1;
BA_ "SPN" SG_ 2566736382 ShorttermFuelTrimBank1 4236;
BA_ "SigType" SG_ 2566736382 LongtermFuelTrimBank1 1;
BA_ "SPN" SG_ 2566736382 LongtermFuelTrimBank1 4237;
BA_ "SigType" SG_ 2565874174 EngSpdSensor1TimingPatternStatus 5;
BA_ "SPN" SG_ 2565874174 EngSpdSensor1TimingPatternStatus 4203;
BA_ "SigType" SG_ 2565874174 EngSpdSensor2TimingPatternStatus 5;
BA_ "SPN" SG_ 2565874174 EngSpdSensor2TimingPatternStatus 4204;
BA_ "SigType" SG_ 2565874174 EngSpdSensor3TimingPatternStatus 5;
BA_ "SPN" SG_ 2565874174 EngSpdSensor3TimingPatternStatus 4205;
BA_ "SigType" SG_ 2565874174 EngSpeed3 1;
BA_ "SPN" SG_ 2565874174 EngSpeed3 4202;
BA_ "SigType" SG_ 2565874174 EngSpeed2 1;
BA_ "SPN" SG_ 2565874174 EngSpeed2 723;
BA_ "SigType" SG_ 2565874174 EngSpeed1 1;
BA_ "SPN" SG_ 2565874174 EngSpeed1 4201;
BA_ "SigType" SG_ 2432520958 EngAxClerSupplyValve2ActuatorCmd 1;
BA_ "SPN" SG_ 2432520958 EngAxClerSupplyValve2ActuatorCmd 5547;
BA_ "SigType" SG_ 2432520958 EngAxClerSupplyValve1ActuatorCmd 1;
BA_ "SPN" SG_ 2432520958 EngAxClerSupplyValve1ActuatorCmd 5546;
BA_ "SigType" SG_ 2432520958 DsredEngCoolantThermostatOpening 1;
BA_ "SPN" SG_ 2432520958 DsredEngCoolantThermostatOpening 4197;
BA_ "SigType" SG_ 2432520958 DesiredEngCoolantPumpOutletTemp 1;
BA_ "SPN" SG_ 2432520958 DesiredEngCoolantPumpOutletTemp 4196;
BA_ "SigType" SG_ 2432520958 EngCoolantThermostatMode 5;
BA_ "SPN" SG_ 2432520958 EngCoolantThermostatMode 4195;
BA_ "SigType" SG_ 2560425726 AuxI_OChannel19 1;
BA_ "SPN" SG_ 2560425726 AuxI_OChannel19 4174;
BA_ "SigType" SG_ 2560425726 AuxI_OChannel20 1;
BA_ "SPN" SG_ 2560425726 AuxI_OChannel20 4173;
BA_ "SigType" SG_ 2560425726 AuxI_OChannel21 1;
BA_ "SPN" SG_ 2560425726 AuxI_OChannel21 4172;
BA_ "SigType" SG_ 2560425726 AuxI_OChannel22 1;
BA_ "SPN" SG_ 2560425726 AuxI_OChannel22 4171;
BA_ "SigType" SG_ 2560425726 AuxI_OChannel15 1;
BA_ "SPN" SG_ 2560425726 AuxI_OChannel15 4170;
BA_ "SigType" SG_ 2560425726 AuxI_OChannel16 1;
BA_ "SPN" SG_ 2560425726 AuxI_OChannel16 4169;
BA_ "SigType" SG_ 2560425726 AuxI_OChannel17 1;
BA_ "SPN" SG_ 2560425726 AuxI_OChannel17 4168;
BA_ "SigType" SG_ 2560425726 AuxI_OChannel18 1;
BA_ "SPN" SG_ 2560425726 AuxI_OChannel18 4167;
BA_ "SigType" SG_ 2560491262 AuxI_OChannel11 1;
BA_ "SPN" SG_ 2560491262 AuxI_OChannel11 4166;
BA_ "SigType" SG_ 2560491262 AuxI_OChannel12 1;
BA_ "SPN" SG_ 2560491262 AuxI_OChannel12 4165;
BA_ "SigType" SG_ 2560491262 AuxI_OChannel13 1;
BA_ "SPN" SG_ 2560491262 AuxI_OChannel13 4164;
BA_ "SigType" SG_ 2560491262 AuxI_OChannel14 1;
BA_ "SPN" SG_ 2560491262 AuxI_OChannel14 4163;
BA_ "SigType" SG_ 2560491262 AuxI_OChannel7 1;
BA_ "SPN" SG_ 2560491262 AuxI_OChannel7 4162;
BA_ "SigType" SG_ 2560491262 AuxI_OChannel8 1;
BA_ "SPN" SG_ 2560491262 AuxI_OChannel8 4161;
BA_ "SigType" SG_ 2560491262 AuxI_OChannel9 1;
BA_ "SPN" SG_ 2560491262 AuxI_OChannel9 4160;
BA_ "SigType" SG_ 2560491262 AuxI_OChannel10 1;
BA_ "SPN" SG_ 2560491262 AuxI_OChannel10 4159;
BA_ "SigType" SG_ 2349399806 AuxI_OChannel3 1;
BA_ "SPN" SG_ 2349399806 AuxI_OChannel3 4158;
BA_ "SigType" SG_ 2349399806 AuxI_OChannel4 1;
BA_ "SPN" SG_ 2349399806 AuxI_OChannel4 4157;
BA_ "SigType" SG_ 2349399806 AuxI_OChannel5 1;
BA_ "SPN" SG_ 2349399806 AuxI_OChannel5 4156;
BA_ "SigType" SG_ 2349399806 AuxI_OChannel6 1;
BA_ "SPN" SG_ 2349399806 AuxI_OChannel6 4155;
BA_ "SigType" SG_ 2566758398 Aftertreatment1AirEnableActuator 5;
BA_ "SPN" SG_ 2566758398 Aftertreatment1AirEnableActuator 3489;
BA_ "SigType" SG_ 2566758398 Aftertreatment1PurgeAirActuator 5;
BA_ "SPN" SG_ 2566758398 Aftertreatment1PurgeAirActuator 3490;
BA_ "SigType" SG_ 2566758398 Aftrtrtmnt1AtmizationAirActuator 5;
BA_ "SPN" SG_ 2566758398 Aftrtrtmnt1AtmizationAirActuator 3491;
BA_ "SigType" SG_ 2566758398 Aftertreatment1AirSystemRelay 5;
BA_ "SPN" SG_ 2566758398 Aftertreatment1AirSystemRelay 3492;
BA_ "SigType" SG_ 2566758398 Aftrtratment1AirPressActuatorPos 1;
BA_ "SPN" SG_ 2566758398 Aftrtratment1AirPressActuatorPos 3488;
BA_ "SigType" SG_ 2566758398 Aftertreatment1AirPressCtrl 1;
BA_ "SPN" SG_ 2566758398 Aftertreatment1AirPressCtrl 3487;
BA_ "SigType" SG_ 2566758398 Aftertreatment1PurgeAirPress 1;
BA_ "SPN" SG_ 2566758398 Aftertreatment1PurgeAirPress 3486;
BA_ "SigType" SG_ 2566758398 Aftertreatment1SupplyAirPress 1;
BA_ "SPN" SG_ 2566758398 Aftertreatment1SupplyAirPress 3485;
BA_ "SigType" SG_ 2566745598 Aftertreatment1SecondAirPress 1;
BA_ "SPN" SG_ 2566745598 Aftertreatment1SecondAirPress 3837;
BA_ "SigType" SG_ 2566745598 Aftertreatment1SecondAirMassFlow 1;
BA_ "SPN" SG_ 2566745598 Aftertreatment1SecondAirMassFlow 3832;
BA_ "SigType" SG_ 2566745598 Aftertreatment1SecondAirTemp 1;
BA_ "SPN" SG_ 2566745598 Aftertreatment1SecondAirTemp 3831;
BA_ "SigType" SG_ 2566745598 Aftrtreatment1SecondAirDiffPress 1;
BA_ "SPN" SG_ 2566745598 Aftrtreatment1SecondAirDiffPress 3830;
BA_ "SigType" SG_ 2566758910 Aftrtrtmnt1FlInjector1HeaterCtrl 1;
BA_ "SPN" SG_ 2566758910 Aftrtrtmnt1FlInjector1HeaterCtrl 4301;
BA_ "SigType" SG_ 2566758910 Aftrtreatment1FuelEnableActuator 5;
BA_ "SPN" SG_ 2566758910 Aftrtreatment1FuelEnableActuator 3482;
BA_ "SigType" SG_ 2566758910 Aftrtreatment1RegenerationStatus 5;
BA_ "SPN" SG_ 2566758910 Aftrtreatment1RegenerationStatus 3483;
BA_ "SigType" SG_ 2566758910 Aftertreatment1Ignt 5;
BA_ "SPN" SG_ 2566758910 Aftertreatment1Ignt 3484;
BA_ "SigType" SG_ 2566758910 Aftertreatment1FuelDrainActuator 5;
BA_ "SPN" SG_ 2566758910 Aftertreatment1FuelDrainActuator 4097;
BA_ "SigType" SG_ 2566758910 Aftertreatment1FuelPress1Ctrl 1;
BA_ "SPN" SG_ 2566758910 Aftertreatment1FuelPress1Ctrl 3479;
BA_ "SigType" SG_ 2566758910 Aftertreatment1FuelRate 1;
BA_ "SPN" SG_ 2566758910 Aftertreatment1FuelRate 3481;
BA_ "SigType" SG_ 2566758910 Aftertreatment1FuelPress1 1;
BA_ "SPN" SG_ 2566758910 Aftertreatment1FuelPress1 3480;
BA_ "SigType" SG_ 2566743550 Aftrtrtmnt1HydrcrbnDsrIntkFlTemp 1;
BA_ "SPN" SG_ 2566743550 Aftrtrtmnt1HydrcrbnDsrIntkFlTemp 5456;
BA_ "SigType" SG_ 2566743550 Aftrtrtmnt1FelPress2ActuatorCtrl 1;
BA_ "SPN" SG_ 2566743550 Aftrtrtmnt1FelPress2ActuatorCtrl 5425;
BA_ "SigType" SG_ 2566743550 Aftrtrtmnt1FlFlwDverterValveCtrl 5;
BA_ "SPN" SG_ 2566743550 Aftrtrtmnt1FlFlwDverterValveCtrl 5424;
BA_ "SigType" SG_ 2566743550 Aftertreatment1FuelPumpRelayCtrl 5;
BA_ "SPN" SG_ 2566743550 Aftertreatment1FuelPumpRelayCtrl 5423;
BA_ "SigType" SG_ 2566743550 Aftertreatment1FuelPress2 1;
BA_ "SPN" SG_ 2566743550 Aftertreatment1FuelPress2 4077;
BA_ "SigType" SG_ 2566753534 DslParticulateFilterOutletPress1 1;
BA_ "SPN" SG_ 2566753534 DslParticulateFilterOutletPress1 3610;
BA_ "SigType" SG_ 2566753534 DslParticulateFilterIntakePress1 1;
BA_ "SPN" SG_ 2566753534 DslParticulateFilterIntakePress1 3609;
BA_ "SigType" SG_ 2566756606 Aftrtrtmnt1AvrgDstncBtwnActvDPFR 1;
BA_ "SPN" SG_ 2566756606 Aftrtrtmnt1AvrgDstncBtwnActvDPFR 5827;
BA_ "SigType" SG_ 2566756606 Aftrtrtmnt1AvrgTmBtwnActvRgnrtns 1;
BA_ "SPN" SG_ 2566756606 Aftrtrtmnt1AvrgTmBtwnActvRgnrtns 5454;
BA_ "SigType" SG_ 2566756606 Aftrtrtmnt1DslPrtcltFltrTtlN3728 1;
BA_ "SPN" SG_ 2566756606 Aftrtrtmnt1DslPrtcltFltrTtlN3728 3728;
BA_ "SigType" SG_ 2566756606 Aftrtrtmnt1DslPrtcltFltrTtlN3727 1;
BA_ "SPN" SG_ 2566756606 Aftrtrtmnt1DslPrtcltFltrTtlN3727 3727;
BA_ "SigType" SG_ 2566756606 Aftrtrtmnt1DslPrtcltFltrTtlNmbrO 1;
BA_ "SPN" SG_ 2566756606 Aftrtrtmnt1DslPrtcltFltrTtlNmbrO 3726;
BA_ "SigType" SG_ 2566756606 Aftrtrtmnt1DslPrtcltFltrTtlPssvR 1;
BA_ "SPN" SG_ 2566756606 Aftrtrtmnt1DslPrtcltFltrTtlPssvR 3725;
BA_ "SigType" SG_ 2566756606 Aftrtrtmnt1TtlNmbrOfActvRgnrtons 1;
BA_ "SPN" SG_ 2566756606 Aftrtrtmnt1TtlNmbrOfActvRgnrtons 3525;
BA_ "SigType" SG_ 2566756606 Aftertreatment1TotalDisabledTime 1;
BA_ "SPN" SG_ 2566756606 Aftertreatment1TotalDisabledTime 3524;
BA_ "SigType" SG_ 2566756606 Aftrtrtmnt1TotalRegenerationTime 1;
BA_ "SPN" SG_ 2566756606 Aftrtrtmnt1TotalRegenerationTime 3523;
BA_ "SigType" SG_ 2566756606 Aftertreatment1TotalFuelUsed 1;
BA_ "SPN" SG_ 2566756606 Aftertreatment1TotalFuelUsed 3522;
BA_ "SPN" SG_ 2565869310 NOxSensorATI1SelfdiagnosisStatus 5714;
BA_ "SPN" SG_ 2565869310 Aftrtrtmnt1IntkOxygnSnsrPrlmnryF 3225;
BA_ "SPN" SG_ 2565869310 Aftrtrtmnt1IntkNOxSnsrPrlmnryFMI 3224;
BA_ "SigType" SG_ 2565869310 Aftrtrtmnt1IntkGsSnsorHeaterCtrl 5;
BA_ "SPN" SG_ 2565869310 Aftrtrtmnt1IntkGsSnsorHeaterCtrl 3223;
BA_ "SPN" SG_ 2565869310 Aftrtrtmnt1IntkGsSnsrHtrPrlmnryF 3222;
BA_ "SigType" SG_ 2565869310 Aftrtrtmnt1IntkWdRngO2RdngStable 5;
BA_ "SPN" SG_ 2565869310 Aftrtrtmnt1IntkWdRngO2RdngStable 3221;
BA_ "SigType" SG_ 2565869310 Aftrtrtmnt1IntkeNOxReadingStable 5;
BA_ "SPN" SG_ 2565869310 Aftrtrtmnt1IntkeNOxReadingStable 3220;
BA_ "SigType" SG_ 2565869310 Aftrtrtmnt1IntakeGasSensorAtTemp 5;
BA_ "SPN" SG_ 2565869310 Aftrtrtmnt1IntakeGasSensorAtTemp 3219;
BA_ "SigType" SG_ 2565869310 Aftrtrtmnt1IntkGsSnsrPowerStatus 5;
BA_ "SPN" SG_ 2565869310 Aftrtrtmnt1IntkGsSnsrPowerStatus 3218;
BA_ "SigType" SG_ 2565869310 Aftertreatment1IntakeO2 1;
BA_ "SPN" SG_ 2565869310 Aftertreatment1IntakeO2 3217;
BA_ "SigType" SG_ 2565869310 Aftertreatment1IntakeNOx 1;
BA_ "SPN" SG_ 2565869310 Aftertreatment1IntakeNOx 3216;
BA_ "SPN" SG_ 2566763774 Aftrtrtmnt1DslPrtcltFltrIntk3244 3244;
BA_ "SPN" SG_ 2566763774 Aftrtrtmnt1ExhstGsTmp1PrlmnryFMI 3243;
BA_ "SigType" SG_ 2566763774 Aftrtrtmnt1DslPrtcltFltrIntkGsTm 1;
BA_ "SPN" SG_ 2566763774 Aftrtrtmnt1DslPrtcltFltrIntkGsTm 3242;
BA_ "SigType" SG_ 2566763774 Aftertreatment1ExhaustGasTemp1 1;
BA_ "SPN" SG_ 2566763774 Aftertreatment1ExhaustGasTemp1 3241;
BA_ "SPN" SG_ 2631728894 AntitheftRandomNumber 1198;
BA_ "SigType" SG_ 2631728894 AntitheftModifyPwdStates 5;
BA_ "SPN" SG_ 2631728894 AntitheftModifyPwdStates 1197;
BA_ "SigType" SG_ 2631728894 AntitheftComponentStatusStates 5;
BA_ "SPN" SG_ 2631728894 AntitheftComponentStatusStates 1196;
BA_ "SigType" SG_ 2631728894 AntitheftPwdValidIndicator 5;
BA_ "SPN" SG_ 2631728894 AntitheftPwdValidIndicator 1195;
BA_ "SigType" SG_ 2631728894 AntthftEncryptnSdPrsentIndicator 5;
BA_ "SPN" SG_ 2631728894 AntthftEncryptnSdPrsentIndicator 1194;
BA_ "SPN" SG_ 2631794430 AntitheftPwdRepresentation 1202;
BA_ "SPN" SG_ 2631794430 AntitheftCmdStates 1201;
BA_ "SigType" SG_ 2631794430 AntitheftDesiredExitModeStates 5;
BA_ "SPN" SG_ 2631794430 AntitheftDesiredExitModeStates 1200;
BA_ "SigType" SG_ 2631794430 AntthftEncryptionIndicatorStates 5;
BA_ "SPN" SG_ 2631794430 AntthftEncryptionIndicatorStates 1199;
BA_ "SigType" SG_ 2633934846 EngAltWinding3Temp 1;
BA_ "SPN" SG_ 2633934846 EngAltWinding3Temp 1126;
BA_ "SigType" SG_ 2633934846 EngAltWinding2Temp 1;
BA_ "SPN" SG_ 2633934846 EngAltWinding2Temp 1125;
BA_ "SigType" SG_ 2633934846 EngAltWinding1Temp 1;
BA_ "SPN" SG_ 2633934846 EngAltWinding1Temp 1124;
BA_ "SigType" SG_ 2633934846 EngAltBearing2Temp 1;
BA_ "SPN" SG_ 2633934846 EngAltBearing2Temp 1123;
BA_ "SigType" SG_ 2633934846 EngAltBearing1Temp 1;
BA_ "SPN" SG_ 2633934846 EngAltBearing1Temp 1122;
BA_ "SigType" SG_ 2362572542 LevelPresetRearAxleRight 1;
BA_ "SPN" SG_ 2362572542 LevelPresetRearAxleRight 1735;
BA_ "SigType" SG_ 2362572542 LevelPresetRearAxleLeft 1;
BA_ "SPN" SG_ 2362572542 LevelPresetRearAxleLeft 1758;
BA_ "SigType" SG_ 2362572542 LevelPresetFrontAxleRight 1;
BA_ "SPN" SG_ 2362572542 LevelPresetFrontAxleRight 1757;
BA_ "SigType" SG_ 2362572542 LevelPresetFrontAxleLeft 1;
BA_ "SPN" SG_ 2362572542 LevelPresetFrontAxleLeft 1732;
BA_ "SigType" SG_ 2365478910 ElctrncShckAbsrbrCtrlMdLft_TgAxl 4;
BA_ "SPN" SG_ 2365478910 ElctrncShckAbsrbrCtrlMdLft_TgAxl 1831;
BA_ "SigType" SG_ 2365478910 ElctrncShckAbsrbrCtrlMdeRearAxle 4;
BA_ "SPN" SG_ 2365478910 ElctrncShckAbsrbrCtrlMdeRearAxle 1832;
BA_ "SigType" SG_ 2365478910 ElctrncShckAbsrbrCtrlMdFrontAxle 4;
BA_ "SPN" SG_ 2365478910 ElctrncShckAbsrbrCtrlMdFrontAxle 1833;
BA_ "SigType" SG_ 2365478910 DamperStiffnessLift_TagAxle 1;
BA_ "SPN" SG_ 2365478910 DamperStiffnessLift_TagAxle 1731;
BA_ "SigType" SG_ 2365478910 DamperStiffnessRearAxle 1;
BA_ "SPN" SG_ 2365478910 DamperStiffnessRearAxle 1730;
BA_ "SigType" SG_ 2365478910 DamperStiffnessFrontAxle 1;
BA_ "SPN" SG_ 2365478910 DamperStiffnessFrontAxle 1729;
BA_ "SPN" SG_ 2560950014 SPN1 1214;
BA_ "SigType" SG_ 2560950014 TestLimitMinimum 1;
BA_ "SPN" SG_ 2560950014 TestLimitMinimum 4112;
BA_ "SPN" SG_ 2560950014 FailureModeIdentifier1 1215;
BA_ "SigType" SG_ 2560950014 TestLimitMaximum 1;
BA_ "SPN" SG_ 2560950014 TestLimitMaximum 4111;
BA_ "SigType" SG_ 2560950014 TestValue 1;
BA_ "SPN" SG_ 2560950014 TestValue 4110;
BA_ "SigType" SG_ 2560950014 SlotId 1;
BA_ "SPN" SG_ 2560950014 SlotId 4109;
BA_ "SPN" SG_ 2566763262 Aftrtrtmnt1DslPrtcltFltrIntr3254 3254;
BA_ "SPN" SG_ 2566763262 Aftrtrtmnt1DslPrtcltFltrDltPrssP 3253;
BA_ "SPN" SG_ 2566763262 Aftrtrtmnt1ExhstGsTmp2PrlmnryFMI 3252;
BA_ "SigType" SG_ 2566763262 Aftrtrtmnt1DslPrtcltFltrDffPress 1;
BA_ "SPN" SG_ 2566763262 Aftrtrtmnt1DslPrtcltFltrDffPress 3251;
BA_ "SigType" SG_ 2566763262 Aftrtrtmnt1DslPrtcltFltrIntrmdtG 1;
BA_ "SPN" SG_ 2566763262 Aftrtrtmnt1DslPrtcltFltrIntrmdtG 3250;
BA_ "SigType" SG_ 2566763262 Aftertreatment1ExhaustGasTemp2 1;
BA_ "SPN" SG_ 2566763262 Aftertreatment1ExhaustGasTemp2 3249;
BA_ "SPN" SG_ 2565869566 Aftrtrtmnt1OtltOxygnSnsrPrlmnryF 3235;
BA_ "SPN" SG_ 2565869566 NOxSensorATO1SelfdiagnosisStatus 5713;
BA_ "SPN" SG_ 2565869566 Aftrtrtmnt1OtltNOxSnsrPrlmnryFMI 3234;
BA_ "SigType" SG_ 2565869566 Aftrtrtmnt1OtltGsSnsorHeaterCtrl 5;
BA_ "SPN" SG_ 2565869566 Aftrtrtmnt1OtltGsSnsorHeaterCtrl 3233;
BA_ "SPN" SG_ 2565869566 Aftrtrtmnt1OtltGsSnsrHtrPrlmnryF 3232;
BA_ "SigType" SG_ 2565869566 Aftrtrtmnt1OtltWdRngO2RdngStable 5;
BA_ "SPN" SG_ 2565869566 Aftrtrtmnt1OtltWdRngO2RdngStable 3231;
BA_ "SigType" SG_ 2565869566 Aftrtrtmnt1OtletNOxReadingStable 5;
BA_ "SPN" SG_ 2565869566 Aftrtrtmnt1OtletNOxReadingStable 3230;
BA_ "SigType" SG_ 2565869566 Aftrtrtmnt1OutletGasSensorAtTemp 5;
BA_ "SPN" SG_ 2565869566 Aftrtrtmnt1OutletGasSensorAtTemp 3229;
BA_ "SigType" SG_ 2565869566 Aftrtrtmnt1OtltGsSnsrPowerStatus 5;
BA_ "SPN" SG_ 2565869566 Aftrtrtmnt1OtltGsSnsrPowerStatus 3228;
BA_ "SigType" SG_ 2565869566 Aftertreatment1OutletO2 1;
BA_ "SPN" SG_ 2565869566 Aftertreatment1OutletO2 3227;
BA_ "SigType" SG_ 2565869566 Aftertreatment1OutletNOx 1;
BA_ "SPN" SG_ 2565869566 Aftertreatment1OutletNOx 3226;
BA_ "SPN" SG_ 2566763518 Aftrtrtmnt1DslPrtcltFltrOtltExhs 3248;
BA_ "SPN" SG_ 2566763518 Aftrtrtmnt1ExhstGsTmp3PrlmnryFMI 3247;
BA_ "SigType" SG_ 2566763518 Aftrtrtmnt1DslPrtcltFltrOtltGsTm 1;
BA_ "SPN" SG_ 2566763518 Aftrtrtmnt1DslPrtcltFltrOtltGsTm 3246;
BA_ "SigType" SG_ 2566763518 Aftertreatment1ExhaustGasTemp3 1;
BA_ "SPN" SG_ 2566763518 Aftertreatment1ExhaustGasTemp3 3245;
BA_ "SigType" SG_ 2566749182 Aftrtrtmnt1DslPrtcltFltrStLdRgnr 1;
BA_ "SPN" SG_ 2566749182 Aftrtrtmnt1DslPrtcltFltrStLdRgnr 5466;
BA_ "SigType" SG_ 2566749182 DslPrtcltFltr1TmSncLstActvRgnrtn 1;
BA_ "SPN" SG_ 2566749182 DslPrtcltFltr1TmSncLstActvRgnrtn 3721;
BA_ "SigType" SG_ 2566749182 DslPrtclateFilter1AshLoadPercent 1;
BA_ "SPN" SG_ 2566749182 DslPrtclateFilter1AshLoadPercent 3720;
BA_ "SigType" SG_ 2566749182 DslPrtclteFilter1SootLoadPercent 1;
BA_ "SPN" SG_ 2566749182 DslPrtclteFilter1SootLoadPercent 3719;
BA_ "SigType" SG_ 2566748670 Aftrtrtmnt1DslPrtcltFltrTrpN3740 1;
BA_ "SPN" SG_ 2566748670 Aftrtrtmnt1DslPrtcltFltrTrpN3740 3740;
BA_ "SigType" SG_ 2566748670 Aftrtrtmnt1DslPrtcltFltrTrpN3739 1;
BA_ "SPN" SG_ 2566748670 Aftrtrtmnt1DslPrtcltFltrTrpN3739 3739;
BA_ "SigType" SG_ 2566748670 Aftrtrtmnt1DslPrtcltFltrTrpN3738 1;
BA_ "SPN" SG_ 2566748670 Aftrtrtmnt1DslPrtcltFltrTrpN3738 3738;
BA_ "SigType" SG_ 2566748670 Aftrtrtmnt1DslPrtcltFltrTrpPssvR 1;
BA_ "SPN" SG_ 2566748670 Aftrtrtmnt1DslPrtcltFltrTrpPssvR 3737;
BA_ "SigType" SG_ 2566748670 Aftrtrtmnt1DslPrtcltFltrTrpNmbrO 1;
BA_ "SPN" SG_ 2566748670 Aftrtrtmnt1DslPrtcltFltrTrpNmbrO 3736;
BA_ "SigType" SG_ 2566748670 Aftrtrtmnt1DslPrtcltFltrTrpDsbld 1;
BA_ "SPN" SG_ 2566748670 Aftrtrtmnt1DslPrtcltFltrTrpDsbld 3735;
BA_ "SigType" SG_ 2566748670 Aftrtrtmnt1DslPrtcltFltrTrpActvR 1;
BA_ "SPN" SG_ 2566748670 Aftrtrtmnt1DslPrtcltFltrTrpActvR 3734;
BA_ "SigType" SG_ 2566748670 Aftrtrtmnt1DslPrtcltFltrTrpFlUsd 1;
BA_ "SPN" SG_ 2566748670 Aftrtrtmnt1DslPrtcltFltrTrpFlUsd 3733;
BA_ "SigType" SG_ 2566758142 Aftertreatment2AirEnableActuator 5;
BA_ "SPN" SG_ 2566758142 Aftertreatment2AirEnableActuator 3503;
BA_ "SigType" SG_ 2566758142 Aftertreatment2PurgeAirActuator 5;
BA_ "SPN" SG_ 2566758142 Aftertreatment2PurgeAirActuator 3504;
BA_ "SigType" SG_ 2566758142 Aftrtrtmnt2AtmizationAirActuator 5;
BA_ "SPN" SG_ 2566758142 Aftrtrtmnt2AtmizationAirActuator 3505;
BA_ "SigType" SG_ 2566758142 Aftertreatment2AirSystemRelay 5;
BA_ "SPN" SG_ 2566758142 Aftertreatment2AirSystemRelay 3506;
BA_ "SigType" SG_ 2566758142 Aftrtratment2AirPressActuatorPos 1;
BA_ "SPN" SG_ 2566758142 Aftrtratment2AirPressActuatorPos 3502;
BA_ "SigType" SG_ 2566758142 Aftertreatment2AirPressCtrl 1;
BA_ "SPN" SG_ 2566758142 Aftertreatment2AirPressCtrl 3501;
BA_ "SigType" SG_ 2566758142 Aftertreatment2PurgeAirPress 1;
BA_ "SPN" SG_ 2566758142 Aftertreatment2PurgeAirPress 3500;
BA_ "SigType" SG_ 2566758142 Aftertreatment2SupplyAirPress 1;
BA_ "SPN" SG_ 2566758142 Aftertreatment2SupplyAirPress 3499;
BA_ "SigType" SG_ 2566745342 Aftertreatment2SecondAirPress 1;
BA_ "SPN" SG_ 2566745342 Aftertreatment2SecondAirPress 3838;
BA_ "SigType" SG_ 2566745342 Aftertreatment2SecondAirMassFlow 1;
BA_ "SPN" SG_ 2566745342 Aftertreatment2SecondAirMassFlow 3835;
BA_ "SigType" SG_ 2566745342 Aftertreatment2SecondAirTemp 1;
BA_ "SPN" SG_ 2566745342 Aftertreatment2SecondAirTemp 3834;
BA_ "SigType" SG_ 2566745342 Aftrtreatment2SecondAirDiffPress 1;
BA_ "SPN" SG_ 2566745342 Aftrtreatment2SecondAirDiffPress 3833;
BA_ "SigType" SG_ 2566758654 Aftrtrtmnt2FlInjector1HeaterCtrl 1;
BA_ "SPN" SG_ 2566758654 Aftrtrtmnt2FlInjector1HeaterCtrl 4302;
BA_ "SigType" SG_ 2566758654 Aftrtreatment2FuelEnableActuator 5;
BA_ "SPN" SG_ 2566758654 Aftrtreatment2FuelEnableActuator 3496;
BA_ "SigType" SG_ 2566758654 Aftrtreatment2RegenerationStatus 5;
BA_ "SPN" SG_ 2566758654 Aftrtreatment2RegenerationStatus 3497;
BA_ "SigType" SG_ 2566758654 Aftertreatment2Ignt 5;
BA_ "SPN" SG_ 2566758654 Aftertreatment2Ignt 3498;
BA_ "SigType" SG_ 2566758654 Aftertreatment2FuelDrainActuator 5;
BA_ "SPN" SG_ 2566758654 Aftertreatment2FuelDrainActuator 4098;
BA_ "SigType" SG_ 2566758654 Aftertreatment2FuelPress1Ctrl 1;
BA_ "SPN" SG_ 2566758654 Aftertreatment2FuelPress1Ctrl 3493;
BA_ "SigType" SG_ 2566758654 Aftertreatment2FuelRate 1;
BA_ "SPN" SG_ 2566758654 Aftertreatment2FuelRate 3495;
BA_ "SigType" SG_ 2566758654 Aftertreatment2FuelPress1 1;
BA_ "SPN" SG_ 2566758654 Aftertreatment2FuelPress1 3494;
BA_ "SigType" SG_ 2566753278 DslParticulateFilterOutletPress2 1;
BA_ "SPN" SG_ 2566753278 DslParticulateFilterOutletPress2 3612;
BA_ "SigType" SG_ 2566753278 DslParticulateFilterIntakePress2 1;
BA_ "SPN" SG_ 2566753278 DslParticulateFilterIntakePress2 3611;
BA_ "SigType" SG_ 2566756862 Aftrtrtmnt2AvrgDstncBtwnActvDPFR 1;
BA_ "SPN" SG_ 2566756862 Aftrtrtmnt2AvrgDstncBtwnActvDPFR 5828;
BA_ "SigType" SG_ 2566756862 Aftrtrtmnt2AvrgTmBtwnActvRgnrtns 1;
BA_ "SPN" SG_ 2566756862 Aftrtrtmnt2AvrgTmBtwnActvRgnrtns 5455;
BA_ "SigType" SG_ 2566756862 Aftrtrtmnt2DslPrtcltFltrTtlN3732 1;
BA_ "SPN" SG_ 2566756862 Aftrtrtmnt2DslPrtcltFltrTtlN3732 3732;
BA_ "SigType" SG_ 2566756862 Aftrtrtmnt2DslPrtcltFltrTtlN3731 1;
BA_ "SPN" SG_ 2566756862 Aftrtrtmnt2DslPrtcltFltrTtlN3731 3731;
BA_ "SigType" SG_ 2566756862 Aftrtrtmnt2DslPrtcltFltrTtlNmbrO 1;
BA_ "SPN" SG_ 2566756862 Aftrtrtmnt2DslPrtcltFltrTtlNmbrO 3730;
BA_ "SigType" SG_ 2566756862 Aftrtrtmnt2DslPrtcltFltrTtlPssvR 1;
BA_ "SPN" SG_ 2566756862 Aftrtrtmnt2DslPrtcltFltrTtlPssvR 3729;
BA_ "SigType" SG_ 2566756862 Aftrtrtmnt2TtlNmbrOfActvRgnrtons 1;
BA_ "SPN" SG_ 2566756862 Aftrtrtmnt2TtlNmbrOfActvRgnrtons 3529;
BA_ "SigType" SG_ 2566756862 Aftertreatment2TotalDisabledTime 1;
BA_ "SPN" SG_ 2566756862 Aftertreatment2TotalDisabledTime 3528;
BA_ "SigType" SG_ 2566756862 Aftrtrtmnt2TotalRegenerationTime 1;
BA_ "SPN" SG_ 2566756862 Aftrtrtmnt2TotalRegenerationTime 3527;
BA_ "SigType" SG_ 2566756862 Aftertreatment2TotalFuelUsed 1;
BA_ "SPN" SG_ 2566756862 Aftertreatment2TotalFuelUsed 3526;
BA_ "SPN" SG_ 2565869822 NOxSensorATI2SelfdiagnosisStatus 5716;
BA_ "SPN" SG_ 2565869822 Aftrtrtmnt2IntkOxygnSnsrPrlmnryF 3264;
BA_ "SPN" SG_ 2565869822 Aftrtrtmnt2IntkNOxSnsrPrlmnryFMI 3263;
BA_ "SigType" SG_ 2565869822 Aftrtrtmnt2IntkGsSnsorHeaterCtrl 5;
BA_ "SPN" SG_ 2565869822 Aftrtrtmnt2IntkGsSnsorHeaterCtrl 3262;
BA_ "SPN" SG_ 2565869822 Aftrtrtmnt2IntkGsSnsrHtrPrlmnryF 3261;
BA_ "SigType" SG_ 2565869822 Aftrtrtmnt2IntkWdRngO2RdngStable 5;
BA_ "SPN" SG_ 2565869822 Aftrtrtmnt2IntkWdRngO2RdngStable 3260;
BA_ "SigType" SG_ 2565869822 Aftrtrtmnt2IntkeNOxReadingStable 5;
BA_ "SPN" SG_ 2565869822 Aftrtrtmnt2IntkeNOxReadingStable 3259;
BA_ "SigType" SG_ 2565869822 Aftrtrtmnt2IntakeGasSensorAtTemp 5;
BA_ "SPN" SG_ 2565869822 Aftrtrtmnt2IntakeGasSensorAtTemp 3258;
BA_ "SigType" SG_ 2565869822 Aftrtrtmnt2IntkGsSnsrPowerStatus 5;
BA_ "SPN" SG_ 2565869822 Aftrtrtmnt2IntkGsSnsrPowerStatus 3257;
BA_ "SigType" SG_ 2565869822 Aftertreatment2IntakeO2 1;
BA_ "SPN" SG_ 2565869822 Aftertreatment2IntakeO2 3256;
BA_ "SigType" SG_ 2565869822 Aftertreatment2IntakeNOx 1;
BA_ "SPN" SG_ 2565869822 Aftertreatment2IntakeNOx 3255;
BA_ "SPN" SG_ 2566763006 Aftrtrtmnt2DslPrtcltFltrIntk3278 3278;
BA_ "SPN" SG_ 2566763006 Aftrtrtmnt2ExhstGsTmp1PrlmnryFMI 3277;
BA_ "SigType" SG_ 2566763006 Aftrtrtmnt2DslPrtcltFltrIntkGsTm 1;
BA_ "SPN" SG_ 2566763006 Aftrtrtmnt2DslPrtcltFltrIntkGsTm 3276;
BA_ "SigType" SG_ 2566763006 Aftertreatment2ExhaustGasTemp1 1;
BA_ "SPN" SG_ 2566763006 Aftertreatment2ExhaustGasTemp1 3275;
BA_ "SPN" SG_ 2566762494 Aftrtrtmnt2DslPrtcltFltrIntr3288 3288;
BA_ "SPN" SG_ 2566762494 Aftrtrtmnt2DslPrtcltFltrDltPrssP 3287;
BA_ "SPN" SG_ 2566762494 Aftrtrtmnt2ExhstGsTmp2PrlmnryFMI 3286;
BA_ "SigType" SG_ 2566762494 Aftrtrtmnt2DslPrtcltFltrDffPress 1;
BA_ "SPN" SG_ 2566762494 Aftrtrtmnt2DslPrtcltFltrDffPress 3285;
BA_ "SigType" SG_ 2566762494 Aftrtrtmnt2DslPrtcltFltrIntrmdtG 1;
BA_ "SPN" SG_ 2566762494 Aftrtrtmnt2DslPrtcltFltrIntrmdtG 3284;
BA_ "SigType" SG_ 2566762494 Aftertreatment2ExhaustGasTemp2 1;
BA_ "SPN" SG_ 2566762494 Aftertreatment2ExhaustGasTemp2 3283;
BA_ "SPN" SG_ 2565870078 Aftrtrtmnt2OtltOxygnSnsrPrlmnryF 3274;
BA_ "SPN" SG_ 2565870078 Aftrtrtmnt2OtltNOxSnsrPrlmnryFMI 3273;
BA_ "SigType" SG_ 2565870078 Aftrtrtmnt2OtltGsSnsorHeaterCtrl 5;
BA_ "SPN" SG_ 2565870078 Aftrtrtmnt2OtltGsSnsorHeaterCtrl 3272;
BA_ "SPN" SG_ 2565870078 Aftrtrtmnt2OtltGsSnsrHtrPrlmnryF 3271;
BA_ "SigType" SG_ 2565870078 Aftrtrtmnt2OtltWdRngO2RdngStable 5;
BA_ "SPN" SG_ 2565870078 Aftrtrtmnt2OtltWdRngO2RdngStable 3270;
BA_ "SigType" SG_ 2565870078 Aftrtrtmnt2OtletNOxReadingStable 5;
BA_ "SPN" SG_ 2565870078 Aftrtrtmnt2OtletNOxReadingStable 3269;
BA_ "SPN" SG_ 2565870078 NOxSensorATO2SelfdiagnosisStatus 5715;
BA_ "SigType" SG_ 2565870078 Aftrtrtmnt2OutletGasSensorAtTemp 5;
BA_ "SPN" SG_ 2565870078 Aftrtrtmnt2OutletGasSensorAtTemp 3268;
BA_ "SigType" SG_ 2565870078 Aftrtrtmnt2OtltGsSnsrPowerStatus 5;
BA_ "SPN" SG_ 2565870078 Aftrtrtmnt2OtltGsSnsrPowerStatus 3267;
BA_ "SigType" SG_ 2565870078 Aftertreatment2OutletO2 1;
BA_ "SPN" SG_ 2565870078 Aftertreatment2OutletO2 3266;
BA_ "SigType" SG_ 2565870078 Aftertreatment2OutletNOx 1;
BA_ "SPN" SG_ 2565870078 Aftertreatment2OutletNOx 3265;
BA_ "SPN" SG_ 2566762750 Aftrtrtmnt2DslPrtcltFltrExhstGsT 3282;
BA_ "SPN" SG_ 2566762750 Aftrtrtmnt2ExhstGsTmp3PrlmnryFMI 3281;
BA_ "SigType" SG_ 2566762750 Aftrtrtmnt2DslPrtcltFltrOtltGsTm 1;
BA_ "SPN" SG_ 2566762750 Aftrtrtmnt2DslPrtcltFltrOtltGsTm 3280;
BA_ "SigType" SG_ 2566762750 Aftertreatment2ExhaustGasTemp3 1;
BA_ "SPN" SG_ 2566762750 Aftertreatment2ExhaustGasTemp3 3279;
BA_ "SigType" SG_ 2566748926 Aftrtrtmnt2DslPrtcltFltrStLdRgnr 1;
BA_ "SPN" SG_ 2566748926 Aftrtrtmnt2DslPrtcltFltrStLdRgnr 5467;
BA_ "SigType" SG_ 2566748926 DslPrtcltFltr2TmSncLstActvRgnrtn 1;
BA_ "SPN" SG_ 2566748926 DslPrtcltFltr2TmSncLstActvRgnrtn 3724;
BA_ "SigType" SG_ 2566748926 DslPrtclateFilter2AshLoadPercent 1;
BA_ "SPN" SG_ 2566748926 DslPrtclateFilter2AshLoadPercent 3723;
BA_ "SigType" SG_ 2566748926 DslPrtclteFilter2SootLoadPercent 1;
BA_ "SPN" SG_ 2566748926 DslPrtclteFilter2SootLoadPercent 3722;
BA_ "SigType" SG_ 2566748414 Aftrtrtmnt2DslPrtcltFltrTrpN3748 1;
BA_ "SPN" SG_ 2566748414 Aftrtrtmnt2DslPrtcltFltrTrpN3748 3748;
BA_ "SigType" SG_ 2566748414 Aftrtrtmnt2DslPrtcltFltrTrpN3747 1;
BA_ "SPN" SG_ 2566748414 Aftrtrtmnt2DslPrtcltFltrTrpN3747 3747;
BA_ "SigType" SG_ 2566748414 Aftrtrtmnt2DslPrtcltFltrTrpN3746 1;
BA_ "SPN" SG_ 2566748414 Aftrtrtmnt2DslPrtcltFltrTrpN3746 3746;
BA_ "SigType" SG_ 2566748414 Aftrtrtmnt2DslPrtcltFltrTrpPssvR 1;
BA_ "SPN" SG_ 2566748414 Aftrtrtmnt2DslPrtcltFltrTrpPssvR 3745;
BA_ "SigType" SG_ 2566748414 Aftrtrtmnt2DslPrtcltFltrTrpNmbrO 1;
BA_ "SPN" SG_ 2566748414 Aftrtrtmnt2DslPrtcltFltrTrpNmbrO 3744;
BA_ "SigType" SG_ 2566748414 Aftrtrtmnt2DslPrtcltFltrTrpDsbld 1;
BA_ "SPN" SG_ 2566748414 Aftrtrtmnt2DslPrtcltFltrTrpDsbld 3743;
BA_ "SigType" SG_ 2566748414 Aftrtrtmnt2DslPrtcltFltrTrpActvR 1;
BA_ "SPN" SG_ 2566748414 Aftrtrtmnt2DslPrtcltFltrTrpActvR 3742;
BA_ "SigType" SG_ 2566748414 Aftrtrtmnt2DslPrtcltFltrTrpFlUsd 1;
BA_ "SPN" SG_ 2566748414 Aftrtrtmnt2DslPrtcltFltrTrpFlUsd 3741;
BA_ "SigType" SG_ 2365428478 EngStarterMotorRelayCtrl 5;
BA_ "SPN" SG_ 2365428478 EngStarterMotorRelayCtrl 6385;
BA_ "SigType" SG_ 2365428478 EngDerateRq 1;
BA_ "SPN" SG_ 2365428478 EngDerateRq 3644;
BA_ "SigType" SG_ 2365428478 EngEmergencyShutdownIndication 5;
BA_ "SPN" SG_ 2365428478 EngEmergencyShutdownIndication 3607;
BA_ "SigType" SG_ 2365428478 EngControlledShutdownRq 5;
BA_ "SPN" SG_ 2365428478 EngControlledShutdownRq 3606;
BA_ "SigType" SG_ 2365428478 EngCoolantCirculatingPumpCtrl 5;
BA_ "SPN" SG_ 2365428478 EngCoolantCirculatingPumpCtrl 3605;
BA_ "SigType" SG_ 2365428478 EngBlock_CoolantPreheaterCtrl 5;
BA_ "SPN" SG_ 2365428478 EngBlock_CoolantPreheaterCtrl 3604;
BA_ "SigType" SG_ 2365428478 EngElctrclSystmPwrCnsrvationCtrl 5;
BA_ "SPN" SG_ 2365428478 EngElctrclSystmPwrCnsrvationCtrl 3603;
BA_ "SigType" SG_ 2365428478 EngOilPreheaterCtrl 5;
BA_ "SPN" SG_ 2365428478 EngOilPreheaterCtrl 3602;
BA_ "SigType" SG_ 2365428478 EngOilPrimingPumpCtrl 5;
BA_ "SPN" SG_ 2365428478 EngOilPrimingPumpCtrl 3589;
BA_ "SigType" SG_ 2365428478 EngFuelShutoffValveLeakTestCtrl 5;
BA_ "SPN" SG_ 2365428478 EngFuelShutoffValveLeakTestCtrl 3601;
BA_ "SigType" SG_ 2365428478 EngFuelShutoff2Ctrl 5;
BA_ "SPN" SG_ 2365428478 EngFuelShutoff2Ctrl 2807;
BA_ "SigType" SG_ 2365428478 EngFuelShutoff1Ctrl 5;
BA_ "SPN" SG_ 2365428478 EngFuelShutoff1Ctrl 632;
BA_ "SigType" SG_ 2365428478 EngFuelShutoffVentCtrl 5;
BA_ "SPN" SG_ 2365428478 EngFuelShutoffVentCtrl 3608;
BA_ "SigType" SG_ 2365428478 TimeRemainingInEngOperatingState 1;
BA_ "SPN" SG_ 2365428478 TimeRemainingInEngOperatingState 3544;
BA_ "SigType" SG_ 2365428478 FuelPumpPrimerCtrl 5;
BA_ "SPN" SG_ 2365428478 FuelPumpPrimerCtrl 4082;
BA_ "SPN" SG_ 2365428478 EngOperatingState 3543;
BA_ "SigType" SG_ 2566743806 EngCoolantTemp3 1;
BA_ "SPN" SG_ 2566743806 EngCoolantTemp3 6209;
BA_ "SigType" SG_ 2566743806 EngExhstGsRcrcltn1MxerIntakeTemp 1;
BA_ "SPN" SG_ 2566743806 EngExhstGsRcrcltn1MxerIntakeTemp 5020;
BA_ "SigType" SG_ 2566743806 EngExhstVlvActationSystemOilTemp 1;
BA_ "SPN" SG_ 2566743806 EngExhstVlvActationSystemOilTemp 4288;
BA_ "SigType" SG_ 2566743806 EngCoolantThermostatOpening 1;
BA_ "SPN" SG_ 2566743806 EngCoolantThermostatOpening 4194;
BA_ "SigType" SG_ 2566743806 EngCoolantPumpOutletTemp 1;
BA_ "SPN" SG_ 2566743806 EngCoolantPumpOutletTemp 4193;
BA_ "SigType" SG_ 2566743806 EngCoolantTemp2 1;
BA_ "SPN" SG_ 2566743806 EngCoolantTemp2 4076;
BA_ "SPN" SG_ 2499635454 NetVehicleWeightChange 413;
BA_ "SPN" SG_ 2499635454 GrossCombinationWeight 417;
BA_ "SigType" SG_ 2550660862 ValveAssemblySupplyPress 1;
BA_ "SPN" SG_ 2550660862 ValveAssemblySupplyPress 4089;
BA_ "SigType" SG_ 2550660862 ValveAssemblyLoadSensePress 1;
BA_ "SPN" SG_ 2550660862 ValveAssemblyLoadSensePress 4088;
BA_ "SigType" SG_ 2550660862 ValvePilotPress 1;
BA_ "SPN" SG_ 2550660862 ValvePilotPress 4087;
BA_ "SigType" SG_ 2550660862 ValveLoadSensePress 1;
BA_ "SPN" SG_ 2550660862 ValveLoadSensePress 4086;
BA_ "SigType" SG_ 2566805758 BellowPressRearAxleRight 1;
BA_ "SPN" SG_ 2566805758 BellowPressRearAxleRight 1728;
BA_ "SigType" SG_ 2566805758 BellowPressRearAxleLeft 1;
BA_ "SPN" SG_ 2566805758 BellowPressRearAxleLeft 1727;
BA_ "SigType" SG_ 2566805758 BellowPressFrontAxleRight 1;
BA_ "SPN" SG_ 2566805758 BellowPressFrontAxleRight 1726;
BA_ "SigType" SG_ 2566805758 BellowPressFrontAxleLeft 1;
BA_ "SPN" SG_ 2566805758 BellowPressFrontAxleLeft 1725;
BA_ "SigType" SG_ 2566806014 RelativeLevelRearAxleRight 1;
BA_ "SPN" SG_ 2566806014 RelativeLevelRearAxleRight 1723;
BA_ "SigType" SG_ 2566806014 RelativeLevelRearAxleLeft 1;
BA_ "SPN" SG_ 2566806014 RelativeLevelRearAxleLeft 1724;
BA_ "SigType" SG_ 2566806014 RelativeLevelFrontAxleRight 1;
BA_ "SPN" SG_ 2566806014 RelativeLevelFrontAxleRight 1722;
BA_ "SigType" SG_ 2566806014 RelativeLevelFrontAxleLeft 1;
BA_ "SPN" SG_ 2566806014 RelativeLevelFrontAxleLeft 1721;
BA_ "SPN" SG_ 2362638078 MemoryLevelRq 5433;
BA_ "SigType" SG_ 2362638078 PrhbitAutomaticAirSuspensionCtrl 5;
BA_ "SPN" SG_ 2362638078 PrhbitAutomaticAirSuspensionCtrl 5274;
BA_ "SigType" SG_ 2362638078 SpeedDependentLevelCtrlRq 5;
BA_ "SPN" SG_ 2362638078 SpeedDependentLevelCtrlRq 5295;
BA_ "SigType" SG_ 2362638078 AllowLevelCtrlDuringBrakingCmd 5;
BA_ "SPN" SG_ 2362638078 AllowLevelCtrlDuringBrakingCmd 5293;
BA_ "SigType" SG_ 2362638078 ProhibitAirSuspensionCtrl 5;
BA_ "SPN" SG_ 2362638078 ProhibitAirSuspensionCtrl 3215;
BA_ "SigType" SG_ 2362638078 KneelingCmdRearAxle 5;
BA_ "SPN" SG_ 2362638078 KneelingCmdRearAxle 1829;
BA_ "SigType" SG_ 2362638078 KneelingCmdFrontAxle 5;
BA_ "SPN" SG_ 2362638078 KneelingCmdFrontAxle 1830;
BA_ "SigType" SG_ 2362638078 DamperStiffnessRqLift_TagAxle 1;
BA_ "SPN" SG_ 2362638078 DamperStiffnessRqLift_TagAxle 1720;
BA_ "SigType" SG_ 2362638078 DamperStiffnessRqRearAxle 1;
BA_ "SPN" SG_ 2362638078 DamperStiffnessRqRearAxle 1719;
BA_ "SigType" SG_ 2362638078 DamperStiffnessRqFrontAxle 1;
BA_ "SPN" SG_ 2362638078 DamperStiffnessRqFrontAxle 1718;
BA_ "SigType" SG_ 2362638078 LiftAxle2PosCmd 5;
BA_ "SPN" SG_ 2362638078 LiftAxle2PosCmd 1828;
BA_ "SigType" SG_ 2362638078 LiftAxle1PosCmd 5;
BA_ "SPN" SG_ 2362638078 LiftAxle1PosCmd 1752;
BA_ "SPN" SG_ 2362638078 LevelCtrlModeRq 1753;
BA_ "SPN" SG_ 2362638078 NominalLevelRqRearAxle 1750;
BA_ "SPN" SG_ 2362638078 NominalLevelRqFrontAxle 1751;
BA_ "SigType" SG_ 2362638078 KneelingCtrlModeRq 5;
BA_ "SPN" SG_ 2362638078 KneelingCtrlModeRq 1747;
BA_ "SigType" SG_ 2362638078 KneelingRqRightSide 5;
BA_ "SPN" SG_ 2362638078 KneelingRqRightSide 1748;
BA_ "SigType" SG_ 2362638078 KneelingRqLeftSide 5;
BA_ "SPN" SG_ 2362638078 KneelingRqLeftSide 1749;
BA_ "SigType" SG_ 2362638078 AutomaticTractionHelp 5;
BA_ "SPN" SG_ 2362638078 AutomaticTractionHelp 2984;
BA_ "SPN" SG_ 2365479678 MemoryLevel 5432;
BA_ "SPN" SG_ 2365479678 SuspensionCtrlRefusalInformation 1827;
BA_ "SigType" SG_ 2365479678 SpeedDependantLevelCtrlStatus 5;
BA_ "SPN" SG_ 2365479678 SpeedDependantLevelCtrlStatus 5296;
BA_ "SigType" SG_ 2365479678 AllwLevelCtrlDuringBrakingStatus 5;
BA_ "SPN" SG_ 2365479678 AllwLevelCtrlDuringBrakingStatus 5294;
BA_ "SigType" SG_ 2365479678 SuspensionRemoteCtrl2 4;
BA_ "SPN" SG_ 2365479678 SuspensionRemoteCtrl2 1825;
BA_ "SigType" SG_ 2365479678 SuspensionRemoteCtrl1 4;
BA_ "SPN" SG_ 2365479678 SuspensionRemoteCtrl1 1826;
BA_ "SigType" SG_ 2365479678 LiftAxle2Pos 4;
BA_ "SPN" SG_ 2365479678 LiftAxle2Pos 1822;
BA_ "SigType" SG_ 2365479678 RearAxleInBumperRange 4;
BA_ "SPN" SG_ 2365479678 RearAxleInBumperRange 1823;
BA_ "SigType" SG_ 2365479678 FrontAxleInBumperRange 4;
BA_ "SPN" SG_ 2365479678 FrontAxleInBumperRange 1824;
BA_ "SigType" SG_ 2365479678 LiftAxle1Pos 4;
BA_ "SPN" SG_ 2365479678 LiftAxle1Pos 1743;
BA_ "SigType" SG_ 2365479678 DoorRelease 5;
BA_ "SPN" SG_ 2365479678 DoorRelease 1744;
BA_ "SigType" SG_ 2365479678 VehicleMotionInhibit 5;
BA_ "SPN" SG_ 2365479678 VehicleMotionInhibit 1745;
BA_ "SigType" SG_ 2365479678 SecurityDevice 5;
BA_ "SPN" SG_ 2365479678 SecurityDevice 1746;
BA_ "SPN" SG_ 2365479678 LevelCtrlMode 1741;
BA_ "SPN" SG_ 2365479678 KneelingInformation 1742;
BA_ "SigType" SG_ 2365479678 LiftingCtrlModeRearAxle 5;
BA_ "SPN" SG_ 2365479678 LiftingCtrlModeRearAxle 1756;
BA_ "SigType" SG_ 2365479678 LiftingCtrlModeFrontAxle 5;
BA_ "SPN" SG_ 2365479678 LiftingCtrlModeFrontAxle 1739;
BA_ "SigType" SG_ 2365479678 LoweringCtrlModeRearAxle 5;
BA_ "SPN" SG_ 2365479678 LoweringCtrlModeRearAxle 1755;
BA_ "SigType" SG_ 2365479678 LoweringCtrlModeFrontAxle 5;
BA_ "SPN" SG_ 2365479678 LoweringCtrlModeFrontAxle 1740;
BA_ "SigType" SG_ 2365479678 AboveNominalLevelRearAxle 4;
BA_ "SPN" SG_ 2365479678 AboveNominalLevelRearAxle 1736;
BA_ "SigType" SG_ 2365479678 AboveNominalLevelFrontAxle 4;
BA_ "SPN" SG_ 2365479678 AboveNominalLevelFrontAxle 1737;
BA_ "SigType" SG_ 2365479678 BelowNominalLevelRearAxle 5;
BA_ "SPN" SG_ 2365479678 BelowNominalLevelRearAxle 1754;
BA_ "SigType" SG_ 2365479678 BelowNominalLevelFrontAxle 4;
BA_ "SPN" SG_ 2365479678 BelowNominalLevelFrontAxle 1738;
BA_ "SPN" SG_ 2365479678 NominalLevelRearAxle 1733;
BA_ "SPN" SG_ 2365479678 NominalLevelFrontAxle 1734;
BA_ "SigType" SG_ 2566837758 Alt4Status 4;
BA_ "SPN" SG_ 2566837758 Alt4Status 3356;
BA_ "SigType" SG_ 2566837758 Alt3Status 4;
BA_ "SPN" SG_ 2566837758 Alt3Status 3355;
BA_ "SigType" SG_ 2566837758 Alt2Status 4;
BA_ "SPN" SG_ 2566837758 Alt2Status 3354;
BA_ "SigType" SG_ 2566837758 Alt1Status 4;
BA_ "SPN" SG_ 2566837758 Alt1Status 3353;
BA_ "SigType" SG_ 2566837758 AltSpeed 1;
BA_ "SPN" SG_ 2566837758 AltSpeed 589;
BA_ "SigType" SG_ 2633922558 AuxAbsPressReading 1;
BA_ "SPN" SG_ 2633922558 AuxAbsPressReading 138;
BA_ "SigType" SG_ 2633922558 AuxGagePressReading1 1;
BA_ "SPN" SG_ 2633922558 AuxGagePressReading1 137;
BA_ "SigType" SG_ 2633922558 AuxVacuumPressReading 1;
BA_ "SPN" SG_ 2633922558 AuxVacuumPressReading 136;
BA_ "SigType" SG_ 2566775038 BarometricAbsPressHighResolution 1;
BA_ "SPN" SG_ 2566775038 BarometricAbsPressHighResolution 5685;
BA_ "SigType" SG_ 2566775038 CalculatedAmbientAirTemp 1;
BA_ "SPN" SG_ 2566775038 CalculatedAmbientAirTemp 5581;
BA_ "SigType" SG_ 2566775038 SpecificHumidity 1;
BA_ "SPN" SG_ 2566775038 SpecificHumidity 4490;
BA_ "SigType" SG_ 2566775038 SolarSensorMax 1;
BA_ "SPN" SG_ 2566775038 SolarSensorMax 2611;
BA_ "SigType" SG_ 2566775038 SolarIntensityPercent 1;
BA_ "SPN" SG_ 2566775038 SolarIntensityPercent 2610;
BA_ "SigType" SG_ 2365509886 TestLimitMinimum 1;
BA_ "SPN" SG_ 2365509886 TestLimitMinimum 1228;
BA_ "SigType" SG_ 2365509886 TestLimitMaximum 1;
BA_ "SPN" SG_ 2365509886 TestLimitMaximum 1227;
BA_ "SigType" SG_ 2365509886 TestValue 1;
BA_ "SPN" SG_ 2365509886 TestValue 1226;
BA_ "SigType" SG_ 2365509886 TestType 1;
BA_ "GenSigStartValue" SG_ 2365509886 TestType 1;
BA_ "SPN" SG_ 2365509886 TestType 1225;
BA_ "SPN" SG_ 2365509886 TestIdentifier 1224;
BA_ "SPN" SG_ 2363752190 SPN1 4148;
BA_ "SPN" SG_ 2363752190 TestIdentifier 1224;
BA_ "SPN" SG_ 2363752190 FailureModeIdentifier1 4149;
BA_ "SigType" SG_ 2566836222 FlashRedStopLamp 5;
BA_ "SPN" SG_ 2566836222 FlashRedStopLamp 3039;
BA_ "SigType" SG_ 2566836222 FlashProtectLamp 5;
BA_ "SPN" SG_ 2566836222 FlashProtectLamp 3041;
BA_ "SigType" SG_ 2566836222 FlashMalfuncIndicatorLamp 5;
BA_ "SPN" SG_ 2566836222 FlashMalfuncIndicatorLamp 3038;
BA_ "SigType" SG_ 2566836222 FlashAmberWarningLamp 5;
BA_ "SPN" SG_ 2566836222 FlashAmberWarningLamp 3040;
BA_ "SigType" SG_ 2566836222 MalfunctionIndicatorLampStatus 5;
BA_ "SPN" SG_ 2566836222 MalfunctionIndicatorLampStatus 1213;
BA_ "SigType" SG_ 2566836222 RedStopLampState 4;
BA_ "SPN" SG_ 2566836222 RedStopLampState 623;
BA_ "SigType" SG_ 2566836222 AmberWarningLampStatus 5;
BA_ "SPN" SG_ 2566836222 AmberWarningLampStatus 624;
BA_ "SigType" SG_ 2566836222 ProtectLampStatus 5;
BA_ "SPN" SG_ 2566836222 ProtectLampStatus 987;
BA_ "SigType" SG_ 2566836222 DTC5 7;
BA_ "SigType" SG_ 2566836222 DTC4 7;
BA_ "SigType" SG_ 2566836222 DTC3 7;
BA_ "SigType" SG_ 2566836222 DTC2 7;
BA_ "SigType" SG_ 2566836222 DTC1 7;
BA_ "SystemSignalLongSymbol" SG_ 2365509374 NOxConvertingCatalystAdsorberSta "NOxConvertingCatalystAdsorberStatus";
BA_ "SystemSignalLongSymbol" SG_ 2365509374 BoostPressureControlSystemSuppor "BoostPressureControlSystemSupport";
BA_ "SystemSignalLongSymbol" SG_ 2365509374 NOxConvertingCatalystAdsorberSup "NOxConvertingCatalystAdsorberSupport";
BA_ "SigType" SG_ 2365509374 OBDCompliance 1;
BA_ "SPN" SG_ 2365509374 OBDCompliance 1220;
BA_ "SigType" SG_ 2365509374 PreviouslyActiveTroubleCodes 1;
BA_ "SPN" SG_ 2365509374 PreviouslyActiveTroubleCodes 1219;
BA_ "SigType" SG_ 2365509374 ActiveTroubleCodes 1;
BA_ "SPN" SG_ 2365509374 ActiveTroubleCodes 1218;
VAL_ 2566847230 ParkingBrakeRedWarningSignal 3 "Take no action" 2 "Reserved" 1 "on" 0 "off" ;
VAL_ 2566847230 ParkBrakeReleaseInhibitStatus 3 "Unavailable" 2 "Error" 1 "ParkBrakeReleaseIsInhibited" 0 "ParkBrakeReleaseIsNotInhibited" ;
VAL_ 2566847230 ParkingBrakeActuator 3 "Not available" 2 "Error" 1 "Parking brake actuator active" 0 "Parking brake actuator inactive" ;
VAL_ 2359557886 DTCWarnLampSupportStatus 3 "Unavailable" 2 "Reserved" 1 "LampOn" 0 "LampOff" ;
VAL_ 2359557886 DTCWarnLampSupportFlash 3 "Unavailable" 2 "Reserved" 1 "FastFlash" 0 "SlowFlash" ;
VAL_ 2359557886 DTCStopLampSupportStatus 3 "Unavailable" 2 "Reserved" 1 "LampOn" 0 "LampOff" ;
VAL_ 2359557886 DTCStopLampSupportFlash 3 "Unavailable" 2 "Reserved" 1 "FastFlash" 0 "SlowFlash" ;
VAL_ 2359557886 DTCProtectLampSupportStatus 3 "Unavailable" 2 "Reserved" 1 "LampOn" 0 "LampOff" ;
VAL_ 2359557886 DTCProtectLampSupportFlash 3 "Unavailable" 2 "Reserved" 1 "FastFlash" 0 "SlowFlash" ;
VAL_ 2359557886 DTCMilSupportStatus 3 "Unavailable" 2 "ShortMI" 1 "LampOn" 0 "LampOff" ;
VAL_ 2359557886 DTCMilSupportFlash 3 "Unavailable" 2 "Class_C_DTC" 1 "FastFlash" 0 "SlowFlash" ;
VAL_ 2566736126 EngExhstGsOxygnSnsrClsdLpOprtnBn 15 "not supported" 4 "Closed loop but fault with at least one oxygen sensor  may be using single oxygen sensor for fuel control" 3 "Open loop  due to detected system fault" 2 "Open loop due to driving conditions eg power enrichment deceleration enleanment" 1 "Closed loop  using oxygen sensors as feedback for fuel control" 0 "Open loop  has not yet satisfied conditions to go closed loop" ;
VAL_ 2566736382 EngExhstGsOxygnSnsrClsdLpOprtnBn 15 "not supported" 4 "Closed loop but fault with at least one oxygen sensor  may be using single oxygen sensor for fuel control" 3 "Open loop  due to detected system fault" 2 "Open loop due to driving conditions eg power enrichment deceleration enleanment" 1 "Closed loop  using oxygen sensors as feedback for fuel control" 0 "Open loop  has not yet satisfied conditions to go closed loop" ;
VAL_ 2565874174 EngSpdSensor1TimingPatternStatus 3 "Not available" 2 "Error" 1 "OK" 0 "Not OK" ;
VAL_ 2565874174 EngSpdSensor2TimingPatternStatus 3 "Not available" 2 "Error" 1 "OK" 0 "Not OK" ;
VAL_ 2565874174 EngSpdSensor3TimingPatternStatus 3 "Not available" 2 "Error" 1 "OK" 0 "Not OK" ;
VAL_ 2432520958 EngCoolantThermostatMode 3 "dont care/reserved" 2 "reserved" 1 "position control mode used for service only" 0 "temperature control mode" ;
VAL_ 2566758398 Aftertreatment1AirEnableActuator 3 "not available" 2 "reserved for SAE assignment" 1 "active" 0 "not active" ;
VAL_ 2566758398 Aftertreatment1PurgeAirActuator 3 "not available" 2 "reserved for SAE assignment" 1 "active" 0 "not active" ;
VAL_ 2566758398 Aftrtrtmnt1AtmizationAirActuator 3 "not available" 2 "reserved for SAE assignment" 1 "active" 0 "not active" ;
VAL_ 2566758398 Aftertreatment1AirSystemRelay 3 "not available" 2 "reserved for SAE assignment" 1 "active" 0 "not active" ;
VAL_ 2566758910 Aftrtreatment1FuelEnableActuator 3 "not available" 2 "reserved for SAE assignment" 1 "active" 0 "not active" ;
VAL_ 2566758910 Aftrtreatment1RegenerationStatus 3 "not available" 2 "reserved for SAE assignment" 1 "active" 0 "not active" ;
VAL_ 2566758910 Aftertreatment1Ignt 3 "not available" 2 "reserved for SAE assignment" 1 "active" 0 "not active" ;
VAL_ 2566758910 Aftertreatment1FuelDrainActuator 3 "not available" 2 "reserved for SAE assignment" 1 "active" 0 "not active" ;
VAL_ 2566743550 Aftrtrtmnt1FlFlwDverterValveCtrl 3 "not available" 2 "reserved for SAE assignment" 1 "on" 0 "off" ;
VAL_ 2566743550 Aftertreatment1FuelPumpRelayCtrl 3 "not available" 2 "reserved for SAE assignment" 1 "on" 0 "off" ;
VAL_ 2565869310 NOxSensorATI1SelfdiagnosisStatus 7 "Not Supported" 4 "NOx Sensor ATI1 Self Diagnosis not possible" 3 "NOx Sensor ATI1 Self Diagnosis aborted" 2 "NOx Sensor ATI1 Self Diagnosis Result Complete" 1 "NOx Sensor ATI1 Self Diagnosis active flag" 0 "Diagnosis not active" ;
VAL_ 2565869310 Aftrtrtmnt1IntkGsSnsorHeaterCtrl 3 "Heater off" 2 "Preheat 1" 1 "Preheat 2" 0 "Automatic" ;
VAL_ 2565869310 Aftrtrtmnt1IntkWdRngO2RdngStable 3 "Not available" 2 "Error" 1 "Stable" 0 "Not stable" ;
VAL_ 2565869310 Aftrtrtmnt1IntkeNOxReadingStable 3 "Not available" 2 "Error" 1 "Stable" 0 "Not stable" ;
VAL_ 2565869310 Aftrtrtmnt1IntakeGasSensorAtTemp 3 "Not available" 2 "Error" 1 "In range" 0 "Not in range" ;
VAL_ 2565869310 Aftrtrtmnt1IntkGsSnsrPowerStatus 3 "Not available" 2 "Error" 1 "In range" 0 "Not in range" ;
VAL_ 2631728894 AntitheftModifyPwdStates 3 "Notvalid" 2 "EmptyOfPwdsThsSttIndctsThtCmpnn" 1 "FullofPwds" 0 "OkThsSttIndctsThtRqWsSccssfllyP" ;
VAL_ 2631728894 AntitheftComponentStatusStates 3 "Not defined" 2 "Blocked" 1 "Locked" 0 "Unlocked" ;
VAL_ 2631728894 AntitheftPwdValidIndicator 3 "Not available" 2 "Error" 1 "Password is a validated password" 0 "Password is not a validated password" ;
VAL_ 2631728894 AntthftEncryptnSdPrsentIndicator 3 "Not available" 2 "Error" 1 "Random number is present" 0 "Random number is not present" ;
VAL_ 2631794430 AntitheftCmdStates 5 "Login" 4 "CheckStatus" 3 "LockorUnlock" 2 "ChangePassword" 1 "DeletePassword" 0 "AddPassword" ;
VAL_ 2631794430 AntitheftDesiredExitModeStates 3 "NotAvailable" 2 "Not defined" 1 "LockWhenKeyOff" 0 "LockUponOperatorRequest" ;
VAL_ 2631794430 AntthftEncryptionIndicatorStates 3 "NotAvailable" 2 "Not defined" 1 "EncryptedCodePresent" 0 "EncryptionSeedRequest" ;
VAL_ 2365478910 ElctrncShckAbsrbrCtrlMdLft_TgAxl 3 "Not available" 2 "Error" 1 "Normal operation dampers active" 0 "Normal operation dampers passive" ;
VAL_ 2365478910 ElctrncShckAbsrbrCtrlMdeRearAxle 3 "Not available" 2 "Error" 1 "Normal operation dampers active" 0 "Normal operation dampers passive" ;
VAL_ 2365478910 ElctrncShckAbsrbrCtrlMdFrontAxle 3 "Not available" 2 "Error" 1 "Normal operation dampers active" 0 "Normal operation dampers passive" ;
VAL_ 2560950014 FailureModeIdentifier1 31 "Not available" 19 "Received network data in error" 18 "Below normal (moderately severe)" 17 "Below normal (least severe)" 16 "Above normal (moderately severe)" 15 "Above normal (least severe)" 14 "Special intstructions" 13 "Out of calibration" 12 "Bad intelligent device" 11 "Root cause not known" 10 "Abnormal rate of change" 9 "Abnormal update rate" 8 "Abnormal frequency" 7 "Mechanical system not responding" 6 "Current above normal" 5 "Current below normal" 4 "Voltage below normal" 3 "Voltage above normal" 2 "Data erratic" 1 "Below normal (most severe)" 0 "Above normal (most severe)" ;
VAL_ 2565869566 NOxSensorATO1SelfdiagnosisStatus 7 "Not Supported" 4 "NOx Sensor ATO1 Self Diagnosis not possible" 3 "NOx Sensor ATO1 Self Diagnosis aborted" 2 "NOx Sensor ATO1 Self Diagnosis Result Complete" 1 "NOx Sensor ATO1 Self Diagnosis active flag" 0 "Diagnosis not active" ;
VAL_ 2565869566 Aftrtrtmnt1OtltGsSnsorHeaterCtrl 3 "Heater off" 2 "Preheat 1" 1 "Preheat 2" 0 "Automatic" ;
VAL_ 2565869566 Aftrtrtmnt1OtltWdRngO2RdngStable 3 "Not available" 2 "Error" 1 "Stable" 0 "Not stable" ;
VAL_ 2565869566 Aftrtrtmnt1OtletNOxReadingStable 3 "Not available" 2 "Error" 1 "Stable" 0 "Not stable" ;
VAL_ 2565869566 Aftrtrtmnt1OutletGasSensorAtTemp 3 "Not available" 2 "Error" 1 "In range" 0 "Not in range" ;
VAL_ 2565869566 Aftrtrtmnt1OtltGsSnsrPowerStatus 3 "Not available" 2 "Error" 1 "In range" 0 "Not in range" ;
VAL_ 2566758142 Aftertreatment2AirEnableActuator 3 "not available" 2 "reserved for SAE assignment" 1 "active" 0 "not active" ;
VAL_ 2566758142 Aftertreatment2PurgeAirActuator 3 "not available" 2 "reserved for SAE assignment" 1 "active" 0 "not active" ;
VAL_ 2566758142 Aftrtrtmnt2AtmizationAirActuator 3 "not available" 2 "reserved for SAE assignment" 1 "active" 0 "not active" ;
VAL_ 2566758142 Aftertreatment2AirSystemRelay 3 "not available" 2 "reserved for SAE assignment" 1 "active" 0 "not active" ;
VAL_ 2566758654 Aftrtreatment2FuelEnableActuator 3 "not available" 2 "reserved for SAE assignment" 1 "active" 0 "not active" ;
VAL_ 2566758654 Aftrtreatment2RegenerationStatus 3 "not available" 2 "reserved for SAE assignment" 1 "active" 0 "not active" ;
VAL_ 2566758654 Aftertreatment2Ignt 3 "not available" 2 "reserved for SAE assignment" 1 "active" 0 "not active" ;
VAL_ 2566758654 Aftertreatment2FuelDrainActuator 3 "not available" 2 "reserved for SAE assignment" 1 "active" 0 "not active" ;
VAL_ 2565869822 NOxSensorATI2SelfdiagnosisStatus 7 "Not Supported" 4 "NOx Sensor ATI2 Self Diagnosis not possible" 3 "NOx Sensor ATI2 Self Diagnosis aborted" 2 "NOx Sensor ATI2 Self Diagnosis Result Complete" 1 "NOx Sensor ATI2 Self Diagnosis active flag" 0 "Diagnosis not active" ;
VAL_ 2565869822 Aftrtrtmnt2IntkGsSnsorHeaterCtrl 3 "Heater off" 2 "Preheat 1" 1 "Preheat 2" 0 "Automatic" ;
VAL_ 2565869822 Aftrtrtmnt2IntkWdRngO2RdngStable 3 "Not available" 2 "Error" 1 "Stable" 0 "Not stable" ;
VAL_ 2565869822 Aftrtrtmnt2IntkeNOxReadingStable 3 "Not available" 2 "Error" 1 "Stable" 0 "Not stable" ;
VAL_ 2565869822 Aftrtrtmnt2IntakeGasSensorAtTemp 3 "Not available" 2 "Error" 1 "In range" 0 "Not in range" ;
VAL_ 2565869822 Aftrtrtmnt2IntkGsSnsrPowerStatus 3 "Not available" 2 "Error" 1 "In range" 0 "Not in range" ;
VAL_ 2565870078 Aftrtrtmnt2OtltGsSnsorHeaterCtrl 3 "Heater off" 2 "Preheat 1" 1 "Preheat 2" 0 "Automatic" ;
VAL_ 2565870078 Aftrtrtmnt2OtltWdRngO2RdngStable 3 "Not available" 2 "Error" 1 "Stable" 0 "Not stable" ;
VAL_ 2565870078 Aftrtrtmnt2OtletNOxReadingStable 3 "Not available" 2 "Error" 1 "Stable" 0 "Not stable" ;
VAL_ 2565870078 NOxSensorATO2SelfdiagnosisStatus 7 "Not Supported" 4 "NOx Sensor ATO2 Self Diagnosis not possible" 3 "NOx Sensor ATO2 Self Diagnosis aborted" 2 "NOx Sensor ATO2 Self Diagnosis Result Complete" 1 "NOx Sensor ATO2 Self Diagnosis active flag" 0 "Diagnosis not active" ;
VAL_ 2565870078 Aftrtrtmnt2OutletGasSensorAtTemp 3 "Not available" 2 "Error" 1 "In range" 0 "Not in range" ;
VAL_ 2565870078 Aftrtrtmnt2OtltGsSnsrPowerStatus 3 "Not available" 2 "Error" 1 "In range" 0 "Not in range" ;
VAL_ 2365428478 EngStarterMotorRelayCtrl 3 "Don't care/take no action" 2 "Reserved for SAE assignment" 1 "On" 0 "Off" ;
VAL_ 2365428478 EngEmergencyShutdownIndication 3 "Dont care / take no action" 2 "Reserved" 1 "On Shutdown Requested" 0 "Off No Shutdown Requested" ;
VAL_ 2365428478 EngControlledShutdownRq 3 "Dont care / take no action" 2 "Reserved" 1 "On Shutdown Requested" 0 "Off No Shutdown Requested" ;
VAL_ 2365428478 EngCoolantCirculatingPumpCtrl 3 "Dont care / take no action" 2 "Reserved" 1 "On" 0 "Off" ;
VAL_ 2365428478 EngBlock_CoolantPreheaterCtrl 3 "Unavailable" 2 "Reserved" 1 "On" 0 "Off" ;
VAL_ 2365428478 EngElctrclSystmPwrCnsrvationCtrl 3 "Unavailable" 2 "Reserved" 1 "On" 0 "Off" ;
VAL_ 2365428478 EngOilPreheaterCtrl 3 "Dont care / take no action" 2 "Reserved" 1 "On" 0 "Off" ;
VAL_ 2365428478 EngOilPrimingPumpCtrl 3 "unavailable" 2 "Reserved" 1 "On" 0 "Off" ;
VAL_ 2365428478 EngFuelShutoffValveLeakTestCtrl 3 "Dont care / take no action" 2 "Reserved" 1 "On test in process / test complete" 0 "Off reset / no test in process" ;
VAL_ 2365428478 EngFuelShutoff2Ctrl 3 "Dont care / take no action" 2 "Reserved" 1 "Closed no fuel supplied to engine" 0 "Open fuel supplied to engine" ;
VAL_ 2365428478 EngFuelShutoff1Ctrl 3 "Dont care / take no action" 2 "Reserved" 1 "Closed no fuel supplied to engine" 0 "Open fuel supplied to engine" ;
VAL_ 2365428478 EngFuelShutoffVentCtrl 3 "Dont care / take no action" 2 "Reserved" 1 "Open vent open" 0 "Closed vent closed" ;
VAL_ 2365428478 FuelPumpPrimerCtrl 3 "Unavailable" 2 "Reserved" 1 "Activate" 0 "Deactivate" ;
VAL_ 2362638078 MemoryLevelRq 15 "Dont care" 14 "Reserved" 13 "Store Memory level  5" 12 "Store Memory level  4" 11 "Store Memory level  3" 10 "Store Memory level  2" 9 "Store Memory level  1" 8 "reserved" 7 "reserved" 6 "reserved" 5 "Memory level 5 request" 4 "Memory level 4 request" 3 "Memory level 3 request" 2 "Memory level 2 request" 1 "Memory level 1 request" 0 "No memory level request" ;
VAL_ 2362638078 PrhbitAutomaticAirSuspensionCtrl 3 "Not available" 2 "Error indicator" 1 "Request prohibit automatic air suspension control" 0 "No request" ;
VAL_ 2362638078 SpeedDependentLevelCtrlRq 3 "Dont care/take no action" 2 "Reserved" 1 "Activate" 0 "Deactivate" ;
VAL_ 2362638078 AllowLevelCtrlDuringBrakingCmd 3 "Dont care/take no action" 2 "Reserved" 1 "Allow level control during braking" 0 "Disallow level control during braking normal operation" ;
VAL_ 2362638078 ProhibitAirSuspensionCtrl 3 "Not available" 2 "Error indicator" 1 "Request prohibit air suspension control" 0 "No request" ;
VAL_ 2362638078 KneelingCmdRearAxle 3 "Dont care/take no action" 2 "Reserved" 1 "Activate kneeling" 0 "Deactivate kneeling" ;
VAL_ 2362638078 KneelingCmdFrontAxle 3 "Dont care/take no action" 2 "Reserved" 1 "Activate kneeling" 0 "Deactivate kneeling" ;
VAL_ 2362638078 LiftAxle2PosCmd 3 "Dont care/take no action" 2 "Reserved" 1 "Lift axle position up / tag axle unladen" 0 "Lift axle position down / tag axle laden" ;
VAL_ 2362638078 LiftAxle1PosCmd 3 "Dont care/take no action" 2 "Reserved" 1 "Lift axle position up / tag axle unladen" 0 "Lift axle position down / tag axle laden" ;
VAL_ 2362638078 LevelCtrlModeRq 15 "Dont care/take no action" 14 "Reserved" 9 "Force to bumper level" 8 "Exhaust bellows" 7 "Traction help  load reduce ie reduce axle load of driven axle to normal load condition" 6 "Optimum traction 2 ie the pressure at the driven axle is controlled at a fixed value 2" 5 "Optimum traction 1 ie the pressure at the driven axle is controlled at a fixed value 1" 4 "Pressure ratio 2 ie the ratio between the pressures at the driven axle and at the third axle is controlled so that" 3 "Pressure ratio 1 ie the ratio between the pressures at the driven axle and at the third axle is controlled so that" 2 "Load fixing ie the driven axle is loaded to a value defined by the driver" 1 "Traction help load transfer ie the driven axle is loaded to a maximum value given by legislation or design" 0 "Normal operation ie the system performs a pure control of the vehicle height" ;
VAL_ 2362638078 NominalLevelRqRearAxle 10 "Lower Request Continuously lowering front axle as long as active" 15 "Dont care/take no action" 14 "Reserved" 9 "Raise Request Continuously raising front axle as long as active" 8 "Stop level changeie the level change in process shall be stopped immediately" 7 "Lower Levelie the lowest level to be controlled" 6 "Upper Levelie the highest level to be controlled" 5 "Customer Levelie a level to be defined by customer via parameter setting" 4 "Preset Levelie a level to be defined externally via CAN" 3 "Normal Level 3ie a level permitted for driving for example to lift the vehicle in case of offroad" 2 "Normal Level 2ie a level permitted for driving for example to lower the vehicle in case of high speed" 1 "Normal Level 1ie the level prescribed for normal driving given by design" 0 "No level request" ;
VAL_ 2362638078 NominalLevelRqFrontAxle 10 "Lower Request Continuously lowering front axle as long as active" 15 "Dont care/take no action" 14 "Reserved" 9 "Raise Request Continuously raising front axle as long as active" 8 "Stop level changeie the level change in process shall be stopped immediately" 7 "Lower Levelie the lowest level to be controlled" 6 "Upper Levelie the highest level to be controlled" 5 "Customer Levelie a level to be defined by customer via parameter setting" 4 "Preset Levelie a level to be defined externally via CAN" 3 "Normal Level 3ie a level permitted for driving for example to lift the vehicle in case of offroad" 2 "Normal Level 2ie a level permitted for driving for example to lower the vehicle in case of high speed" 1 "Normal Level 1ie the level prescribed for normal driving given by design" 0 "No level request" ;
VAL_ 2362638078 KneelingCtrlModeRq 3 "Dont care/take no action" 2 "Reserved" 1 "Manually actuated" 0 "Automatically actuated" ;
VAL_ 2362638078 KneelingRqRightSide 3 "Dont care/take no action" 2 "Reserved" 1 "Kneeling request" 0 "No kneeling request" ;
VAL_ 2362638078 KneelingRqLeftSide 3 "Dont care/take no action" 2 "Reserved" 1 "Kneeling request" 0 "No kneeling request" ;
VAL_ 2362638078 AutomaticTractionHelp 3 "Dont care" 2 "Reserved" 1 "Enable automatic traction help" 0 "Disable automatic traction help" ;
VAL_ 2365479678 MemoryLevel 15 "not available" 14 "Error indicator" 13 "Memory level  5 stored" 12 "Memory level  4 stored" 11 "Memory level  3 stored" 10 "Memory level  2 stored" 9 "Memory level  1 stored" 8 "reserved" 7 "reserved" 6 "reserved" 5 "Memory level 5 selected" 4 "Memory level 4 selected" 3 "Memory level 3 selected" 2 "Memory level 2 selected" 1 "Memory level 1 selected" 0 "No memory level" ;
VAL_ 2365479678 SuspensionCtrlRefusalInformation 15 "Not available" 14 "Error" 7 "Requested level not available" 6 "General reject Ie no specified reason applies" 5 "Below speed limit" 4 "Above speed limit" 3 "Bogie differential not locked" 2 "Would exceed axle load limit tag axle" 1 "Axle load limit reached load transfer" 0 "Actual request not refused" ;
VAL_ 2365479678 SpeedDependantLevelCtrlStatus 3 "Dont care/take no action" 2 "Reserved" 1 "Active" 0 "Inactive" ;
VAL_ 2365479678 AllwLevelCtrlDuringBrakingStatus 3 "Dont care/take no action" 2 "Reserved" 1 "Activate" 0 "Deactivate" ;
VAL_ 2365479678 SuspensionRemoteCtrl2 3 "Not available" 2 "Error" 1 "Active" 0 "Not active" ;
VAL_ 2365479678 SuspensionRemoteCtrl1 3 "Not available" 2 "Error" 1 "Active" 0 "Not active" ;
VAL_ 2365479678 LiftAxle2Pos 3 "Not available" 2 "Error" 1 "Lift axle position up / tag axle unladen" 0 "Lift axle position down / tag axle laden" ;
VAL_ 2365479678 RearAxleInBumperRange 3 "Not available" 2 "Error" 1 "Actual level within bumper range" 0 "Actual level out of bumper range" ;
VAL_ 2365479678 FrontAxleInBumperRange 3 "Not available" 2 "Error" 1 "Actual level within bumper range" 0 "Actual level out of bumper range" ;
VAL_ 2365479678 LiftAxle1Pos 3 "Not available" 2 "Error" 1 "Lift axle position up / tag axle unladen" 0 "Lift axle position down / tag axle laden" ;
VAL_ 2365479678 DoorRelease 3 "Not available" 2 "Error" 1 "Doors may be opened" 0 "Doors may not be opened" ;
VAL_ 2365479678 VehicleMotionInhibit 3 "Not available" 2 "Error" 1 "Vehicle motion is inhibited" 0 "Vehicle may be moved" ;
VAL_ 2365479678 SecurityDevice 3 "Not available" 2 "Error" 1 "Active" 0 "Not active" ;
VAL_ 2365479678 LevelCtrlMode 11 "Force to bumper level request is in effect" 10 "Automatic air suspension control prohibited" 15 "Not available" 14 "Error" 9 "Air suspension control prohibited  ie hold current pressures in all suspension devices" 8 "Exhausting bellow function ie the bellows are exhausted totally" 7 "Traction help  load reduce ie the driven axle load is reduced to normal load condition" 6 "Optimum traction 2 ie the pressure at the driven axle is controlled at a fixed value 2" 5 "Optimum traction 1 ie the pressure at the driven axle is controlled at a fixed value 1" 4 "Pressure ratio 2 ie the ratio between the pressures at the driven axle and at the third axle is controlled so that" 3 "Pressure ratio 1 ie the ratio between the pressures at the driven axle and at the third axle is controlled so that" 2 "Load fixing ie the driven axlen is loaded to a value defined by the driver" 1 "Traction help load transfer ie the driven axle is loaded to a maximum value given by legislation or design" 0 "Normal operation ie the system performs a pure control of the vehicle height" ;
VAL_ 2365479678 KneelingInformation 15 "Not available" 14 "Error" 4 "Kneeling abortedie in case of manual actuation the request was dropped before the kneeling level was reached" 3 "Lifting activeie the vehicle is lifted due to a recover request" 2 "Kneeling level reachedie the vehicle is at the fixed kneeling level" 0 "Not activeie the kneeling function is not active" ;
VAL_ 2365479678 LiftingCtrlModeRearAxle 3 "Not available" 2 "Error" 1 "Lifting active" 0 "Lifting not active" ;
VAL_ 2365479678 LiftingCtrlModeFrontAxle 3 "Not available" 2 "Error" 1 "Lifting active" 0 "Lifting not active" ;
VAL_ 2365479678 LoweringCtrlModeRearAxle 3 "Not available" 2 "Error" 1 "Lowering active" 0 "Lowering not active" ;
VAL_ 2365479678 LoweringCtrlModeFrontAxle 3 "Not available" 2 "Error" 1 "Lowering active" 0 "Lowering not active" ;
VAL_ 2365479678 AboveNominalLevelRearAxle 3 "Not available" 2 "Error" 1 "Above" 0 "Not above" ;
VAL_ 2365479678 AboveNominalLevelFrontAxle 3 "Not available" 2 "Error" 1 "Above" 0 "Not above" ;
VAL_ 2365479678 BelowNominalLevelRearAxle 3 "Not available" 2 "Error" 1 "Below" 0 "Not below" ;
VAL_ 2365479678 BelowNominalLevelFrontAxle 3 "Not available" 2 "Error" 1 "Below" 0 "Not below" ;
VAL_ 2365479678 NominalLevelRearAxle 9 "Raising" 10 "Lowering" 15 "Not available" 14 "Error" 8 "Not defined" 7 "Lower Levelie the lowest level to be controlled" 6 "Upper Levelie the highest level to be controlled" 5 "Customer Levelie a level to be defined by customer via parameter setting" 4 "Preset Levelie a level to be defined externally via CAN" 3 "Normal Level 3ie a level permitted for driving for example to lift the vehicle in case of offroad" 2 "Normal Level 2ie a level permitted for driving for example to lower the vehicle in case of high speed" 1 "Normal Level 1ie the level prescribed for normal driving given by design" 0 "Level not specifiedie the nominal level is none of the specified levels no error condition" ;
VAL_ 2365479678 NominalLevelFrontAxle 9 "Raising" 10 "Lowering" 15 "Not available" 14 "Error" 8 "Not defined" 7 "Lower Levelie the lowest level to be controlled" 6 "Upper Levelie the highest level to be controlled" 5 "Customer Levelie a level to be defined by customer via parameter setting" 4 "Preset Levelie a level to be defined externally via CAN" 3 "Normal Level 3ie a level permitted for driving for example to lift the vehicle in case of offroad" 2 "Normal Level 2ie a level permitted for driving for example to lower the vehicle in case of high speed" 1 "Normal Level 1ie the level prescribed for normal driving given by design" 0 "Level not specifiedie the nominal level is none of the specified levels no error condition" ;
VAL_ 2566837758 Alt4Status 3 "not available" 2 "error" 1 "Alternator 4 charging" 0 "Alternator 4 not charging" ;
VAL_ 2566837758 Alt3Status 3 "not available" 2 "error" 1 "Alternator 3 charging" 0 "Alternator 3 not charging" ;
VAL_ 2566837758 Alt2Status 3 "not available" 2 "error" 1 "Alternator 2 charging" 0 "Alternator 2 not charging" ;
VAL_ 2566837758 Alt1Status 3 "not available" 2 "error" 1 "Alternator 1 charging" 0 "Alternator 1 not charging" ;
VAL_ 2365509886 TestIdentifier 250 "Last Measured Scaled Results" 249 "Command Standard Test" 247 "All scaled test results" ;
VAL_ 2363752190 TestIdentifier 250 "Last Measured Scaled Results" 249 "Command Standard Test" 247 "All scaled test results" ;
VAL_ 2363752190 FailureModeIdentifier1 31 "Not available" 19 "Received network data in error" 18 "Below normal (moderately severe)" 17 "Below normal (least severe)" 16 "Above normal (moderately severe)" 15 "Above normal (least severe)" 14 "Special intstructions" 13 "Out of calibration" 12 "Bad intelligent device" 11 "Root cause not known" 10 "Abnormal rate of change" 9 "Abnormal update rate" 8 "Abnormal frequency" 7 "Mechanical system not responding" 6 "Current above normal" 5 "Current below normal" 4 "Voltage below normal" 3 "Voltage above normal" 2 "Data erratic" 1 "Below normal (most severe)" 0 "Above normal (most severe)" ;
VAL_ 2566836222 FlashRedStopLamp 3 "Unavailable / Do Not Flash" 2 "Reserved" 1 "Fast Flash" 0 "Slow Flash" ;
VAL_ 2566836222 FlashProtectLamp 3 "Unavailable / Do Not Flash" 2 "Reserved" 1 "Fast Flash" 0 "Slow Flash" ;
VAL_ 2566836222 FlashMalfuncIndicatorLamp 3 "Unavailable / Do Not Flash" 2 "Reserved" 1 "Fast Flash" 0 "Slow Flash" ;
VAL_ 2566836222 FlashAmberWarningLamp 3 "Unavailable / Do Not Flash" 2 "Reserved" 1 "Fast Flash" 0 "Slow Flash" ;
VAL_ 2566836222 MalfunctionIndicatorLampStatus 3 "Not available" 2 "Reserved" 1 "Lamp on" 0 "Lamp off" ;
VAL_ 2566836222 RedStopLampState 3 "Not available" 2 "Reserved" 1 "Lamp on" 0 "Lamp off" ;
VAL_ 2566836222 AmberWarningLampStatus 3 "Not available" 2 "Reserved" 1 "Lamp on" 0 "Lamp off" ;
VAL_ 2566836222 ProtectLampStatus 3 "Not available" 2 "Reserved" 1 "Lamp on" 0 "Lamp off" ;
VAL_ 2365509374 MisfireMonitoringSupport 3 "Not available" 2 "Reserved" 1 "test supported" 0 "test not supported" ;
VAL_ 2365509374 OBDCompliance 10 "JOBD" 11 "JOBD and OBD II" 12 "JOBD and EOBD" 13 "JOBD, EOBD and OBD II" 14 "Heavy Duty Vehicles (EURO IV) B1" 15 "Heavy Duty Vehicles (EURO V) B2" 16 "Heavy Duty Vehicles (EURO EEC) C" 17 "EMD" 18 "EMD+" 19 "HD OBD P" 20 "HD OBD" 21 "WWH OBD" 22 "OBD II (California, ARB 07/08)" 23 "HD EOBD" 25 "OBD-M (SI-SD/I)" 6 "EOBD" 7 "EOBD and OBD II" 8 "EOBD and OBD" 9 "EOBD, OBD and OBD II" 5 "Not intended to meet OBD II req." 4 "OBD I" 3 "OBD and OBD II" 2 "OBD (Federal, EPA)" 1 "OBD II (California, ARB)" 0 "Reserver for assignment by SAE" ;
VAL_ 2365509374 SecondAirSystemMonStatus 1 "TestNotComplete" 0 "TestComplete" ;
VAL_ 2365509374 EvaporativeSystemMonStatus 1 "TestNotComplete" 0 "TestComplete" ;
VAL_ 2365509374 ACSystemRefrigerantMonStatus 1 "TestNotComplete" 0 "TestComplete" ;
VAL_ 2365509374 OxygenSensorHeaterMonStatus 1 "TestNotComplete" 0 "TestComplete" ;
VAL_ 2365509374 OxygenSensorMonStatus 1 "test not complete" 0 "test complete" ;
VAL_ 2365509374 EGRSystemMonitoringStatus 1 "TestNotComplete" 0 "TestComplete" ;
VAL_ 2365509374 CatalystMonStatus 0 "TestComplete" 1 "TestNotComplete" ;
VAL_ 2365509374 ColdStartAidSystemMonStatus 1 "TestNotComplete" 0 "TestComplete" ;
VAL_ 2365509374 HeatedCatalystMonStatus 1 "TestNotComplete" 0 "TestComplete" ;
VAL_ 2365509374 CatalystMonSupp 1 "TestSupported" 0 "TestNotSupported" ;
VAL_ 2365509374 ColdStartAidSystemMonSupp 1 "TestSupported" 0 "TestNotSupported" ;
VAL_ 2365509374 HeatedCatalystMonSupp 1 "TestSupported" 0 "TestNotSupported" ;
VAL_ 2365509374 EvaporativeSystemMonSupp 1 "TestSupported" 0 "TestNotSupported" ;
VAL_ 2365509374 SecondAirSystemMonSupp 1 "TestSupported" 0 "TestNotSupported" ;
VAL_ 2365509374 ACSystemRefrigerantMonSupp 1 "TestSupported" 0 "TestNotSupported" ;
VAL_ 2365509374 OxygenSensorMonSupp 1 "TestSupported" 0 "TestNotSupported" ;
VAL_ 2365509374 OxygenSensorHeaterMonSupp 1 "TestSupported" 0 "TestNotSupported" ;
VAL_ 2365509374 EGRSystemMonitoringSupp 1 "TestSupported" 0 "TestNotSupported" ;
VAL_ 2365509374 MisfireMonitoringStatus 1 "test not complete" 0 "test complete" ;
VAL_ 2365509374 ComprehensiveCompMonStatus 1 "test not complete" 0 "test complete" ;
VAL_ 2365509374 FuelSystemMonitoringStatus 1 "test not complete" 0 "test complete" ;
VAL_ 2365509374 ComprehensiveComponentMonSupp 3 "Not available" 2 "Reserved" 1 "test supported" 0 "test not supported" ;
VAL_ 2365509374 FuelSystemMonitoringSupport 1 "test supported" 0 "test not supported" ;
